VERSION ""

NS_ :

BS_:

BU_: DSAU vHS_M SHVU_RR DPSS AMP ICC RLPSM APSM RWPC RRHV RRPSM CGW_CCU APSS ATS RLHV FPM RDC PSM ASAU

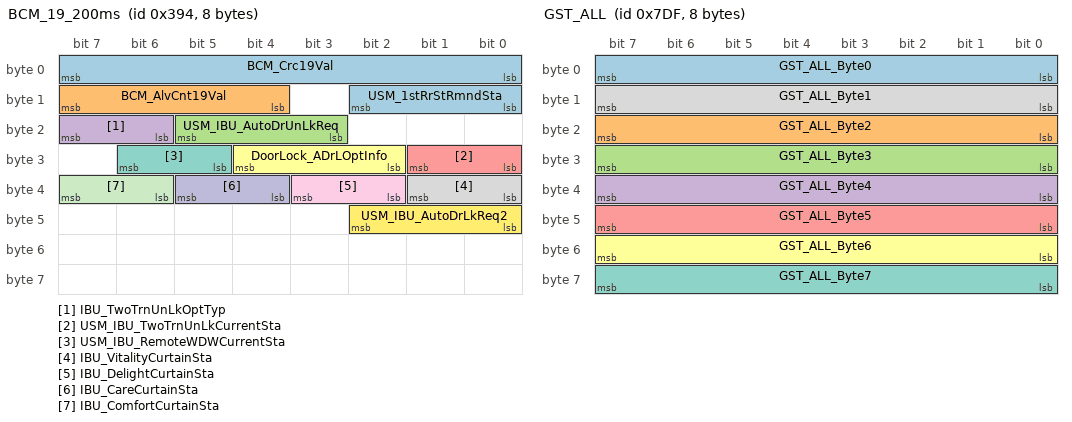
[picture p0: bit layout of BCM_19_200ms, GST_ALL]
BO_ 916 BCM_19_200ms: 8 CGW_CCU
 SG_ BCM_Crc19Val : 0|8@1+ (1,0) [0|0] ""  Vector__XXX
 SG_ BCM_AlvCnt19Val : 12|4@1+ (1,0) [0|0] ""  Vector__XXX
 SG_ USM_IBU_AutoDrUnLkReq : 19|3@1+ (1,0) [0|0] ""  Vector__XXX
 SG_ IBU_TwoTrnUnLkOptTyp : 22|2@1+ (1,0) [0|0] ""  Vector__XXX
 SG_ USM_IBU_TwoTrnUnLkCurrentSta : 24|2@1+ (1,0) [0|0] ""  Vector__XXX
 SG_ DoorLock_ADrLOptInfo : 26|3@1+ (1,0) [0|0] ""  Vector__XXX
 SG_ USM_IBU_RemoteWDWCurrentSta : 29|2@1+ (1,0) [0|0] ""  RDC
 SG_ IBU_VitalityCurtainSta : 32|2@1+ (1,0) [0|0] ""  RDC
 SG_ IBU_DelightCurtainSta : 34|2@1+ (1,0) [0|0] ""  RDC
 SG_ IBU_CareCurtainSta : 36|2@1+ (1,0) [0|0] ""  RDC
 SG_ IBU_ComfortCurtainSta : 38|2@1+ (1,0) [0|0] ""  RDC
 SG_ USM_IBU_AutoDrLkReq2 : 40|3@1+ (1,0) [0|0] ""  Vector__XXX
 SG_ USM_1stRrStRmndSta : 8|3@1+ (1,0) [0|0] ""  Vector__XXX

BO_ 2015 GST_ALL: 8 CGW_CCU
 SG_ GST_ALL_Byte0 : 0|8@1+ (1,0) [0|0] ""  RWPC,PSM,APSM,RLPSM,RRPSM,RLHV,RRHV,SHVU_RR,RDC,DPSS,AMP,vHS_M,APSS,FPM,ATS,DSAU,ASAU
 SG_ GST_ALL_Byte2 : 16|8@1+ (1,0) [0|0] ""  RWPC,PSM,APSM,RLPSM,RRPSM,RLHV,RRHV,SHVU_RR,RDC,DPSS,AMP,vHS_M,APSS,FPM,ATS,DSAU,ASAU
 SG_ GST_ALL_Byte3 : 24|8@1+ (1,0) [0|0] ""  RWPC,PSM,APSM,RLPSM,RRPSM,RLHV,RRHV,SHVU_RR,RDC,DPSS,AMP,vHS_M,APSS,FPM,ATS,DSAU,ASAU
 SG_ GST_ALL_Byte4 : 32|8@1+ (1,0) [0|0] ""  RWPC,PSM,APSM,RLPSM,RRPSM,RLHV,RRHV,SHVU_RR,RDC,DPSS,AMP,vHS_M,APSS,FPM,ATS,DSAU,ASAU
 SG_ GST_ALL_Byte5 : 40|8@1+ (1,0) [0|0] ""  RWPC,PSM,APSM,RLPSM,RRPSM,RLHV,RRHV,SHVU_RR,RDC,DPSS,AMP,vHS_M,APSS,FPM,ATS,DSAU,ASAU
 SG_ GST_ALL_Byte6 : 48|8@1+ (1,0) [0|0] ""  RWPC,PSM,APSM,RLPSM,RRPSM,RLHV,RRHV,SHVU_RR,RDC,DPSS,AMP,vHS_M,APSS,FPM,ATS,DSAU,ASAU
 SG_ GST_ALL_Byte7 : 56|8@1+ (1,0) [0|0] ""  RWPC,PSM,APSM,RLPSM,RRPSM,RLHV,RRHV,SHVU_RR,RDC,DPSS,AMP,vHS_M,APSS,FPM,ATS,DSAU,ASAU
 SG_ GST_ALL_Byte1 : 8|8@1+ (1,0) [0|0] ""  RWPC,PSM,APSM,RLPSM,RRPSM,RLHV,RRHV,SHVU_RR,RDC,DPSS,AMP,vHS_M,APSS,FPM,ATS,DSAU,ASAU

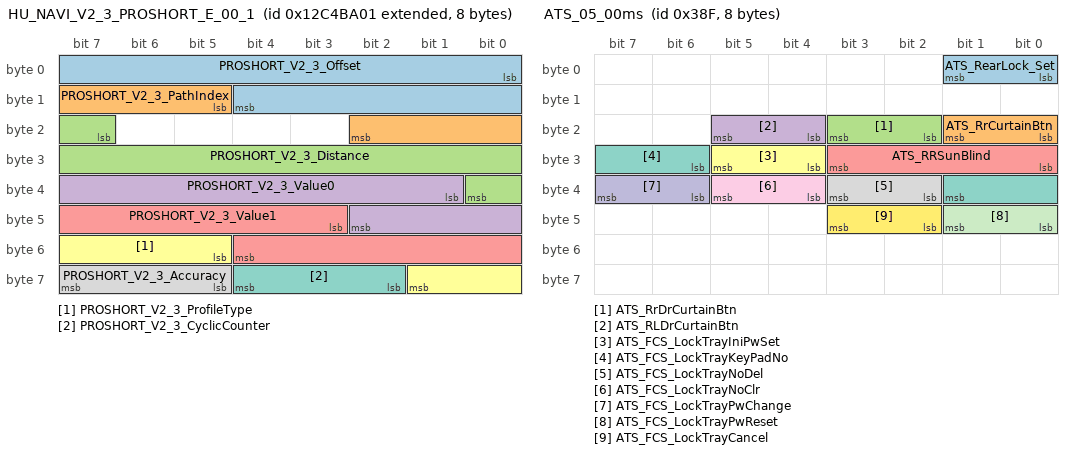
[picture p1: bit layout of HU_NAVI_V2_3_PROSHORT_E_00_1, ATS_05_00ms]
BO_ 2462366209 HU_NAVI_V2_3_PROSHORT_E_00_1: 8 CGW_CCU
 SG_ PROSHORT_V2_3_Offset : 0|13@1+ (1,0) [0|0] "m"  DSAU
 SG_ PROSHORT_V2_3_PathIndex : 13|6@1+ (1,0) [0|0] ""  Vector__XXX
 SG_ PROSHORT_V2_3_Distance : 23|10@1+ (1,0) [0|0] "m"  DSAU
 SG_ PROSHORT_V2_3_Value0 : 33|10@1+ (1,0) [0|0] ""  DSAU
 SG_ PROSHORT_V2_3_Value1 : 43|10@1+ (1,0) [0|0] ""  DSAU
 SG_ PROSHORT_V2_3_ProfileType : 53|5@1+ (1,0) [0|0] ""  DSAU
 SG_ PROSHORT_V2_3_CyclicCounter : 58|3@1+ (1,0) [0|0] ""  DSAU
 SG_ PROSHORT_V2_3_Accuracy : 61|3@1+ (1,0) [0|0] ""  Vector__XXX

BO_ 911 ATS_05_00ms: 8 ATS
 SG_ ATS_RearLock_Set : 0|2@1+ (1,0) [0|0] ""  CGW_CCU
 SG_ ATS_RrCurtainBtn : 16|2@1+ (1,0) [0|0] ""  CGW_CCU
 SG_ ATS_RrDrCurtainBtn : 18|2@1+ (1,0) [0|0] ""  RDC
 SG_ ATS_RLDrCurtainBtn : 20|2@1+ (1,0) [0|0] ""  RDC
 SG_ ATS_RRSunBlind : 24|4@1+ (1,0) [0|0] ""  CGW_CCU
 SG_ ATS_FCS_LockTrayIniPwSet : 28|2@1+ (1,0) [0|0] ""  Vector__XXX
 SG_ ATS_FCS_LockTrayKeyPadNo : 30|4@1+ (1,0) [0|0] ""  Vector__XXX
 SG_ ATS_FCS_LockTrayNoDel : 34|2@1+ (1,0) [0|0] ""  Vector__XXX
 SG_ ATS_FCS_LockTrayNoClr : 36|2@1+ (1,0) [0|0] ""  Vector__XXX
 SG_ ATS_FCS_LockTrayPwChange : 38|2@1+ (1,0) [0|0] ""  Vector__XXX
 SG_ ATS_FCS_LockTrayPwReset : 40|2@1+ (1,0) [0|0] ""  Vector__XXX
 SG_ ATS_FCS_LockTrayCancel : 42|2@1+ (1,0) [0|0] ""  Vector__XXX

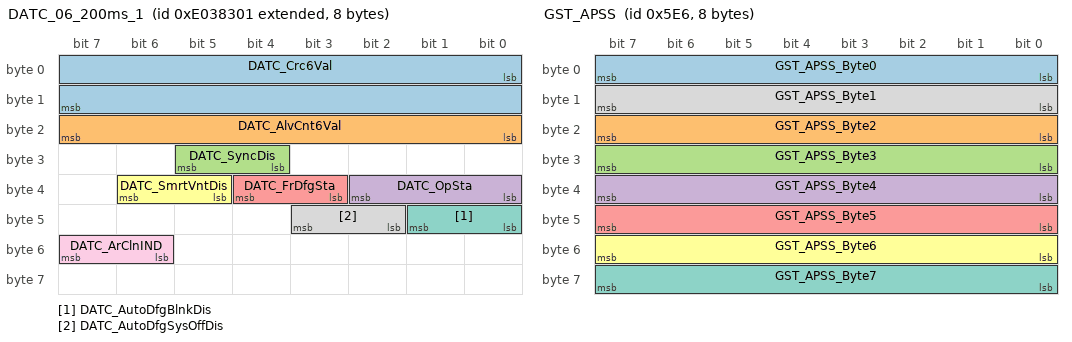
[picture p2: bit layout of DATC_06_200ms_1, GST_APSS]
BO_ 2382594817 DATC_06_200ms_1: 8 CGW_CCU
 SG_ DATC_Crc6Val : 0|16@1+ (1,0) [0|0] ""  Vector__XXX
 SG_ DATC_AlvCnt6Val : 16|8@1+ (1,0) [0|0] ""  Vector__XXX
 SG_ DATC_SyncDis : 28|2@1+ (1,0) [0|0] ""  ATS
 SG_ DATC_OpSta : 32|3@1+ (1,0) [0|0] ""  ATS
 SG_ DATC_FrDfgSta : 35|2@1+ (1,0) [0|0] ""  Vector__XXX
 SG_ DATC_SmrtVntDis : 37|2@1+ (1,0) [0|0] ""  Vector__XXX
 SG_ DATC_AutoDfgBlnkDis : 40|2@1+ (1,0) [0|0] ""  Vector__XXX
 SG_ DATC_AutoDfgSysOffDis : 42|2@1+ (1,0) [0|0] ""  Vector__XXX
 SG_ DATC_ArClnIND : 54|2@1+ (1,0) [0|0] ""  ATS

BO_ 1510 GST_APSS: 8 CGW_CCU
 SG_ GST_APSS_Byte0 : 0|8@1+ (1,0) [0|0] ""  vHS_M,APSS
 SG_ GST_APSS_Byte2 : 16|8@1+ (1,0) [0|0] ""  vHS_M,APSS
 SG_ GST_APSS_Byte3 : 24|8@1+ (1,0) [0|0] ""  vHS_M,APSS
 SG_ GST_APSS_Byte4 : 32|8@1+ (1,0) [0|0] ""  vHS_M,APSS
 SG_ GST_APSS_Byte5 : 40|8@1+ (1,0) [0|0] ""  vHS_M,APSS
 SG_ GST_APSS_Byte6 : 48|8@1+ (1,0) [0|0] ""  vHS_M,APSS
 SG_ GST_APSS_Byte7 : 56|8@1+ (1,0) [0|0] ""  vHS_M,APSS
 SG_ GST_APSS_Byte1 : 8|8@1+ (1,0) [0|0] ""  vHS_M,APSS

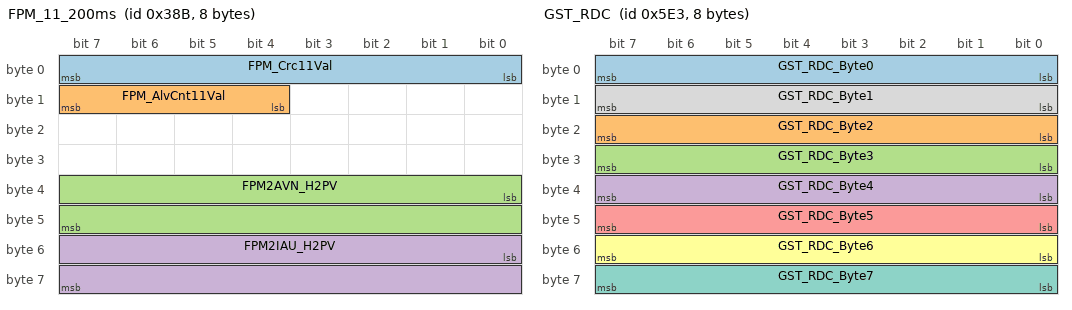
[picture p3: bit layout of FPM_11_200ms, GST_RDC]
BO_ 907 FPM_11_200ms: 8 FPM
 SG_ FPM_Crc11Val : 0|8@1+ (1,0) [0|0] ""  Vector__XXX
 SG_ FPM_AlvCnt11Val : 12|4@1+ (1,0) [0|0] ""  Vector__XXX
 SG_ FPM2AVN_H2PV : 32|16@1+ (1,0) [0|0] ""  CGW_CCU
 SG_ FPM2IAU_H2PV : 48|16@1+ (1,0) [0|0] ""  CGW_CCU

BO_ 905 SBCM_RR_01_200ms: 8 CGW_CCU
 SG_ SBCM_RR_Crc1Val : 0|8@1+ (1,0) [0|0] ""  Vector__XXX
 SG_ RR_CrashUnlockCmd : 10|1@1+ (1,0) [0|0] ""  Vector__XXX
 SG_ SBCM_RR_AlvCnt1Val : 12|4@1+ (1,0) [0|0] ""  Vector__XXX
 SG_ Warn_RrRtDrSwSta_SBCM : 16|2@1+ (1,0) [0|0] ""  RWPC,RLPSM,RRPSM,AMP,ATS
 SG_ DoorLock_RrRtDrUnLkSta_SBCM : 18|2@1+ (1,0) [0|0] ""  ATS
 SG_ RR_SEAActivated : 20|2@1+ (1,0) [0|0] ""  Vector__XXX
 SG_ RR_SEAWarn : 22|2@1+ (1,0) [0|0] ""  AMP
 SG_ RR_SEWWarn : 24|2@1+ (1,0) [0|0] ""  AMP
 SG_ RR_ReleaseWarn : 26|2@1+ (1,0) [0|0] ""  Vector__XXX
 SG_ RR_SWFailAlarm : 28|2@1+ (1,0) [0|0] ""  Vector__XXX
 SG_ RR_ChildLock_ActnFlSta : 30|2@1+ (1,0) [0|0] ""  Vector__XXX
 SG_ RR_MRActivationAlarm : 32|2@1+ (1,0) [0|0] ""  Vector__XXX
 SG_ RR_ChildLock_Status : 34|2@1+ (1,0) [0|0] ""  Vector__XXX
 SG_ USM_RRGhostDoorSta : 36|2@1+ (1,0) [0|0] ""  Vector__XXX
 SG_ DoorLock_PDSLkSwSta_RR : 40|2@1+ (1,0) [0|0] ""  AMP
 SG_ PDS_TypeOption_RR : 42|2@1+ (1,0) [0|0] ""  Vector__XXX
 SG_ SBCM_RrRrClsSwSta : 44|2@1+ (1,0) [0|0] ""  Vector__XXX
 SG_ RRDoorPushAlarm : 8|2@1+ (1,0) [0|0] ""  Vector__XXX

BO_ 1507 GST_RDC: 8 CGW_CCU
 SG_ GST_RDC_Byte0 : 0|8@1+ (1,0) [0|0] ""  RDC,vHS_M
 SG_ GST_RDC_Byte2 : 16|8@1+ (1,0) [0|0] ""  RDC,vHS_M
 SG_ GST_RDC_Byte3 : 24|8@1+ (1,0) [0|0] ""  RDC,vHS_M
 SG_ GST_RDC_Byte4 : 32|8@1+ (1,0) [0|0] ""  RDC,vHS_M
 SG_ GST_RDC_Byte5 : 40|8@1+ (1,0) [0|0] ""  RDC,vHS_M
 SG_ GST_RDC_Byte6 : 48|8@1+ (1,0) [0|0] ""  RDC,vHS_M
 SG_ GST_RDC_Byte7 : 56|8@1+ (1,0) [0|0] ""  RDC,vHS_M
 SG_ GST_RDC_Byte1 : 8|8@1+ (1,0) [0|0] ""  RDC,vHS_M

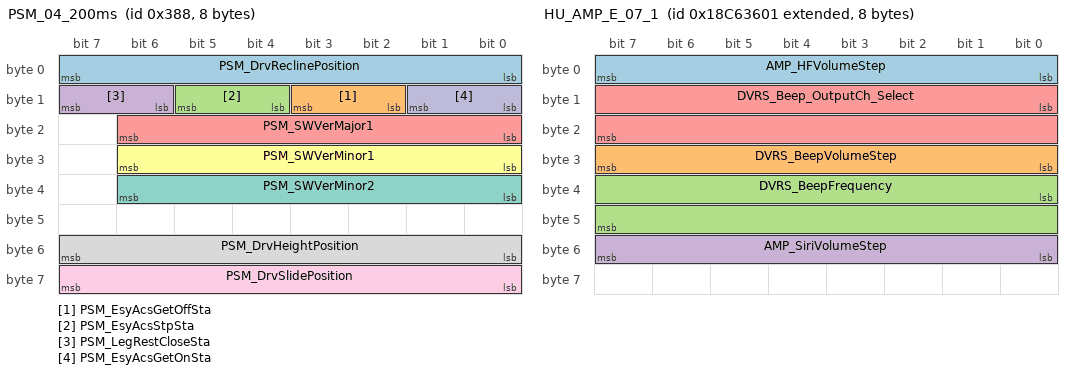
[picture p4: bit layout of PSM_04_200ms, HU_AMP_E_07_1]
BO_ 904 PSM_04_200ms: 8 PSM
 SG_ PSM_DrvReclinePosition : 0|8@1+ (1,0) [0|0] ""  RLPSM,CGW_CCU
 SG_ PSM_EsyAcsGetOffSta : 10|2@1+ (1,0) [0|0] ""  DSAU
 SG_ PSM_EsyAcsStpSta : 12|2@1+ (1,0) [0|0] ""  DSAU
 SG_ PSM_LegRestCloseSta : 14|2@1+ (1,0) [0|0] ""  RLPSM
 SG_ PSM_SWVerMajor1 : 16|7@1+ (1,0) [0|0] ""  CGW_CCU
 SG_ PSM_SWVerMinor1 : 24|7@1+ (1,0) [0|0] ""  CGW_CCU
 SG_ PSM_SWVerMinor2 : 32|7@1+ (1,0) [0|0] ""  CGW_CCU
 SG_ PSM_DrvHeightPosition : 48|8@1+ (1,0) [0|0] ""  CGW_CCU
 SG_ PSM_DrvSlidePosition : 56|8@1+ (1,0) [0|0] ""  RLPSM,CGW_CCU
 SG_ PSM_EsyAcsGetOnSta : 8|2@1+ (1,0) [0|0] ""  DSAU

BO_ 2563126785 HU_AMP_E_07_1: 8 CGW_CCU
 SG_ AMP_HFVolumeStep : 0|8@1+ (1,0) [0|0] ""  AMP
 SG_ DVRS_BeepVolumeStep : 24|8@1+ (1,0) [0|0] ""  AMP
 SG_ DVRS_BeepFrequency : 32|16@1+ (1,0) [0|0] "Hz"  AMP
 SG_ AMP_SiriVolumeStep : 48|8@1+ (1,0) [0|0] ""  AMP
 SG_ DVRS_Beep_OutputCh_Select : 8|16@1+ (1,0) [0|0] ""  AMP

BO_ 903 PSM_03_200ms: 8 PSM
 SG_ PSM_DrvStSldFwdDis : 0|2@1+ (1,0) [0|0] ""  DPSS,CGW_CCU
 SG_ PSM_DrvStTiltDnDis : 10|2@1+ (1,0) [0|0] ""  DPSS,CGW_CCU
 SG_ PSM_DrvStHghtUpDis : 12|2@1+ (1,0) [0|0] ""  DPSS,CGW_CCU
 SG_ PSM_DrvStHghtDnDis : 14|2@1+ (1,0) [0|0] ""  DPSS,CGW_CCU
 SG_ PSM_DrvStCushExtBckwdDis : 16|2@1+ (1,0) [0|0] ""  DPSS,CGW_CCU
 SG_ PSM_DrvStCushExtFwdDis : 18|2@1+ (1,0) [0|0] ""  DPSS,CGW_CCU
 SG_ PSM_DrvStSldBckwdDis : 2|2@1+ (1,0) [0|0] ""  DPSS,CGW_CCU
 SG_ PSM_DrvStHdRstUpDis : 20|2@1+ (1,0) [0|0] ""  CGW_CCU
 SG_ PSM_DrvStHdRstDnDis : 22|2@1+ (1,0) [0|0] ""  CGW_CCU
 SG_ PSM_DrvStHdRstFwdDis : 24|2@1+ (1,0) [0|0] ""  CGW_CCU
 SG_ PSM_DrvStHdRstBckwdDis : 26|2@1+ (1,0) [0|0] ""  CGW_CCU
 SG_ PSM_DrvStLmbrDefDis : 32|2@1+ (1,0) [0|0] ""  DPSS,CGW_CCU
 SG_ PSM_DrvStLmbrLoDis : 34|2@1+ (1,0) [0|0] ""  DPSS,CGW_CCU
 SG_ PSM_DrvStLmbrMdlDis : 36|2@1+ (1,0) [0|0] ""  DPSS,CGW_CCU
 SG_ PSM_DrvStLmbrUpDis : 38|2@1+ (1,0) [0|0] ""  DPSS,CGW_CCU
 SG_ PSM_DrvStReclneFwdDis : 4|2@1+ (1,0) [0|0] ""  DPSS,CGW_CCU
 SG_ PSM_LmbrSigSrcTyp : 44|2@1+ (1,0) [0|0] ""  CGW_CCU
 SG_ PSM_DrvStReclneBckwdDis : 6|2@1+ (1,0) [0|0] ""  DPSS,CGW_CCU
 SG_ PSM_DrvStTiltUpDis : 8|2@1+ (1,0) [0|0] ""  DPSS,CGW_CCU

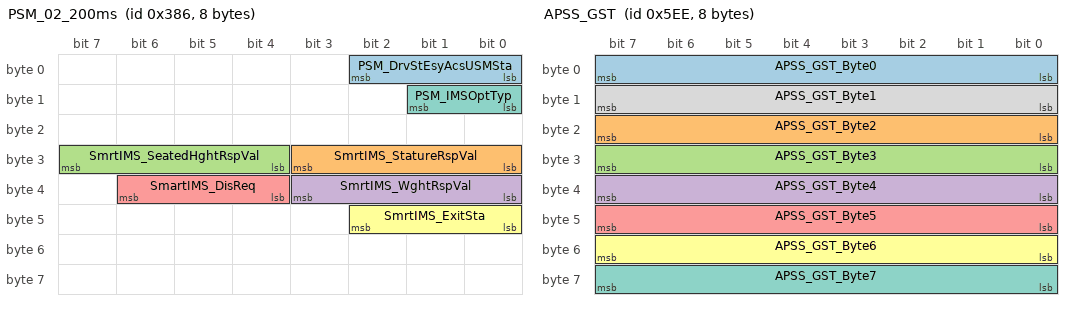
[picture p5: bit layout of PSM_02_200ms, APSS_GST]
BO_ 902 PSM_02_200ms: 8 PSM
 SG_ PSM_DrvStEsyAcsUSMSta : 0|3@1+ (1,0) [0|0] ""  DSAU,CGW_CCU
 SG_ SmrtIMS_StatureRspVal : 24|4@1+ (1,0) [0|0] ""  CGW_CCU
 SG_ SmrtIMS_SeatedHghtRspVal : 28|4@1+ (1,0) [0|0] ""  CGW_CCU
 SG_ SmrtIMS_WghtRspVal : 32|4@1+ (1,0) [0|0] ""  CGW_CCU
 SG_ SmartIMS_DisReq : 36|3@1+ (1,0) [0|0] ""  CGW_CCU
 SG_ SmrtIMS_ExitSta : 40|3@1+ (1,0) [0|0] ""  CGW_CCU
 SG_ PSM_IMSOptTyp : 8|2@1+ (1,0) [0|0] ""  CGW_CCU

BO_ 1518 APSS_GST: 8 vHS_M
 SG_ APSS_GST_Byte0 : 0|8@1+ (1,0) [0|0] ""  CGW_CCU
 SG_ APSS_GST_Byte2 : 16|8@1+ (1,0) [0|0] ""  CGW_CCU
 SG_ APSS_GST_Byte3 : 24|8@1+ (1,0) [0|0] ""  CGW_CCU
 SG_ APSS_GST_Byte4 : 32|8@1+ (1,0) [0|0] ""  CGW_CCU
 SG_ APSS_GST_Byte5 : 40|8@1+ (1,0) [0|0] ""  CGW_CCU
 SG_ APSS_GST_Byte6 : 48|8@1+ (1,0) [0|0] ""  CGW_CCU
 SG_ APSS_GST_Byte7 : 56|8@1+ (1,0) [0|0] ""  CGW_CCU
 SG_ APSS_GST_Byte1 : 8|8@1+ (1,0) [0|0] ""  CGW_CCU

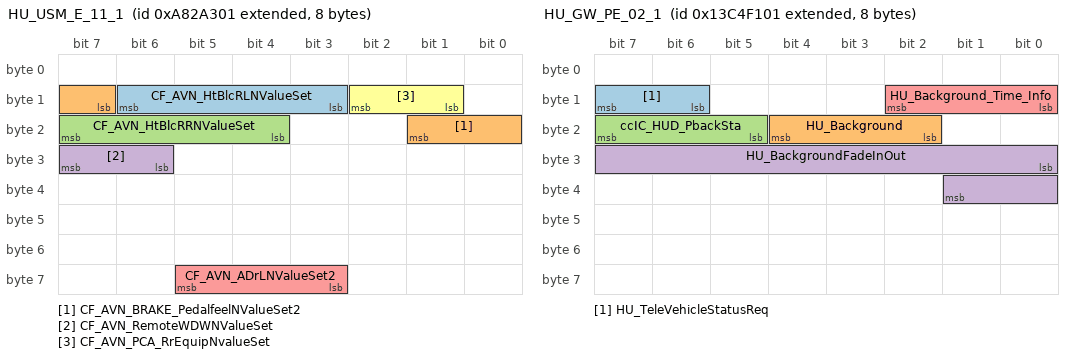
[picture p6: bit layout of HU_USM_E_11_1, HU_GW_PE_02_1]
BO_ 2323817217 HU_USM_E_11_1: 8 CGW_CCU
 SG_ CF_AVN_HtBlcRLNValueSet : 11|4@1+ (1,0) [0|0] ""  RLPSM,RRPSM,RLHV,SHVU_RR
 SG_ CF_AVN_BRAKE_PedalfeelNValueSet2 : 15|3@1+ (1,0) [0|0] ""  Vector__XXX
 SG_ CF_AVN_HtBlcRRNValueSet : 20|4@1+ (1,0) [0|0] ""  RLPSM,RRPSM,RRHV,SHVU_RR
 SG_ CF_AVN_RemoteWDWNValueSet : 30|2@1+ (1,0) [0|0] ""  Vector__XXX
 SG_ CF_AVN_ADrLNValueSet2 : 59|3@1+ (1,0) [0|0] ""  Vector__XXX
 SG_ CF_AVN_PCA_RrEquipNvalueSet : 9|2@1+ (1,0) [0|0] ""  Vector__XXX

BO_ 2479157505 HU_GW_PE_02_1: 8 CGW_CCU
 SG_ HU_TeleVehicleStatusReq : 14|2@1+ (1,0) [0|3] ""  Vector__XXX
 SG_ HU_Background : 18|3@1+ (1,0) [0|0] ""  ATS
 SG_ ccIC_HUD_PbackSta : 21|3@1+ (1,0) [0|0] ""  PSM
 SG_ HU_BackgroundFadeInOut : 24|10@1+ (0.1,0) [0|0] "%"  ATS
 SG_ HU_Background_Time_Info : 8|3@1+ (1,0) [0|0] ""  Vector__XXX

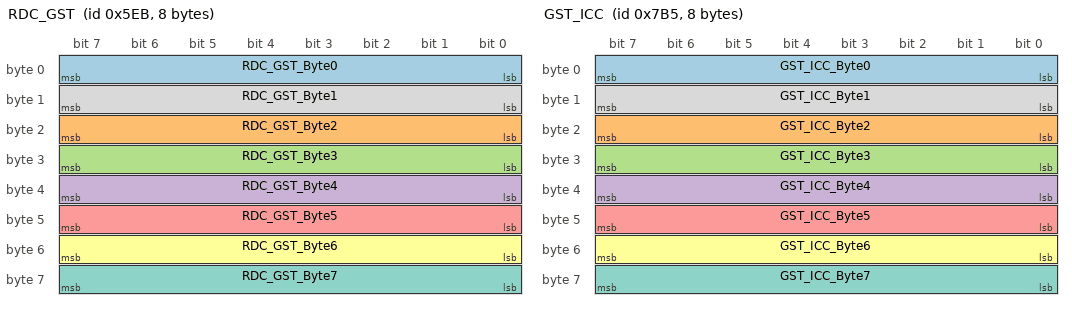
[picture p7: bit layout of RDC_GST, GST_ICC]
BO_ 1515 RDC_GST: 8 vHS_M
 SG_ RDC_GST_Byte0 : 0|8@1+ (1,0) [0|0] ""  CGW_CCU
 SG_ RDC_GST_Byte2 : 16|8@1+ (1,0) [0|0] ""  CGW_CCU
 SG_ RDC_GST_Byte3 : 24|8@1+ (1,0) [0|0] ""  CGW_CCU
 SG_ RDC_GST_Byte4 : 32|8@1+ (1,0) [0|0] ""  CGW_CCU
 SG_ RDC_GST_Byte5 : 40|8@1+ (1,0) [0|0] ""  CGW_CCU
 SG_ RDC_GST_Byte6 : 48|8@1+ (1,0) [0|0] ""  CGW_CCU
 SG_ RDC_GST_Byte7 : 56|8@1+ (1,0) [0|0] ""  CGW_CCU
 SG_ RDC_GST_Byte1 : 8|8@1+ (1,0) [0|0] ""  CGW_CCU

BO_ 1973 GST_ICC: 8 CGW_CCU
 SG_ GST_ICC_Byte0 : 0|8@1+ (1,0) [0|0] ""  vHS_M,ICC
 SG_ GST_ICC_Byte2 : 16|8@1+ (1,0) [0|0] ""  vHS_M,ICC
 SG_ GST_ICC_Byte3 : 24|8@1+ (1,0) [0|0] ""  vHS_M,ICC
 SG_ GST_ICC_Byte4 : 32|8@1+ (1,0) [0|0] ""  vHS_M,ICC
 SG_ GST_ICC_Byte5 : 40|8@1+ (1,0) [0|0] ""  vHS_M,ICC
 SG_ GST_ICC_Byte6 : 48|8@1+ (1,0) [0|0] ""  vHS_M,ICC
 SG_ GST_ICC_Byte7 : 56|8@1+ (1,0) [0|0] ""  vHS_M,ICC
 SG_ GST_ICC_Byte1 : 8|8@1+ (1,0) [0|0] ""  vHS_M,ICC

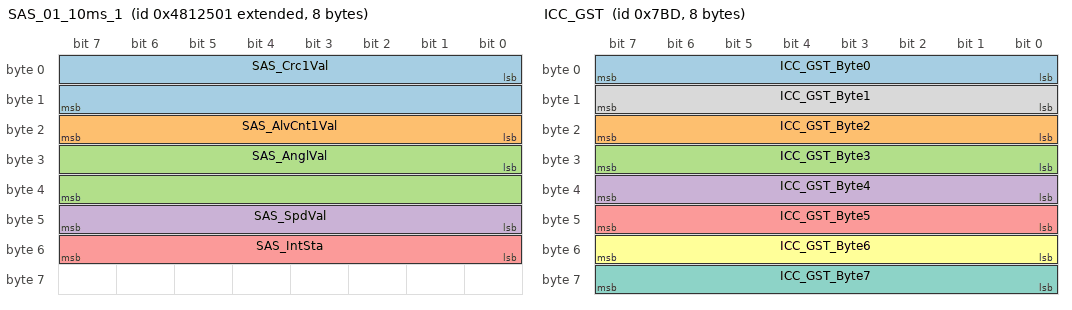
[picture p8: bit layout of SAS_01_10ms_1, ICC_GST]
BO_ 2223056129 SAS_01_10ms_1: 8 CGW_CCU
 SG_ SAS_Crc1Val : 0|16@1+ (1,0) [0|0] ""  Vector__XXX
 SG_ SAS_AlvCnt1Val : 16|8@1+ (1,0) [0|0] ""  Vector__XXX
 SG_ SAS_AnglVal : 24|16@1- (0.1,0) [0|0] "Deg"  ICC
 SG_ SAS_SpdVal : 40|8@1+ (4,0) [0|0] "Deg/s"  Vector__XXX
 SG_ SAS_IntSta : 48|8@1+ (1,0) [0|0] ""  Vector__XXX

BO_ 2223056130 SAS_01_10ms_2: 8 CGW_CCU

BO_ 1981 ICC_GST: 8 vHS_M
 SG_ ICC_GST_Byte0 : 0|8@1+ (1,0) [0|0] ""  CGW_CCU
 SG_ ICC_GST_Byte2 : 16|8@1+ (1,0) [0|0] ""  CGW_CCU
 SG_ ICC_GST_Byte3 : 24|8@1+ (1,0) [0|0] ""  CGW_CCU
 SG_ ICC_GST_Byte4 : 32|8@1+ (1,0) [0|0] ""  CGW_CCU
 SG_ ICC_GST_Byte5 : 40|8@1+ (1,0) [0|0] ""  CGW_CCU
 SG_ ICC_GST_Byte6 : 48|8@1+ (1,0) [0|0] ""  CGW_CCU
 SG_ ICC_GST_Byte7 : 56|8@1+ (1,0) [0|0] ""  CGW_CCU
 SG_ ICC_GST_Byte1 : 8|8@1+ (1,0) [0|0] ""  CGW_CCU

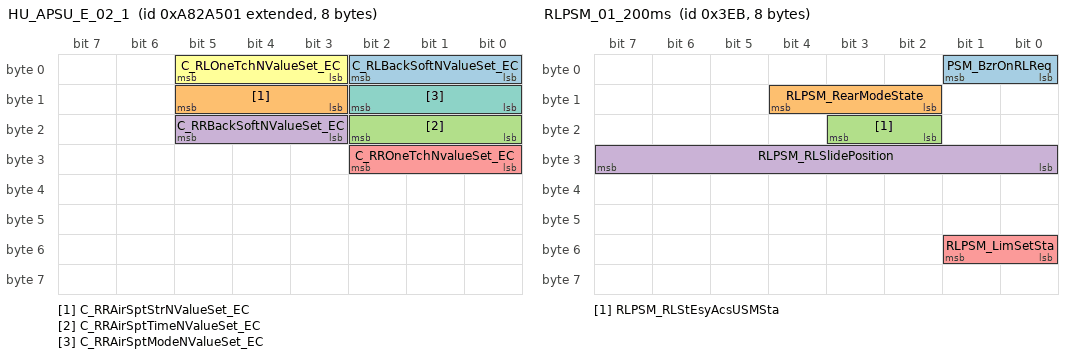
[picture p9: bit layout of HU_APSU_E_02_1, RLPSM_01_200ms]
BO_ 2323817729 HU_APSU_E_02_1: 8 CGW_CCU
 SG_ C_RLBackSoftNValueSet_EC : 0|3@1+ (1,0) [0|0] ""  RLPSM,ATS
 SG_ C_RRAirSptStrNValueSet_EC : 11|3@1+ (1,0) [0|0] ""  RLPSM,ATS
 SG_ C_RRAirSptTimeNValueSet_EC : 16|3@1+ (1,0) [0|0] ""  RLPSM,ATS
 SG_ C_RRBackSoftNValueSet_EC : 19|3@1+ (1,0) [0|0] ""  RLPSM,ATS
 SG_ C_RROneTchNvalueSet_EC : 24|3@1+ (1,0) [0|0] ""  RLPSM,RRPSM
 SG_ C_RLOneTchNValueSet_EC : 3|3@1+ (1,0) [0|0] ""  RLPSM,RRPSM
 SG_ C_RRAirSptModeNValueSet_EC : 8|3@1+ (1,0) [0|0] ""  RLPSM,ATS

BO_ 2458168065 HU_USM_E_04_1: 8 CGW_CCU
 SG_ CF_AVN_CluWelcomeSnd : 0|2@1+ (1,0) [0|0] ""  Vector__XXX
 SG_ CF_AVN_CluTransmissionDisp : 10|2@1+ (1,0) [0|0] ""  Vector__XXX
 SG_ CF_AVN_CluWiperLight : 12|2@1+ (1,0) [0|0] ""  Vector__XXX
 SG_ CF_AVN_CluRoadInfoGuide : 14|2@1+ (1,0) [0|0] ""  Vector__XXX
 SG_ CF_AVN_CluUserSettingPeriod : 17|7@1+ (1,0) [0|0] ""  Vector__XXX
 SG_ CF_AVN_CluAutoInitFuelEconomy : 2|3@1+ (1,0) [0|0] ""  Vector__XXX
 SG_ CF_AVN_CluSubspeedOdometerDisp : 25|2@1+ (1,0) [0|0] ""  Vector__XXX
 SG_ CF_AVN_CluFuelEconUnit_mi : 27|2@1+ (1,0) [0|0] ""  Vector__XXX
 SG_ CF_AVN_CluFuelEconUnit_km : 29|2@1+ (1,0) [0|0] ""  Vector__XXX
 SG_ CF_AVN_CluUserSettingDistance : 31|17@1+ (1,0) [0|0] ""  Vector__XXX
 SG_ CF_AVN_CluRheostatLvl : 49|5@1+ (1,0) [0|0] ""  Vector__XXX
 SG_ CF_AVN_CluVoiceVolume : 5|3@1+ (1,0) [0|0] ""  Vector__XXX
 SG_ CF_AVN_EVReset : 54|2@1+ (1,0) [0|0] ""  Vector__XXX
 SG_ CF_AVN_UnitReset : 56|2@1+ (1,0) [0|0] ""  Vector__XXX
 SG_ CF_AVN_IcyRoadWarn : 58|2@1+ (1,0) [0|0] ""  Vector__XXX
 SG_ CF_AVN_CluServiceReminderReset : 60|2@1+ (1,0) [0|0] ""  Vector__XXX
 SG_ CF_AVN_CluUSMReset : 62|2@1+ (1,0) [0|0] ""  RWPC,PSM,APSM,RLPSM,RRPSM,RLHV,RRHV,SHVU_RR,DPSS,APSS,ATS,DSAU,ASAU
 SG_ CF_AVN_CluServiceReminderSet : 8|2@1+ (1,0) [0|0] ""  Vector__XXX

BO_ 1003 RLPSM_01_200ms: 8 RLPSM
 SG_ PSM_BzrOnRLReq : 0|2@1+ (1,0) [0|0] ""  ATS,PSM
 SG_ RLPSM_RearModeState : 10|3@1+ (1,0) [0|0] ""  ATS,PSM,RDC,CGW_CCU
 SG_ RLPSM_RLStEsyAcsUSMSta : 18|2@1+ (1,0) [0|0] ""  ATS,CGW_CCU
 SG_ RLPSM_RLSlidePosition : 24|8@1+ (1,0) [0|0] ""  PSM
 SG_ RLPSM_LimSetSta : 48|2@1+ (1,0) [0|0] ""  ATS

BO_ 2449770241 HU_APSU_PE_01_1: 8 CGW_CCU
 SG_ C_AstRclBwdSw_HU : 0|2@1+ (1,0) [0|0] ""  APSM,RRPSM,APSS
 SG_ C_AstHeightUpSw_HU : 10|2@1+ (1,0) [0|0] ""  APSM,RRPSM,APSS
 SG_ C_AstTiltDnSw_HU : 12|2@1+ (1,0) [0|0] ""  APSM,APSS
 SG_ C_AstTiltUpSw_HU : 14|2@1+ (1,0) [0|0] ""  APSM,APSS
 SG_ C_AstLumbarDefSw_HU : 16|2@1+ (1,0) [0|0] ""  APSS,ASAU
 SG_ C_AstLumbarLowSw_HU : 18|2@1+ (1,0) [0|0] ""  APSS,ASAU
 SG_ C_AstRclFwdSw_HU : 2|2@1+ (1,0) [0|0] ""  APSM,RRPSM,APSS
 SG_ C_AstLumbarMidSw_HU : 20|2@1+ (1,0) [0|0] ""  APSS,ASAU
 SG_ C_AstLumbarUpSw_HU : 22|2@1+ (1,0) [0|0] ""  APSS,ASAU
 SG_ C_RRSlideFwdSw_HU : 24|2@1+ (1,0) [0|0] ""  RRPSM
 SG_ C_RRSlideBwdSw_HU : 26|2@1+ (1,0) [0|0] ""  RRPSM
 SG_ C_RLSlideFwdSw_HU : 28|2@1+ (1,0) [0|0] ""  RLPSM
 SG_ C_RLSlideBwdSw_HU : 30|2@1+ (1,0) [0|0] ""  RLPSM
 SG_ C_AstSlideBwdSw_HU : 4|2@1+ (1,0) [0|0] ""  APSM,RRPSM,APSS
 SG_ C_AstRlxNValueSet : 50|3@1+ (1,0) [0|0] ""  APSM,APSS
 SG_ C_AstSlideFwdSw_HU : 6|2@1+ (1,0) [0|0] ""  APSM,RRPSM,APSS
 SG_ C_AstHeightDnSw_HU : 8|2@1+ (1,0) [0|0] ""  APSM,RRPSM,APSS

BO_ 2470763265 CLU_10_00ms_1: 8 CGW_CCU
 SG_ USM_AdasDSWSetReq : 59|2@1+ (1,0) [0|0] ""  ICC

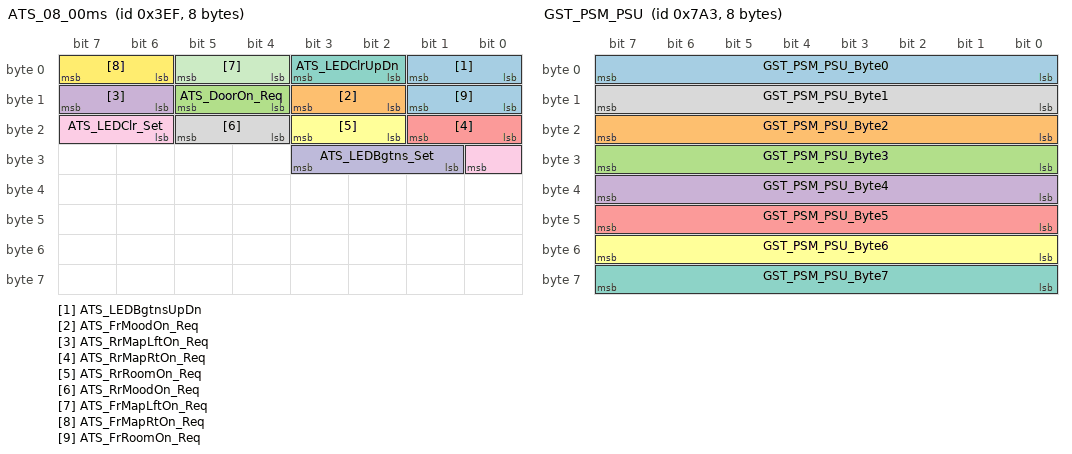
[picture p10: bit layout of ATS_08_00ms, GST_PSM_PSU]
BO_ 1007 ATS_08_00ms: 8 ATS
 SG_ ATS_LEDBgtnsUpDn : 0|2@1+ (1,0) [0|0] ""  CGW_CCU
 SG_ ATS_FrMoodOn_Req : 10|2@1+ (1,0) [0|0] ""  CGW_CCU
 SG_ ATS_DoorOn_Req : 12|2@1+ (1,0) [0|0] ""  CGW_CCU
 SG_ ATS_RrMapLftOn_Req : 14|2@1+ (1,0) [0|0] ""  CGW_CCU
 SG_ ATS_RrMapRtOn_Req : 16|2@1+ (1,0) [0|0] ""  CGW_CCU
 SG_ ATS_RrRoomOn_Req : 18|2@1+ (1,0) [0|0] ""  CGW_CCU
 SG_ ATS_LEDClrUpDn : 2|2@1+ (1,0) [0|0] ""  CGW_CCU
 SG_ ATS_RrMoodOn_Req : 20|2@1+ (1,0) [0|0] ""  CGW_CCU
 SG_ ATS_LEDClr_Set : 22|3@1+ (1,0) [0|0] ""  CGW_CCU
 SG_ ATS_LEDBgtns_Set : 25|3@1+ (1,0) [0|0] ""  CGW_CCU
 SG_ ATS_FrMapLftOn_Req : 4|2@1+ (1,0) [0|0] ""  CGW_CCU
 SG_ ATS_FrMapRtOn_Req : 6|2@1+ (1,0) [0|0] ""  CGW_CCU
 SG_ ATS_FrRoomOn_Req : 8|2@1+ (1,0) [0|0] ""  CGW_CCU

BO_ 1955 GST_PSM_PSU: 8 CGW_CCU
 SG_ GST_PSM_PSU_Byte0 : 0|8@1+ (1,0) [0|0] ""  PSM,vHS_M
 SG_ GST_PSM_PSU_Byte2 : 16|8@1+ (1,0) [0|0] ""  PSM,vHS_M
 SG_ GST_PSM_PSU_Byte3 : 24|8@1+ (1,0) [0|0] ""  PSM,vHS_M
 SG_ GST_PSM_PSU_Byte4 : 32|8@1+ (1,0) [0|0] ""  PSM,vHS_M
 SG_ GST_PSM_PSU_Byte5 : 40|8@1+ (1,0) [0|0] ""  PSM,vHS_M
 SG_ GST_PSM_PSU_Byte6 : 48|8@1+ (1,0) [0|0] ""  PSM,vHS_M
 SG_ GST_PSM_PSU_Byte7 : 56|8@1+ (1,0) [0|0] ""  PSM,vHS_M
 SG_ GST_PSM_PSU_Byte1 : 8|8@1+ (1,0) [0|0] ""  PSM,vHS_M

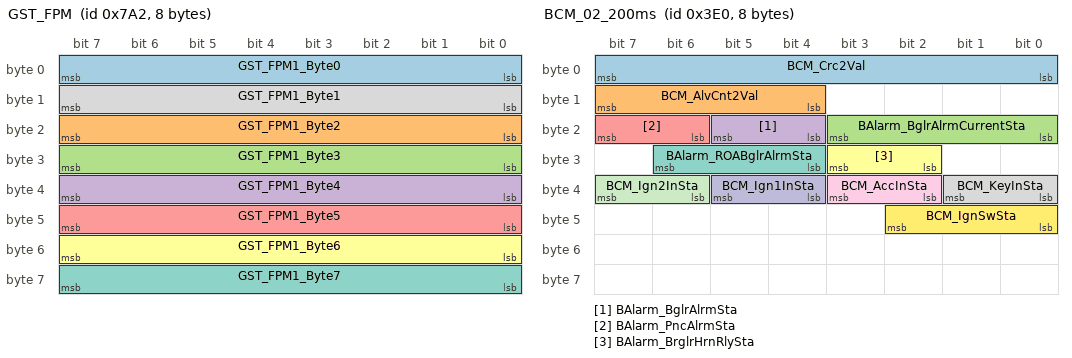
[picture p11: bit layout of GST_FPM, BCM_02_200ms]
BO_ 1954 GST_FPM: 8 CGW_CCU
 SG_ GST_FPM1_Byte0 : 0|8@1+ (1,0) [0|0] ""  vHS_M,FPM
 SG_ GST_FPM1_Byte2 : 16|8@1+ (1,0) [0|0] ""  vHS_M,FPM
 SG_ GST_FPM1_Byte3 : 24|8@1+ (1,0) [0|0] ""  vHS_M,FPM
 SG_ GST_FPM1_Byte4 : 32|8@1+ (1,0) [0|0] ""  vHS_M,FPM
 SG_ GST_FPM1_Byte5 : 40|8@1+ (1,0) [0|0] ""  vHS_M,FPM
 SG_ GST_FPM1_Byte6 : 48|8@1+ (1,0) [0|0] ""  vHS_M,FPM
 SG_ GST_FPM1_Byte7 : 56|8@1+ (1,0) [0|0] ""  vHS_M,FPM
 SG_ GST_FPM1_Byte1 : 8|8@1+ (1,0) [0|0] ""  vHS_M,FPM

BO_ 992 BCM_02_200ms: 8 CGW_CCU
 SG_ BCM_Crc2Val : 0|8@1+ (1,0) [0|0] ""  Vector__XXX
 SG_ BCM_AlvCnt2Val : 12|4@1+ (1,0) [0|0] ""  Vector__XXX
 SG_ BAlarm_BglrAlrmCurrentSta : 16|4@1+ (1,0) [0|0] ""  Vector__XXX
 SG_ BAlarm_BglrAlrmSta : 20|2@1+ (1,0) [0|0] ""  Vector__XXX
 SG_ BAlarm_PncAlrmSta : 22|2@1+ (1,0) [0|0] ""  Vector__XXX
 SG_ BAlarm_BrglrHrnRlySta : 26|2@1+ (1,0) [0|0] ""  Vector__XXX
 SG_ BAlarm_ROABglrAlrmSta : 28|3@1+ (1,0) [0|0] ""  Vector__XXX
 SG_ BCM_KeyInSta : 32|2@1+ (1,0) [0|0] ""  Vector__XXX
 SG_ BCM_AccInSta : 34|2@1+ (1,0) [0|0] ""  PSM,APSM,RLPSM,RRPSM,RDC,ATS,DSAU,ASAU
 SG_ BCM_Ign1InSta : 36|2@1+ (1,0) [0|0] ""  PSM,APSM,RLPSM,RRPSM,RDC,ATS,DSAU,ASAU
 SG_ BCM_Ign2InSta : 38|2@1+ (1,0) [0|0] ""  PSM,APSM,RLPSM,RRPSM,RLHV,RRHV,SHVU_RR,RDC,ATS,DSAU,ASAU
 SG_ BCM_IgnSwSta : 40|3@1+ (1,0) [0|0] ""  RWPC,PSM,APSM,RLPSM,RRPSM,SHVU_RR,RDC,DPSS,APSS,ATS,DSAU,ASAU

BO_TX_BU_ 1981 : vHS_M,ICC;
BO_TX_BU_ 1518 : vHS_M,APSS;
BO_TX_BU_ 1515 : vHS_M,RDC;
CM_ BO_ 1518 "[TP] Transport Protocol";
CM_ BO_ 911 "[EC] On Event and On Change";
CM_ SG_ 911 ATS_RearLock_Set "RRC and RSE Lock Touch Button";
CM_ SG_ 911 ATS_RrCurtainBtn "Rear Curtain Touch Button";
CM_ SG_ 911 ATS_RrDrCurtainBtn "Rear Door and Curtain Touch Button";
CM_ SG_ 911 ATS_RLDrCurtainBtn "Rear Door and Curtain Touch Button";
CM_ SG_ 911 ATS_RRSunBlind "SunBlind Touch Botton";
CM_ SG_ 911 ATS_FCS_LockTrayIniPwSet "Locking Tray 비밀번호 설정 진입 버튼";
CM_ SG_ 911 ATS_FCS_LockTrayKeyPadNo "Locking Tray 비밀번호 설정 key Pad 버튼";
CM_ SG_ 911 ATS_FCS_LockTrayNoDel "Locking Tray 비밀번호 설정 숫자 삭제 버튼";
CM_ SG_ 911 ATS_FCS_LockTrayNoClr "Locking Tray 비밀번호 설정 숫자 Clear 버튼";
CM_ SG_ 911 ATS_FCS_LockTrayPwChange "Locking Tray 비밀번호 변경 진입 버튼";
CM_ SG_ 911 ATS_FCS_LockTrayPwReset "Locking Tray 비밀번호 초기화 진입 버튼 (비밀번호 없는 상태로 원복)";
CM_ SG_ 911 ATS_FCS_LockTrayCancel "Locking Tray 비밀번호 입력 화면 Cancel 버튼";
CM_ BO_ 1007 "[EC] On Event and On Change";
CM_ SG_ 1007 ATS_LEDBgtnsUpDn "Interior Light Brightness Up/Down Request";
CM_ SG_ 1007 ATS_FrMoodOn_Req "Front mood lamp On/Off request";
CM_ SG_ 1007 ATS_DoorOn_Req "Front Door switch On/Off request";
CM_ SG_ 1007 ATS_RrMapLftOn_Req "Rear left map lamp On/Off request";
CM_ SG_ 1007 ATS_RrMapRtOn_Req "Rear right map lamp On/Off request";
CM_ SG_ 1007 ATS_RrRoomOn_Req "Rear room lamp On/Off request";
CM_ SG_ 1007 ATS_LEDClrUpDn "Interior Light Color Up/Down Request";
CM_ SG_ 1007 ATS_RrMoodOn_Req "Rear mood lamp On/Off request";
CM_ SG_ 1007 ATS_LEDClr_Set "Interior Lamp LED Color Request";
CM_ SG_ 1007 ATS_LEDBgtns_Set "Interior Lamp LED Brightness Request";
CM_ SG_ 1007 ATS_FrMapLftOn_Req "Front left map lamp On/Off request";
CM_ SG_ 1007 ATS_FrMapRtOn_Req "Front right map lamp On/Off request";
CM_ SG_ 1007 ATS_FrRoomOn_Req "Front room lamp On/Off request";
CM_ BO_ 992 "[PE] Periodic and On Event";
CM_ SG_ 992 BCM_Crc2Val "BCM_CyclicRedundancyCheck2Value";
CM_ SG_ 992 BCM_AlvCnt2Val "BCM_AliveCounter2Value";
CM_ SG_ 992 BAlarm_BglrAlrmCurrentSta "BAlarm_BuglarAlarmCurrentStatus ##2G##BCM - BCMmsg17 - C_BAlarmState";
CM_ SG_ 992 BAlarm_BglrAlrmSta "BAlarm_BuglarAlarmStatus ##2G##BCM - BCMmsg17 - C_BAState";
CM_ SG_ 992 BAlarm_PncAlrmSta "BAlarm_PanicAlarmStatus ##2G##BCM - BCMmsg17 - C_PanicState";
CM_ SG_ 992 BAlarm_BrglrHrnRlySta "BAlarm_BurglarHornRelayStatus ##2G##BCM - BCMmsg19 - C_BurglarHornRly";
CM_ SG_ 992 BAlarm_ROABglrAlrmSta "IBU→ ROA, EngineState Info Tx";
CM_ SG_ 992 BCM_KeyInSta "BCM_KeyInStatus ##2G##BCM - BCMmsg17 - C_KeyInSW";
CM_ SG_ 992 BCM_AccInSta "BCM_AccInputStatus ##2G##BCM - BCMmsg17 - C_Acc";
CM_ SG_ 992 BCM_Ign1InSta "BCM_Ignition1InputStatus ##2G##BCM - BCMmsg17 - C_Ign1";
CM_ SG_ 992 BCM_Ign2InSta "BCM_Ignition1InputStatus ##2G##BCM - BCMmsg17 - C_Ign2";
CM_ SG_ 992 BCM_IgnSwSta "BCM_IgnitionSwitchStatus ##2G##BCM - BCMmsg17 - C_IGNSw";
CM_ BO_ 916 "[PE] Periodic and On Event";
CM_ SG_ 916 BCM_Crc19Val "BCM_CyclicRedundancyCheck19Value";
CM_ SG_ 916 BCM_AlvCnt19Val "BCM_AliveCounter19Value";
CM_ SG_ 916 USM_IBU_AutoDrUnLkReq "USM_AutoDoorUnLockRequest ##2G## -  - CF_Gway_ADrURValue";
CM_ SG_ 916 IBU_TwoTrnUnLkOptTyp "USM_TwoTurnUnlockOptionType ##2G## -  - C_TTUnlockOption";
CM_ SG_ 916 USM_IBU_TwoTrnUnLkCurrentSta "USM_TwoTurnUnlockCurrentStatus ##2G## -  - CF_Gway_TTUnlockRValue";
CM_ SG_ 916 DoorLock_ADrLOptInfo "vehicle option information for auto door lock/unlock USM";
CM_ SG_ 916 USM_IBU_RemoteWDWCurrentSta "Remote Window IBU USM on/off function signal";
CM_ SG_ 916 USM_1stRrStRmndSta "Rear Occupant Alert IBU(1st Only) USM  On/Off Request signal";
CM_ BO_ 2470763265 "[EC] On Event and On Change";
CM_ SG_ 2470763265 USM_AdasDSWSetReq "USM_AdasDSWSetRequest";
CM_ BO_ 2382594817 "[PE] Periodic and On Event";
CM_ SG_ 2382594817 DATC_Crc6Val "DATC_CyclicRedundancyCheck6Value";
CM_ SG_ 2382594817 DATC_AlvCnt6Val "DATC_AliveCounter6Value";
CM_ SG_ 2382594817 DATC_SyncDis "DATC_SyncDisplay";
CM_ SG_ 2382594817 DATC_OpSta "DATC_OperationStatus";
CM_ SG_ 2382594817 DATC_FrDfgSta "DATC_FrontDefogStatus";
CM_ SG_ 2382594817 DATC_SmrtVntDis "DATC_SmartVentilationDisplay";
CM_ SG_ 2382594817 DATC_AutoDfgBlnkDis "DATC_AutoDefogBlinkDisplay";
CM_ SG_ 2382594817 DATC_AutoDfgSysOffDis "DATC_AutoDefogSystemOffDisplay";
CM_ SG_ 2382594817 DATC_ArClnIND "DATC_AirCleanIndicator";
CM_ BO_ 907 "[PE] Periodic and On Event";
CM_ SG_ 907 FPM_Crc11Val "FPM_CyclicRedundancyCheck11Value";
CM_ SG_ 907 FPM_AlvCnt11Val "FPM_AliveCounter11Value";
CM_ SG_ 907 FPM2AVN_H2PV "FPM2AVN_H2PV";
CM_ SG_ 907 FPM2IAU_H2PV "FPM2IAU_H2PV";
CM_ BO_ 2015 "[TP] Transport Protocol";
CM_ BO_ 1510 "[TP] Transport Protocol";
CM_ BO_ 1954 "[TP] Transport Protocol";
CM_ BO_ 1973 "[TP] Transport Protocol";
CM_ BO_ 1955 "[TP] Transport Protocol";
CM_ BO_ 1507 "[TP] Transport Protocol";
CM_ BO_ 2563126785 "[EC] On Event and On Change";
CM_ SG_ 2563126785 AMP_HFVolumeStep "Command for HF(Hands Free) Call Volume Setting
-range : 0 ~ max
-max : value of AMP_MaxHFVolumeState(0x084)
-This Signal's Feedback is AMP_HFVolumeState(0x084)@AMP";
CM_ SG_ 2563126785 AMP_SiriVolumeStep "Command for Siri Mode Volume Setting";
CM_ BO_ 2323817729 "[EC] On Event and On Change";
CM_ SG_ 2323817729 C_RLBackSoftNValueSet_EC "2nd Left Seat Back Softness";
CM_ SG_ 2323817729 C_RRAirSptStrNValueSet_EC "2nd Right side seat Smart Air Support Strength";
CM_ SG_ 2323817729 C_RRAirSptTimeNValueSet_EC "2nd Right side seat Smart Air Support Time";
CM_ SG_ 2323817729 C_RRBackSoftNValueSet_EC "2nd Right side seat Back Softness";
CM_ SG_ 2323817729 C_RROneTchNvalueSet_EC "2nd Right side seat One Touch Mode";
CM_ SG_ 2323817729 C_RLOneTchNValueSet_EC "2nd Left side seat One Touch Mode";
CM_ SG_ 2323817729 C_RRAirSptModeNValueSet_EC "2nd Right side seat Moving control : Smart Air Support Mode";
CM_ BO_ 2449770241 "[PE] Periodic and On Event";
CM_ SG_ 2449770241 C_AstRclBwdSw_HU "Assistant seat Moving control :Recline Backward";
CM_ SG_ 2449770241 C_AstHeightUpSw_HU "Assistant seat Moving control : Height Up";
CM_ SG_ 2449770241 C_AstTiltDnSw_HU "Assistant seat Moving control : Tilt Down";
CM_ SG_ 2449770241 C_AstTiltUpSw_HU "Assistant seat Moving Switch : Tilt Up";
CM_ SG_ 2449770241 C_AstLumbarDefSw_HU "Assistant seat moving switch: Deflate";
CM_ SG_ 2449770241 C_AstLumbarLowSw_HU "Assistant seat moving switch:Lumbar Low";
CM_ SG_ 2449770241 C_AstRclFwdSw_HU "Assistant seat Moving Switch : Recline Forward";
CM_ SG_ 2449770241 C_AstLumbarMidSw_HU "Assistant seat Moving control : Lumbar Mid";
CM_ SG_ 2449770241 C_AstLumbarUpSw_HU "Assistant seat Moving control : Lumbar Up";
CM_ SG_ 2449770241 C_RRSlideFwdSw_HU "2nd Right side seat Moving control :Power Slide Forward";
CM_ SG_ 2449770241 C_RRSlideBwdSw_HU "2nd Right side seat Moving control :Power Slide Backward";
CM_ SG_ 2449770241 C_RLSlideFwdSw_HU "2nd Left side seat Moving control :Power Slide Forward";
CM_ SG_ 2449770241 C_RLSlideBwdSw_HU "2nd Left side seat Moving control :Power Slide Backward";
CM_ SG_ 2449770241 C_AstSlideBwdSw_HU "Assistant seat moving switch : Slide Backward";
CM_ SG_ 2449770241 C_AstRlxNValueSet "Assistant seat Moving control : Relaxtion mode";
CM_ SG_ 2449770241 C_AstSlideFwdSw_HU "Assistant seat Moving switch : Slide Forward";
CM_ SG_ 2449770241 C_AstHeightDnSw_HU "Assistant seat Moving control : Height Down";
CM_ BO_ 2479157505 "[PE] Periodic and On Event";
CM_ SG_ 2479157505 HU_TeleVehicleStatusReq "Request vehicle status information.";
CM_ SG_ 2479157505 HU_Background "HU Backgound image info";
CM_ SG_ 2479157505 ccIC_HUD_PbackSta "Status signal for HUD interoperation with IMS";
CM_ SG_ 2479157505 HU_BackgroundFadeInOut "HU Background Fade in/out info - (HEX * Factor) %";
CM_ BO_ 2462366209 "[EC] On Event and On Change";
CM_ SG_ 2462366209 PROSHORT_V2_3_Offset "Information for Offset of position of the first profile spot from currnet position
-This Offset should be calculated using below Factors(according to Profile Type)
-Profile Type 1(Curvature): 1m
-Profile Type 4(Slope): 1m(PROSHORT_Accuracy=0x0), 3m(PROSHORT_Accuracy=0x2)
-Profile Type 16(Safety Driving Section): 1m(Section0,1,2,3,5)
-Refer to Specification(ES96523-31) for details";
CM_ SG_ 2462366209 PROSHORT_V2_3_PathIndex "Information for Index of the path where this profile is located";
CM_ SG_ 2462366209 PROSHORT_V2_3_Distance "Information for Distance from first profile spot to the second one
-This distance should be calculated using below Factors(according to Profile Type)
-Profile Type 1(Curvature): 2
-Profile Type 4(Slope): 2(PROSHORT_Accuracy=0x0), 20(PROSHORT_Accuracy=0x2)
-Profile Type 16(Safety Driving Section): 20(Section0,1), 2(Section2,3), 5(Section5)";
CM_ SG_ 2462366209 PROSHORT_V2_3_Value0 "Information for Profile Short value at Offset";
CM_ SG_ 2462366209 PROSHORT_V2_3_Value1 "Information for Profile Short value at Offset+Distance1";
CM_ SG_ 2462366209 PROSHORT_V2_3_ProfileType "Information for Profile Short Type: Slope(Linear) is used for Slope
-In case of Section Speed, transmitt Average Value of Speed Limit of Links in Section.
-Link without Speed Limit is excluded for Average Speed Calculation
-Unlimited Lane in Europe reflects 140kph for Average Speed Calculation";
CM_ SG_ 2462366209 PROSHORT_V2_3_CyclicCounter "Information for Cyclic counter of this message type and profile type: Reconstructor can use this value to detect missing messages.
-According to Profile Type, transmitt different Cyclic Counter Values
-In case of Slope, transmitt Cyclic Counter Values according to the Slope Transmitting Specification
 (Refer to 5.4 Slope Information Transmitting Scenario in Specification: It is about Information for Average Slope(Maximum 3) Transmitting by Event in forward unit distance(2km/20km) containing Current Location)
-In case of 'PROSHORT_CyclicCounter', transmitt particularly according to the 'PROSHORT_ProfileType'
 Ex) ProfileType(CyclicCounter): 0x1(0)  0x1(1)  0x10(0)  0x1(2)  0x10(1) ...";
CM_ SG_ 2462366209 PROSHORT_V2_3_Accuracy "Information for Accuracy of profile value is implementation specific.";
CM_ BO_ 2458168065 "[EC] On Event and On Change";
CM_ SG_ 2458168065 CF_AVN_CluWelcomeSnd "Request to set CLU welcome soun";
CM_ SG_ 2458168065 CF_AVN_CluTransmissionDisp "Request to set CLU transmission display";
CM_ SG_ 2458168065 CF_AVN_CluWiperLight "Request to set CLU wiper & light mode";
CM_ SG_ 2458168065 CF_AVN_CluRoadInfoGuide "Request to set CLU road info guidance";
CM_ SG_ 2458168065 CF_AVN_CluUserSettingPeriod "Request to set CLU sservice period set by user";
CM_ SG_ 2458168065 CF_AVN_CluAutoInitFuelEconomy "Request to set CLU auto initailizing fuel economy";
CM_ SG_ 2458168065 CF_AVN_CluSubspeedOdometerDisp "Request to set CLU Subscale Odometer";
CM_ SG_ 2458168065 CF_AVN_CluFuelEconUnit_mi "Cluster setting status for cluster Fuel Economy Unit (mile)";
CM_ SG_ 2458168065 CF_AVN_CluFuelEconUnit_km "Cluster setting status for cluster Fuel Economy unit (km)";
CM_ SG_ 2458168065 CF_AVN_CluUserSettingDistance "Request to set CLU service distance set by user";
CM_ SG_ 2458168065 CF_AVN_CluRheostatLvl "Request to set CLU rheostat level";
CM_ SG_ 2458168065 CF_AVN_CluVoiceVolume "Request to set CLU Volume level";
CM_ SG_ 2458168065 CF_AVN_EVReset "Request to reset EV Service (0x1 : EV USM Reset)";
CM_ SG_ 2458168065 CF_AVN_UnitReset "Request to reset Unit setting";
CM_ SG_ 2458168065 CF_AVN_IcyRoadWarn "Request to set CLU icy road warning";
CM_ SG_ 2458168065 CF_AVN_CluServiceReminderReset "Request to reset CLU service reminder";
CM_ SG_ 2458168065 CF_AVN_CluUSMReset "Request to reset all USM service";
CM_ SG_ 2458168065 CF_AVN_CluServiceReminderSet "Request to set CLU service notification";
CM_ BO_ 2323817217 "[EC] On Event and On Change";
CM_ SG_ 2323817217 CF_AVN_HtBlcRLNValueSet "Request for 2nd Left seat heater balance";
CM_ SG_ 2323817217 CF_AVN_HtBlcRRNValueSet "Request for 2nd Right seat heater balance";
CM_ SG_ 2323817217 CF_AVN_RemoteWDWNValueSet "Remote Window On/Off Set signal of USM for Fob Key";
CM_ SG_ 2323817217 CF_AVN_ADrLNValueSet2 "USM Request for Auto Door Lock";
CM_ SG_ 2323817217 CF_AVN_PCA_RrEquipNvalueSet "Headunit Setting signal for Rear Safety of USM";
CM_ BO_ 1981 "[TP] Transport Protocol";
CM_ BO_ 902 "[PE] Periodic and On Event";
CM_ SG_ 902 PSM_DrvStEsyAcsUSMSta "USM_MovingValue";
CM_ SG_ 902 SmrtIMS_StatureRspVal "HCIMS_HeightRsponseValue";
CM_ SG_ 902 SmrtIMS_SeatedHghtRspVal "HCIMS_SitHeightRsponseValue";
CM_ SG_ 902 SmrtIMS_WghtRspVal "HCIMS_WeightRsponseValue";
CM_ SG_ 902 SmartIMS_DisReq "PSM_MoveStatusDisplay";
CM_ SG_ 902 SmrtIMS_ExitSta "Smart IMS exit condition";
CM_ SG_ 902 PSM_IMSOptTyp "Option flag for IMS system";
CM_ BO_ 903 "[PE] Periodic and On Event";
CM_ SG_ 903 PSM_DrvStSldFwdDis "PSM_DriverSlideForwardDisplay";
CM_ SG_ 903 PSM_DrvStTiltDnDis "PSM_DriverTiltDownSwitchDisplay";
CM_ SG_ 903 PSM_DrvStHghtUpDis "PSM_DriverHeightUpSwitchDisplay";
CM_ SG_ 903 PSM_DrvStHghtDnDis "PSM_DriverHeightDownSwitchDisplay";
CM_ SG_ 903 PSM_DrvStCushExtBckwdDis "PSM_DriverCushionExtendedBackwardSwitchDisplay";
CM_ SG_ 903 PSM_DrvStCushExtFwdDis "PSM_DriverCushionExtendedForwardSwitchDisplay";
CM_ SG_ 903 PSM_DrvStSldBckwdDis "PSM_DriverSlideBackwardSwitchDisplay";
CM_ SG_ 903 PSM_DrvStHdRstUpDis "PSM_DriverHeadRestUpSwitchDisplay";
CM_ SG_ 903 PSM_DrvStHdRstDnDis "PSM_DriverHeadRestDownSwitchDisplay";
CM_ SG_ 903 PSM_DrvStHdRstFwdDis "PSM_DriverHeadRestForwardSwitchDisplay";
CM_ SG_ 903 PSM_DrvStHdRstBckwdDis "PSM_DriverHeadRestBackwardSwitchDisplay";
CM_ SG_ 903 PSM_DrvStLmbrDefDis "PSM_DriverLumbarDeFlateSwitchDisplay";
CM_ SG_ 903 PSM_DrvStLmbrLoDis "PSM_DriverLumbarLowSwitchDisplay";
CM_ SG_ 903 PSM_DrvStLmbrMdlDis "PSM_DriverLumbarMiddleSwitchDisplay";
CM_ SG_ 903 PSM_DrvStLmbrUpDis "PSM_DriverLumbarUpSwitchDisplay";
CM_ SG_ 903 PSM_DrvStReclneFwdDis "PSM_DriverSeatReclineForwardSwitchDisplay";
CM_ SG_ 903 PSM_LmbrSigSrcTyp "Lumbar Switch Signal Source(TX)";
CM_ SG_ 903 PSM_DrvStReclneBckwdDis "PSM_DriverSeatReclineBackwardSwitchDisplay";
CM_ SG_ 903 PSM_DrvStTiltUpDis "PSM_DriverTiltUpSwitchDisplay";
CM_ BO_ 904 "[PE] Periodic and On Event";
CM_ SG_ 904 PSM_EsyAcsGetOffSta "Easy Access Get Off Information";
CM_ SG_ 904 PSM_EsyAcsStpSta "Easy Access Stop Information";
CM_ SG_ 904 PSM_SWVerMajor1 "First Word(ASCII) in PSM S/W Ver";
CM_ SG_ 904 PSM_SWVerMinor1 "Second Word(ASCII) in PSM S/W Ver";
CM_ SG_ 904 PSM_SWVerMinor2 "Third Word(ASCII) in PSM S/W Ver";
CM_ SG_ 904 PSM_EsyAcsGetOnSta "Easy Access Get On Information";
CM_ BO_ 1515 "[TP] Transport Protocol";
CM_ BO_ 1003 "[PE] Periodic and On Event";
CM_ SG_ 1003 PSM_BzrOnRLReq "PSM_BuzzerOnRLRequest";
CM_ SG_ 1003 RLPSM_RLStEsyAcsUSMSta "RLPSM_USM_MovingValue";
CM_ SG_ 1003 RLPSM_LimSetSta "RLPSM limit setting state";
CM_ BO_ 2223056129 "[P] Periodic";
CM_ SG_ 2223056129 SAS_Crc1Val "SAS_CyclicRedundancyCheck1Value";
CM_ SG_ 2223056129 SAS_AlvCnt1Val "SAS_AliveCounter1Value";
CM_ SG_ 2223056129 SAS_AnglVal "SAS_AngleValue";
CM_ SG_ 2223056129 SAS_SpdVal "SAS_SpeedValue";
CM_ SG_ 2223056129 SAS_IntSta "SAS_InternalStatus";
CM_ BO_ 2223056130 "[P] Periodic";
CM_ BO_ 905 "[PE] Periodic and On Event";
CM_ SG_ 905 SBCM_RR_Crc1Val "SBCM_RR_CyclicRedundancyCheck1Value";
CM_ SG_ 905 RR_CrashUnlockCmd "Rear Right Crash Unlock Command";
CM_ SG_ 905 SBCM_RR_AlvCnt1Val "SBCM_RR_AliveCounter1Value";
CM_ SG_ 905 Warn_RrRtDrSwSta_SBCM "Warn_RearRightDoorSwitchStatus ##2G## -  - C_RRDrSw,CF_Gway_RRDrSw,Warn_RrRtDrSwSta";
CM_ SG_ 905 DoorLock_RrRtDrUnLkSta_SBCM "DoorLock_RearRightDoorUnLockStatus ##2G## -  - C_RRUnlockState,DoorLock_RrRtDrUnLkSta";
CM_ SG_ 905 RR_SEAActivated "Rear Right SEA Activated";
CM_ SG_ 905 RR_SEAWarn "Rear Righr SEA Warning";
BA_DEF_ BO_ "DiagState" ENUM "No","Yes" ;
BA_DEF_ BO_ "DiagResponse" ENUM "No","Yes" ;
BA_DEF_ BO_ "DiagRequest" ENUM "No","Yes" ;
BA_DEF_ BO_ "TpMessage" ENUM "No","Yes" ;
BA_DEF_ BO_ "UsrMsgIDSforwardDeviation" INT 0 100 ;
BA_DEF_ BO_ "UsrMsgIDSbackwardDeviation" INT 50 1000 ;
BA_DEF_ BO_ "GenMsgCycleTime" INT 0 2000 ;
BA_DEF_ BO_ "GenMsgStartDelayTime" INT 0 2000 ;
BA_DEF_ BO_ "GenMsgSendType" ENUM "Cyclic","NoMsgSendType" ;
BA_DEF_ BO_ "GenMsgCycleTimeFast" INT 0 500 ;
BA_DEF_ BO_ "GenMsgDelayTime" INT 0 20 ;
BA_DEF_ BO_ "GenMsgILSupport" ENUM "No","Yes" ;
BA_DEF_ BO_ "GenMsgNrOfRepetition" INT 0 3 ;
BA_DEF_ BO_ "NmMessage" ENUM "No","Yes" ;
BA_DEF_ BO_ "NWM-Botschaft" ENUM "No","Yes" ;
BA_DEF_ BO_ "TpTxIndex" INT 0 255 ;
BA_DEF_ BO_ "VFrameFormat" ENUM "StandardCAN","ExtendedCAN","reserved","reserved","reserved","reserved","reserved","reserved","reserved","reserved","reserved","reserved","reserved","reserved","StandardCAN_FD","ExtendedCAN_FD" ;
BA_DEF_ SG_ "UserSigValidity" ENUM "B+","ACC","IG","IG1","IG2","IG3","IG1 or IG2","IG1 or IG3","Undef" ;
BA_DEF_ SG_ "TimeoutValue" STRING ;
BA_DEF_ SG_ "UsrSigPurpose" ENUM "Undef","FN","DIAG","DIAG(Req)","DIAG(Res)","DIAG(Phy)","DEV","CCP(Req)","CCP(Res)","NM","TP" ;
BA_DEF_ SG_ "GenSigStartValue" INT 0 1215752192 ;
BA_DEF_ SG_ "NetworkRequest" ENUM "Yes","No" ;
BA_DEF_ SG_ "NetworkRequestHoldingTime" INT 0 65535 ;
BA_DEF_ SG_ "Description" STRING ;
BA_DEF_ SG_ "Version" STRING ;
BA_DEF_ SG_ "GenSigEnvVarType" ENUM "Int","Float","Undef" ;
BA_DEF_ SG_ "GenSigSendType" ENUM "Cyclic","OnWrite","OnWriteWithRepetition","OnChange","OnChangeWithRepetition","IfActive","IfActiveWithRepetition","NoSigSendType","OnChangeAndIfActive","OnChangeAndIfActiveWithRepetition" ;
BA_DEF_ SG_ "GwSigLatencyTime" INT 0 65536 ;
BA_DEF_ SG_ "GwSigMissingSourceType" ENUM "Undef","OldValue","DefaultValue","InitialValue" ;
BA_DEF_ SG_ "NWM-WakeupAllowed" ENUM "<n.a.>" ;
BA_DEF_ SG_ "RoutingFactor" INT 1 1215752192 ;
BA_DEF_REL_ BU_SG_REL_ "GenSigTimeoutTime" INT 0 7000 ;
BA_DEF_DEF_ "DiagState" "No" ;
BA_DEF_DEF_ "DiagResponse" "No" ;
BA_DEF_DEF_ "DiagRequest" "No" ;
BA_DEF_DEF_ "TpMessage" "No" ;
BA_DEF_DEF_ "UsrMsgIDSforwardDeviation" 10 ;
BA_DEF_DEF_ "UsrMsgIDSbackwardDeviation" 100 ;
BA_DEF_DEF_ "GenMsgCycleTime" 200 ;
BA_DEF_DEF_ "GenMsgStartDelayTime" 0 ;
BA_DEF_DEF_ "GenMsgSendType" "NoMsgSendType" ;
BA_DEF_DEF_ "GenMsgCycleTimeFast" 40 ;
BA_DEF_DEF_ "GenMsgDelayTime" 20 ;
BA_DEF_DEF_ "GenMsgILSupport" "Yes" ;
BA_DEF_DEF_ "GenMsgNrOfRepetition" 3 ;
BA_DEF_DEF_ "NmMessage" "No" ;
BA_DEF_DEF_ "NWM-Botschaft" "No" ;
BA_DEF_DEF_ "TpTxIndex" 0 ;
BA_DEF_DEF_ "VFrameFormat" "StandardCAN" ;
BA_DEF_DEF_ "UserSigValidity" "IG" ;
BA_DEF_DEF_ "TimeoutValue" "" ;
BA_DEF_DEF_ "UsrSigPurpose" "FN" ;
BA_DEF_DEF_ "GenSigStartValue" 0 ;
BA_DEF_DEF_ "NetworkRequest" "No" ;
BA_DEF_DEF_ "NetworkRequestHoldingTime" 0 ;
BA_DEF_DEF_ "Description" "" ;
BA_DEF_DEF_ "Version" "" ;
BA_DEF_DEF_ "GenSigEnvVarType" "Undef" ;
BA_DEF_DEF_ "GenSigSendType" "NoSigSendType" ;
BA_DEF_DEF_ "GwSigLatencyTime" 40 ;
BA_DEF_DEF_ "GwSigMissingSourceType" "Undef" ;
BA_DEF_DEF_ "NWM-WakeupAllowed" "<n.a.>" ;
BA_DEF_DEF_ "RoutingFactor" 1 ;
BA_DEF_DEF_REL_ "GenSigTimeoutTime" 500 ;
BA_ "GenMsgCycleTime" BO_ 1518 0;
BA_ "GenMsgCycleTimeFast" BO_ 1518 0;
BA_ "GenMsgNrOfRepetition" BO_ 1518 0;
BA_ "DiagResponse" BO_ 1518 1;
BA_ "GenMsgILSupport" BO_ 1518 0;
BA_ "TpMessage" BO_ 1518 1;
BA_ "TpTxIndex" BO_ 1518 108;
BA_ "Description" SG_ 1518 APSS_GST_Byte0 "TP Index : 108";
BA_ "UsrSigPurpose" SG_ 1518 APSS_GST_Byte0 4;
BA_ "UserSigValidity" SG_ 1518 APSS_GST_Byte0 0;
BA_REL_ "GenSigTimeoutTime" BU_SG_REL_ CGW_CCU SG_ 1518 APSS_GST_Byte0 0;
BA_ "NetworkRequest" SG_ 1518 APSS_GST_Byte0 0;
BA_ "NetworkRequestHoldingTime" SG_ 1518 APSS_GST_Byte0 5000;
BA_ "Version" SG_ 1518 APSS_GST_Byte0 "21.02.04";
BA_ "Description" SG_ 1518 APSS_GST_Byte2 "TP Index : 108";
BA_ "UsrSigPurpose" SG_ 1518 APSS_GST_Byte2 4;
BA_ "UserSigValidity" SG_ 1518 APSS_GST_Byte2 0;
BA_REL_ "GenSigTimeoutTime" BU_SG_REL_ CGW_CCU SG_ 1518 APSS_GST_Byte2 0;
BA_ "NetworkRequest" SG_ 1518 APSS_GST_Byte2 0;
BA_ "NetworkRequestHoldingTime" SG_ 1518 APSS_GST_Byte2 5000;
BA_ "Version" SG_ 1518 APSS_GST_Byte2 "21.02.04";
BA_ "Description" SG_ 1518 APSS_GST_Byte3 "TP Index : 108";
BA_ "UsrSigPurpose" SG_ 1518 APSS_GST_Byte3 4;
BA_ "UserSigValidity" SG_ 1518 APSS_GST_Byte3 0;
BA_REL_ "GenSigTimeoutTime" BU_SG_REL_ CGW_CCU SG_ 1518 APSS_GST_Byte3 0;
BA_ "NetworkRequest" SG_ 1518 APSS_GST_Byte3 0;
BA_ "NetworkRequestHoldingTime" SG_ 1518 APSS_GST_Byte3 5000;
BA_ "Version" SG_ 1518 APSS_GST_Byte3 "21.02.04";
BA_ "Description" SG_ 1518 APSS_GST_Byte4 "TP Index : 108";
BA_ "UsrSigPurpose" SG_ 1518 APSS_GST_Byte4 4;
BA_ "UserSigValidity" SG_ 1518 APSS_GST_Byte4 0;
BA_REL_ "GenSigTimeoutTime" BU_SG_REL_ CGW_CCU SG_ 1518 APSS_GST_Byte4 0;
BA_ "NetworkRequest" SG_ 1518 APSS_GST_Byte4 0;
BA_ "NetworkRequestHoldingTime" SG_ 1518 APSS_GST_Byte4 5000;
BA_ "Version" SG_ 1518 APSS_GST_Byte4 "21.02.04";
BA_ "Description" SG_ 1518 APSS_GST_Byte5 "TP Index : 108";
BA_ "UsrSigPurpose" SG_ 1518 APSS_GST_Byte5 4;
BA_ "UserSigValidity" SG_ 1518 APSS_GST_Byte5 0;
BA_REL_ "GenSigTimeoutTime" BU_SG_REL_ CGW_CCU SG_ 1518 APSS_GST_Byte5 0;
BA_ "NetworkRequest" SG_ 1518 APSS_GST_Byte5 0;
BA_ "NetworkRequestHoldingTime" SG_ 1518 APSS_GST_Byte5 5000;
BA_ "Version" SG_ 1518 APSS_GST_Byte5 "21.02.04";
BA_ "Description" SG_ 1518 APSS_GST_Byte6 "TP Index : 108";
BA_ "UsrSigPurpose" SG_ 1518 APSS_GST_Byte6 4;
BA_ "UserSigValidity" SG_ 1518 APSS_GST_Byte6 0;
BA_REL_ "GenSigTimeoutTime" BU_SG_REL_ CGW_CCU SG_ 1518 APSS_GST_Byte6 0;
BA_ "NetworkRequest" SG_ 1518 APSS_GST_Byte6 0;
BA_ "NetworkRequestHoldingTime" SG_ 1518 APSS_GST_Byte6 5000;
BA_ "Version" SG_ 1518 APSS_GST_Byte6 "21.02.04";
BA_ "Description" SG_ 1518 APSS_GST_Byte7 "TP Index : 108";
BA_ "UsrSigPurpose" SG_ 1518 APSS_GST_Byte7 4;
BA_ "UserSigValidity" SG_ 1518 APSS_GST_Byte7 0;
BA_REL_ "GenSigTimeoutTime" BU_SG_REL_ CGW_CCU SG_ 1518 APSS_GST_Byte7 0;
BA_ "NetworkRequest" SG_ 1518 APSS_GST_Byte7 0;
BA_ "NetworkRequestHoldingTime" SG_ 1518 APSS_GST_Byte7 5000;
BA_ "Version" SG_ 1518 APSS_GST_Byte7 "21.02.04";
BA_ "Description" SG_ 1518 APSS_GST_Byte1 "TP Index : 108";
BA_ "UsrSigPurpose" SG_ 1518 APSS_GST_Byte1 4;
BA_ "UserSigValidity" SG_ 1518 APSS_GST_Byte1 0;
BA_REL_ "GenSigTimeoutTime" BU_SG_REL_ CGW_CCU SG_ 1518 APSS_GST_Byte1 0;
BA_ "NetworkRequest" SG_ 1518 APSS_GST_Byte1 0;
BA_ "NetworkRequestHoldingTime" SG_ 1518 APSS_GST_Byte1 5000;
BA_ "Version" SG_ 1518 APSS_GST_Byte1 "21.02.04";
BA_ "GenMsgCycleTime" BO_ 911 0;
BA_ "Description" SG_ 911 ATS_RearLock_Set "RRC and RSE Lock Touch Button";
BA_ "GenSigSendType" SG_ 911 ATS_RearLock_Set 4;
BA_ "GenSigStartValue" SG_ 911 ATS_RearLock_Set 3;
BA_ "UserSigValidity" SG_ 911 ATS_RearLock_Set 3;
BA_REL_ "GenSigTimeoutTime" BU_SG_REL_ CGW_CCU SG_ 911 ATS_RearLock_Set 0;
BA_ "NetworkRequest" SG_ 911 ATS_RearLock_Set 0;
BA_ "NetworkRequestHoldingTime" SG_ 911 ATS_RearLock_Set 5000;
BA_ "Version" SG_ 911 ATS_RearLock_Set "20.07.08";
BA_ "Description" SG_ 911 ATS_RrCurtainBtn "Rear Curtain Touch Button";
BA_ "GenSigSendType" SG_ 911 ATS_RrCurtainBtn 4;
BA_ "UserSigValidity" SG_ 911 ATS_RrCurtainBtn 3;
BA_REL_ "GenSigTimeoutTime" BU_SG_REL_ CGW_CCU SG_ 911 ATS_RrCurtainBtn 0;
BA_ "NetworkRequest" SG_ 911 ATS_RrCurtainBtn 0;
BA_ "NetworkRequestHoldingTime" SG_ 911 ATS_RrCurtainBtn 5000;
BA_ "Version" SG_ 911 ATS_RrCurtainBtn "20.07.05";
BA_ "Description" SG_ 911 ATS_RrDrCurtainBtn "Rear Door and Curtain Touch Button";
BA_ "GenSigSendType" SG_ 911 ATS_RrDrCurtainBtn 4;
BA_ "UserSigValidity" SG_ 911 ATS_RrDrCurtainBtn 3;
BA_REL_ "GenSigTimeoutTime" BU_SG_REL_ RDC SG_ 911 ATS_RrDrCurtainBtn 0;
BA_ "NetworkRequest" SG_ 911 ATS_RrDrCurtainBtn 0;
BA_ "NetworkRequestHoldingTime" SG_ 911 ATS_RrDrCurtainBtn 5000;
BA_ "Version" SG_ 911 ATS_RrDrCurtainBtn "20.07.05";
BA_ "Description" SG_ 911 ATS_RLDrCurtainBtn "Rear Door and Curtain Touch Button";
BA_ "GenSigSendType" SG_ 911 ATS_RLDrCurtainBtn 4;
BA_ "UserSigValidity" SG_ 911 ATS_RLDrCurtainBtn 3;
BA_REL_ "GenSigTimeoutTime" BU_SG_REL_ RDC SG_ 911 ATS_RLDrCurtainBtn 0;
BA_ "NetworkRequest" SG_ 911 ATS_RLDrCurtainBtn 0;
BA_ "NetworkRequestHoldingTime" SG_ 911 ATS_RLDrCurtainBtn 5000;
BA_ "Version" SG_ 911 ATS_RLDrCurtainBtn "20.07.05";
BA_ "Description" SG_ 911 ATS_RRSunBlind "SunBlind Touch Botton";
BA_ "GenSigSendType" SG_ 911 ATS_RRSunBlind 4;
BA_ "UserSigValidity" SG_ 911 ATS_RRSunBlind 3;
BA_REL_ "GenSigTimeoutTime" BU_SG_REL_ CGW_CCU SG_ 911 ATS_RRSunBlind 0;
BA_ "NetworkRequest" SG_ 911 ATS_RRSunBlind 0;
BA_ "NetworkRequestHoldingTime" SG_ 911 ATS_RRSunBlind 5000;
BA_ "Version" SG_ 911 ATS_RRSunBlind "20.07.05";
BA_ "Description" SG_ 911 ATS_FCS_LockTrayIniPwSet "Locking Tray 비밀번호 설정 진입 버튼";
BA_ "GenSigSendType" SG_ 911 ATS_FCS_LockTrayIniPwSet 4;
BA_ "UserSigValidity" SG_ 911 ATS_FCS_LockTrayIniPwSet 3;
BA_ "NetworkRequest" SG_ 911 ATS_FCS_LockTrayIniPwSet 0;
BA_ "NetworkRequestHoldingTime" SG_ 911 ATS_FCS_LockTrayIniPwSet 5000;
BA_ "Version" SG_ 911 ATS_FCS_LockTrayIniPwSet "21.01.02";
BA_ "Description" SG_ 911 ATS_FCS_LockTrayKeyPadNo "Locking Tray 비밀번호 설정 key Pad 버튼";
BA_ "GenSigSendType" SG_ 911 ATS_FCS_LockTrayKeyPadNo 4;
BA_ "UserSigValidity" SG_ 911 ATS_FCS_LockTrayKeyPadNo 3;
BA_ "NetworkRequest" SG_ 911 ATS_FCS_LockTrayKeyPadNo 0;
BA_ "NetworkRequestHoldingTime" SG_ 911 ATS_FCS_LockTrayKeyPadNo 5000;
BA_ "Version" SG_ 911 ATS_FCS_LockTrayKeyPadNo "21.01.02";
BA_ "Description" SG_ 911 ATS_FCS_LockTrayNoDel "Locking Tray 비밀번호 설정 숫자 삭제 버튼";
BA_ "GenSigSendType" SG_ 911 ATS_FCS_LockTrayNoDel 4;
BA_ "UserSigValidity" SG_ 911 ATS_FCS_LockTrayNoDel 3;
BA_ "NetworkRequest" SG_ 911 ATS_FCS_LockTrayNoDel 0;
BA_ "NetworkRequestHoldingTime" SG_ 911 ATS_FCS_LockTrayNoDel 5000;
BA_ "Version" SG_ 911 ATS_FCS_LockTrayNoDel "21.01.02";
BA_ "Description" SG_ 911 ATS_FCS_LockTrayNoClr "Locking Tray 비밀번호 설정 숫자 Clear 버튼";
BA_ "GenSigSendType" SG_ 911 ATS_FCS_LockTrayNoClr 4;
BA_ "UserSigValidity" SG_ 911 ATS_FCS_LockTrayNoClr 3;
BA_ "NetworkRequest" SG_ 911 ATS_FCS_LockTrayNoClr 0;
BA_ "NetworkRequestHoldingTime" SG_ 911 ATS_FCS_LockTrayNoClr 5000;
BA_ "Version" SG_ 911 ATS_FCS_LockTrayNoClr "21.01.02";
BA_ "Description" SG_ 911 ATS_FCS_LockTrayPwChange "Locking Tray 비밀번호 변경 진입 버튼";
BA_ "GenSigSendType" SG_ 911 ATS_FCS_LockTrayPwChange 4;
BA_ "UserSigValidity" SG_ 911 ATS_FCS_LockTrayPwChange 3;
BA_ "NetworkRequest" SG_ 911 ATS_FCS_LockTrayPwChange 0;
BA_ "NetworkRequestHoldingTime" SG_ 911 ATS_FCS_LockTrayPwChange 5000;
BA_ "Version" SG_ 911 ATS_FCS_LockTrayPwChange "21.01.02";
BA_ "Description" SG_ 911 ATS_FCS_LockTrayPwReset "Locking Tray 비밀번호 초기화 진입 버튼 (비밀번호 없는 상태로 원복)";
BA_ "GenSigSendType" SG_ 911 ATS_FCS_LockTrayPwReset 4;
BA_ "UserSigValidity" SG_ 911 ATS_FCS_LockTrayPwReset 3;
BA_ "NetworkRequest" SG_ 911 ATS_FCS_LockTrayPwReset 0;
BA_ "NetworkRequestHoldingTime" SG_ 911 ATS_FCS_LockTrayPwReset 5000;
BA_ "Version" SG_ 911 ATS_FCS_LockTrayPwReset "21.01.02";
BA_ "Description" SG_ 911 ATS_FCS_LockTrayCancel "Locking Tray 비밀번호 입력 화면 Cancel 버튼";
BA_ "GenSigSendType" SG_ 911 ATS_FCS_LockTrayCancel 4;
BA_ "UserSigValidity" SG_ 911 ATS_FCS_LockTrayCancel 3;
BA_ "NetworkRequest" SG_ 911 ATS_FCS_LockTrayCancel 0;
BA_ "NetworkRequestHoldingTime" SG_ 911 ATS_FCS_LockTrayCancel 5000;
BA_ "Version" SG_ 911 ATS_FCS_LockTrayCancel "21.01.02";
BA_ "GenMsgCycleTime" BO_ 1007 0;
BA_ "Description" SG_ 1007 ATS_LEDBgtnsUpDn "This signal is  interior lamp brightness up/down control signal";
BA_ "GenSigSendType" SG_ 1007 ATS_LEDBgtnsUpDn 4;
BA_ "UserSigValidity" SG_ 1007 ATS_LEDBgtnsUpDn 3;
BA_REL_ "GenSigTimeoutTime" BU_SG_REL_ CGW_CCU SG_ 1007 ATS_LEDBgtnsUpDn 0;
BA_ "Version" SG_ 1007 ATS_LEDBgtnsUpDn "20.04.05";
BA_ "Description" SG_ 1007 ATS_FrMoodOn_Req "Front mood lamp On/Off request";
BA_ "GenSigSendType" SG_ 1007 ATS_FrMoodOn_Req 4;
BA_ "UserSigValidity" SG_ 1007 ATS_FrMoodOn_Req 3;
BA_REL_ "GenSigTimeoutTime" BU_SG_REL_ CGW_CCU SG_ 1007 ATS_FrMoodOn_Req 0;
BA_ "NetworkRequest" SG_ 1007 ATS_FrMoodOn_Req 0;
BA_ "NetworkRequestHoldingTime" SG_ 1007 ATS_FrMoodOn_Req 5000;
BA_ "Version" SG_ 1007 ATS_FrMoodOn_Req "20.06.09";
BA_ "Description" SG_ 1007 ATS_DoorOn_Req "Front Door switch On/Off request";
BA_ "GenSigSendType" SG_ 1007 ATS_DoorOn_Req 4;
BA_ "UserSigValidity" SG_ 1007 ATS_DoorOn_Req 3;
BA_REL_ "GenSigTimeoutTime" BU_SG_REL_ CGW_CCU SG_ 1007 ATS_DoorOn_Req 0;
BA_ "NetworkRequest" SG_ 1007 ATS_DoorOn_Req 0;
BA_ "NetworkRequestHoldingTime" SG_ 1007 ATS_DoorOn_Req 5000;
BA_ "Version" SG_ 1007 ATS_DoorOn_Req "20.06.09";
BA_ "Description" SG_ 1007 ATS_RrMapLftOn_Req "Rear left map lamp On/Off request";
BA_ "GenSigSendType" SG_ 1007 ATS_RrMapLftOn_Req 4;
BA_ "UserSigValidity" SG_ 1007 ATS_RrMapLftOn_Req 3;
BA_REL_ "GenSigTimeoutTime" BU_SG_REL_ CGW_CCU SG_ 1007 ATS_RrMapLftOn_Req 0;
BA_ "NetworkRequest" SG_ 1007 ATS_RrMapLftOn_Req 0;
BA_ "NetworkRequestHoldingTime" SG_ 1007 ATS_RrMapLftOn_Req 5000;
BA_ "Version" SG_ 1007 ATS_RrMapLftOn_Req "20.06.09";
BA_ "Description" SG_ 1007 ATS_RrMapRtOn_Req "Rear right map lamp On/Off request";
BA_ "GenSigSendType" SG_ 1007 ATS_RrMapRtOn_Req 4;
BA_ "UserSigValidity" SG_ 1007 ATS_RrMapRtOn_Req 3;
BA_REL_ "GenSigTimeoutTime" BU_SG_REL_ CGW_CCU SG_ 1007 ATS_RrMapRtOn_Req 0;
BA_ "NetworkRequest" SG_ 1007 ATS_RrMapRtOn_Req 0;
BA_ "NetworkRequestHoldingTime" SG_ 1007 ATS_RrMapRtOn_Req 5000;
BA_ "Version" SG_ 1007 ATS_RrMapRtOn_Req "20.06.09";
BA_ "Description" SG_ 1007 ATS_RrRoomOn_Req "Rear room lamp On/Off request";
BA_ "GenSigSendType" SG_ 1007 ATS_RrRoomOn_Req 4;
BA_ "UserSigValidity" SG_ 1007 ATS_RrRoomOn_Req 3;
BA_REL_ "GenSigTimeoutTime" BU_SG_REL_ CGW_CCU SG_ 1007 ATS_RrRoomOn_Req 0;
BA_ "NetworkRequest" SG_ 1007 ATS_RrRoomOn_Req 0;
BA_ "NetworkRequestHoldingTime" SG_ 1007 ATS_RrRoomOn_Req 5000;
BA_ "Version" SG_ 1007 ATS_RrRoomOn_Req "20.06.09";
BA_ "Description" SG_ 1007 ATS_LEDClrUpDn "This signal is  interior lamp color up/down control signal";
BA_ "GenSigSendType" SG_ 1007 ATS_LEDClrUpDn 4;
BA_ "UserSigValidity" SG_ 1007 ATS_LEDClrUpDn 3;
BA_REL_ "GenSigTimeoutTime" BU_SG_REL_ CGW_CCU SG_ 1007 ATS_LEDClrUpDn 0;
BA_ "Version" SG_ 1007 ATS_LEDClrUpDn "20.04.05";
BA_ "Description" SG_ 1007 ATS_RrMoodOn_Req "Rear mood lamp On/Off request";
BA_ "GenSigSendType" SG_ 1007 ATS_RrMoodOn_Req 4;
BA_ "UserSigValidity" SG_ 1007 ATS_RrMoodOn_Req 3;
BA_REL_ "GenSigTimeoutTime" BU_SG_REL_ CGW_CCU SG_ 1007 ATS_RrMoodOn_Req 0;
BA_ "NetworkRequest" SG_ 1007 ATS_RrMoodOn_Req 0;
BA_ "NetworkRequestHoldingTime" SG_ 1007 ATS_RrMoodOn_Req 5000;
BA_ "Version" SG_ 1007 ATS_RrMoodOn_Req "20.06.09";
BA_ "Description" SG_ 1007 ATS_LEDClr_Set "Interior Lamp LED Color Request";
BA_ "GenSigSendType" SG_ 1007 ATS_LEDClr_Set 4;
BA_ "UserSigValidity" SG_ 1007 ATS_LEDClr_Set 3;
BA_REL_ "GenSigTimeoutTime" BU_SG_REL_ CGW_CCU SG_ 1007 ATS_LEDClr_Set 0;
BA_ "NetworkRequest" SG_ 1007 ATS_LEDClr_Set 0;
BA_ "NetworkRequestHoldingTime" SG_ 1007 ATS_LEDClr_Set 5000;
BA_ "Version" SG_ 1007 ATS_LEDClr_Set "20.06.09";
BA_ "Description" SG_ 1007 ATS_LEDBgtns_Set "Interior Lamp LED Brightness Request";
BA_ "GenSigSendType" SG_ 1007 ATS_LEDBgtns_Set 4;
BA_ "UserSigValidity" SG_ 1007 ATS_LEDBgtns_Set 3;
BA_REL_ "GenSigTimeoutTime" BU_SG_REL_ CGW_CCU SG_ 1007 ATS_LEDBgtns_Set 0;
BA_ "NetworkRequest" SG_ 1007 ATS_LEDBgtns_Set 0;
BA_ "NetworkRequestHoldingTime" SG_ 1007 ATS_LEDBgtns_Set 5000;
BA_ "Version" SG_ 1007 ATS_LEDBgtns_Set "20.06.09";
BA_ "Description" SG_ 1007 ATS_FrMapLftOn_Req "Front left map lamp On/Off request";
BA_ "GenSigSendType" SG_ 1007 ATS_FrMapLftOn_Req 4;
BA_ "UserSigValidity" SG_ 1007 ATS_FrMapLftOn_Req 3;
BA_REL_ "GenSigTimeoutTime" BU_SG_REL_ CGW_CCU SG_ 1007 ATS_FrMapLftOn_Req 0;
BA_ "NetworkRequest" SG_ 1007 ATS_FrMapLftOn_Req 0;
BA_ "NetworkRequestHoldingTime" SG_ 1007 ATS_FrMapLftOn_Req 5000;
BA_ "Version" SG_ 1007 ATS_FrMapLftOn_Req "20.06.09";
BA_ "Description" SG_ 1007 ATS_FrMapRtOn_Req "Front right map lamp On/Off request";
BA_ "GenSigSendType" SG_ 1007 ATS_FrMapRtOn_Req 4;
BA_ "UserSigValidity" SG_ 1007 ATS_FrMapRtOn_Req 3;
BA_REL_ "GenSigTimeoutTime" BU_SG_REL_ CGW_CCU SG_ 1007 ATS_FrMapRtOn_Req 0;
BA_ "NetworkRequest" SG_ 1007 ATS_FrMapRtOn_Req 0;
BA_ "NetworkRequestHoldingTime" SG_ 1007 ATS_FrMapRtOn_Req 5000;
BA_ "Version" SG_ 1007 ATS_FrMapRtOn_Req "20.06.09";
BA_ "Description" SG_ 1007 ATS_FrRoomOn_Req "Front room lamp On/Off request";
BA_ "GenSigSendType" SG_ 1007 ATS_FrRoomOn_Req 4;
BA_ "UserSigValidity" SG_ 1007 ATS_FrRoomOn_Req 3;
BA_REL_ "GenSigTimeoutTime" BU_SG_REL_ CGW_CCU SG_ 1007 ATS_FrRoomOn_Req 0;
BA_ "NetworkRequest" SG_ 1007 ATS_FrRoomOn_Req 0;
BA_ "NetworkRequestHoldingTime" SG_ 1007 ATS_FrRoomOn_Req 5000;
BA_ "Version" SG_ 1007 ATS_FrRoomOn_Req "20.06.09";
BA_ "GenMsgSendType" BO_ 992 0;
BA_ "Description" SG_ 992 BCM_Crc2Val "The data area for CRC calculation is based on the data length (DLC) of the message DB.

The CRC shall be calculated over the entire data block (excluding the CRC bytes) including the user data, alive counter and Data ID 

 

- CRC Polynomial (0x1D) , Initial Value : 0x00, XOR value : 0xFF, Data ID Mode : Both, Data ID : Message ID + 0xF800 

- The initial value is for CRC calculation and the message should be sent with the calculated result value. 

The mathematical expression to 8 bit CRC polynomial is given here. G(x) = x8 + x4 + x3 + x2 + 1";
BA_ "GenSigSendType" SG_ 992 BCM_Crc2Val 4;
BA_ "GenSigStartValue" SG_ 992 BCM_Crc2Val 255;
BA_ "UserSigValidity" SG_ 992 BCM_Crc2Val 0;
BA_ "Version" SG_ 992 BCM_Crc2Val "18.11.08";
BA_ "Description" SG_ 992 BCM_AlvCnt2Val "For the first transmission request for a data element the counter shall be initialized with 0 and shall be incremented by 1

for every subsequent send request. When the counter reaches the maximum value(0xE), then it shall restart with 0 for the next send request";
BA_ "GenSigSendType" SG_ 992 BCM_AlvCnt2Val 4;
BA_ "UserSigValidity" SG_ 992 BCM_AlvCnt2Val 0;
BA_ "Version" SG_ 992 BCM_AlvCnt2Val "18.11.08";
BA_ "GenSigSendType" SG_ 992 BAlarm_BglrAlrmCurrentSta 4;
BA_ "UserSigValidity" SG_ 992 BAlarm_BglrAlrmCurrentSta 0;
BA_ "NetworkRequest" SG_ 992 BAlarm_BglrAlrmCurrentSta 0;
BA_ "NetworkRequestHoldingTime" SG_ 992 BAlarm_BglrAlrmCurrentSta 5000;
BA_ "Version" SG_ 992 BAlarm_BglrAlrmCurrentSta "17.12.00";
BA_ "GenSigSendType" SG_ 992 BAlarm_BglrAlrmSta 4;
BA_ "UserSigValidity" SG_ 992 BAlarm_BglrAlrmSta 0;
BA_ "NetworkRequest" SG_ 992 BAlarm_BglrAlrmSta 0;
BA_ "NetworkRequestHoldingTime" SG_ 992 BAlarm_BglrAlrmSta 5000;
BA_ "Version" SG_ 992 BAlarm_BglrAlrmSta "17.12.00";
BA_ "Description" SG_ 992 BAlarm_PncAlrmSta "-For TeleCranking Panic Function

-This signal send to IBOX";
BA_ "GenSigSendType" SG_ 992 BAlarm_PncAlrmSta 4;
BA_ "UserSigValidity" SG_ 992 BAlarm_PncAlrmSta 0;
BA_ "NetworkRequest" SG_ 992 BAlarm_PncAlrmSta 0;
BA_ "NetworkRequestHoldingTime" SG_ 992 BAlarm_PncAlrmSta 5000;
BA_ "Version" SG_ 992 BAlarm_PncAlrmSta "17.12.00";
BA_ "GenSigSendType" SG_ 992 BAlarm_BrglrHrnRlySta 4;
BA_ "UserSigValidity" SG_ 992 BAlarm_BrglrHrnRlySta 0;
BA_ "NetworkRequest" SG_ 992 BAlarm_BrglrHrnRlySta 0;
BA_ "NetworkRequestHoldingTime" SG_ 992 BAlarm_BrglrHrnRlySta 5000;
BA_ "Version" SG_ 992 BAlarm_BrglrHrnRlySta "17.12.00";
BA_ "Description" SG_ 992 BAlarm_ROABglrAlrmSta "IBU→ ROA, EngineState Info Tx";
BA_ "GenSigSendType" SG_ 992 BAlarm_ROABglrAlrmSta 4;
BA_ "UserSigValidity" SG_ 992 BAlarm_ROABglrAlrmSta 0;
BA_ "NetworkRequest" SG_ 992 BAlarm_ROABglrAlrmSta 0;
BA_ "NetworkRequestHoldingTime" SG_ 992 BAlarm_ROABglrAlrmSta 5000;
BA_ "Version" SG_ 992 BAlarm_ROABglrAlrmSta "19.12.08";
BA_ "Description" SG_ 992 BCM_KeyInSta "Mechanical Key In SW State (If SMK option is On, C_KeyInSw always have  Off

 value)";
BA_ "GenSigSendType" SG_ 992 BCM_KeyInSta 4;
BA_ "UserSigValidity" SG_ 992 BCM_KeyInSta 0;
BA_ "NetworkRequest" SG_ 992 BCM_KeyInSta 0;
BA_ "NetworkRequestHoldingTime" SG_ 992 BCM_KeyInSta 5000;
BA_ "Version" SG_ 992 BCM_KeyInSta "17.12.00";
BA_ "GenSigSendType" SG_ 992 BCM_AccInSta 4;
BA_ "UserSigValidity" SG_ 992 BCM_AccInSta 0;
BA_REL_ "GenSigTimeoutTime" BU_SG_REL_ PSM SG_ 992 BCM_AccInSta 1500;
BA_REL_ "GenSigTimeoutTime" BU_SG_REL_ APSM SG_ 992 BCM_AccInSta 1500;
BA_REL_ "GenSigTimeoutTime" BU_SG_REL_ RLPSM SG_ 992 BCM_AccInSta 1500;
BA_REL_ "GenSigTimeoutTime" BU_SG_REL_ RRPSM SG_ 992 BCM_AccInSta 1500;
BA_REL_ "GenSigTimeoutTime" BU_SG_REL_ RDC SG_ 992 BCM_AccInSta 1500;
BA_REL_ "GenSigTimeoutTime" BU_SG_REL_ ATS SG_ 992 BCM_AccInSta 1500;
BA_REL_ "GenSigTimeoutTime" BU_SG_REL_ DSAU SG_ 992 BCM_AccInSta 1500;
BA_REL_ "GenSigTimeoutTime" BU_SG_REL_ ASAU SG_ 992 BCM_AccInSta 1500;
BA_ "NetworkRequest" SG_ 992 BCM_AccInSta 0;
BA_ "NetworkRequestHoldingTime" SG_ 992 BCM_AccInSta 5000;
BA_ "Version" SG_ 992 BCM_AccInSta "17.12.00";
BA_ "GenSigSendType" SG_ 992 BCM_Ign1InSta 4;
BA_ "UserSigValidity" SG_ 992 BCM_Ign1InSta 0;
BA_REL_ "GenSigTimeoutTime" BU_SG_REL_ PSM SG_ 992 BCM_Ign1InSta 1500;
BA_REL_ "GenSigTimeoutTime" BU_SG_REL_ APSM SG_ 992 BCM_Ign1InSta 1500;
BA_REL_ "GenSigTimeoutTime" BU_SG_REL_ RLPSM SG_ 992 BCM_Ign1InSta 1500;
BA_REL_ "GenSigTimeoutTime" BU_SG_REL_ RRPSM SG_ 992 BCM_Ign1InSta 1500;
BA_REL_ "GenSigTimeoutTime" BU_SG_REL_ RDC SG_ 992 BCM_Ign1InSta 1500;
BA_REL_ "GenSigTimeoutTime" BU_SG_REL_ ATS SG_ 992 BCM_Ign1InSta 1500;
BA_REL_ "GenSigTimeoutTime" BU_SG_REL_ DSAU SG_ 992 BCM_Ign1InSta 1500;
BA_REL_ "GenSigTimeoutTime" BU_SG_REL_ ASAU SG_ 992 BCM_Ign1InSta 1500;
BA_ "NetworkRequest" SG_ 992 BCM_Ign1InSta 0;
BA_ "NetworkRequestHoldingTime" SG_ 992 BCM_Ign1InSta 5000;
BA_ "Version" SG_ 992 BCM_Ign1InSta "17.12.00";
BA_ "GenSigSendType" SG_ 992 BCM_Ign2InSta 4;
BA_ "UserSigValidity" SG_ 992 BCM_Ign2InSta 0;
BA_REL_ "GenSigTimeoutTime" BU_SG_REL_ PSM SG_ 992 BCM_Ign2InSta 1500;
BA_REL_ "GenSigTimeoutTime" BU_SG_REL_ APSM SG_ 992 BCM_Ign2InSta 1500;
BA_REL_ "GenSigTimeoutTime" BU_SG_REL_ RLPSM SG_ 992 BCM_Ign2InSta 1500;
BA_REL_ "GenSigTimeoutTime" BU_SG_REL_ RRPSM SG_ 992 BCM_Ign2InSta 1500;
BA_REL_ "GenSigTimeoutTime" BU_SG_REL_ RLHV SG_ 992 BCM_Ign2InSta 1500;
BA_REL_ "GenSigTimeoutTime" BU_SG_REL_ RRHV SG_ 992 BCM_Ign2InSta 1500;
BA_REL_ "GenSigTimeoutTime" BU_SG_REL_ SHVU_RR SG_ 992 BCM_Ign2InSta 1500;
BA_REL_ "GenSigTimeoutTime" BU_SG_REL_ RDC SG_ 992 BCM_Ign2InSta 1500;
BA_REL_ "GenSigTimeoutTime" BU_SG_REL_ ATS SG_ 992 BCM_Ign2InSta 1500;
BA_REL_ "GenSigTimeoutTime" BU_SG_REL_ DSAU SG_ 992 BCM_Ign2InSta 1500;
BA_REL_ "GenSigTimeoutTime" BU_SG_REL_ ASAU SG_ 992 BCM_Ign2InSta 1500;
BA_ "NetworkRequest" SG_ 992 BCM_Ign2InSta 0;
BA_ "NetworkRequestHoldingTime" SG_ 992 BCM_Ign2InSta 5000;
BA_ "Version" SG_ 992 BCM_Ign2InSta "17.12.00";
BA_ "GenSigSendType" SG_ 992 BCM_IgnSwSta 4;
BA_ "UserSigValidity" SG_ 992 BCM_IgnSwSta 0;
BA_REL_ "GenSigTimeoutTime" BU_SG_REL_ RWPC SG_ 992 BCM_IgnSwSta 1500;
BA_REL_ "GenSigTimeoutTime" BU_SG_REL_ PSM SG_ 992 BCM_IgnSwSta 1500;
BA_REL_ "GenSigTimeoutTime" BU_SG_REL_ APSM SG_ 992 BCM_IgnSwSta 1500;
BA_REL_ "GenSigTimeoutTime" BU_SG_REL_ RLPSM SG_ 992 BCM_IgnSwSta 1500;
BA_REL_ "GenSigTimeoutTime" BU_SG_REL_ RRPSM SG_ 992 BCM_IgnSwSta 1500;
BA_REL_ "GenSigTimeoutTime" BU_SG_REL_ SHVU_RR SG_ 992 BCM_IgnSwSta 1500;
BA_REL_ "GenSigTimeoutTime" BU_SG_REL_ RDC SG_ 992 BCM_IgnSwSta 1500;
BA_REL_ "GenSigTimeoutTime" BU_SG_REL_ DPSS SG_ 992 BCM_IgnSwSta 1500;
BA_REL_ "GenSigTimeoutTime" BU_SG_REL_ APSS SG_ 992 BCM_IgnSwSta 1500;
BA_REL_ "GenSigTimeoutTime" BU_SG_REL_ ATS SG_ 992 BCM_IgnSwSta 1500;
BA_REL_ "GenSigTimeoutTime" BU_SG_REL_ DSAU SG_ 992 BCM_IgnSwSta 1500;
BA_REL_ "GenSigTimeoutTime" BU_SG_REL_ ASAU SG_ 992 BCM_IgnSwSta 1500;
BA_ "NetworkRequest" SG_ 992 BCM_IgnSwSta 0;
BA_ "NetworkRequestHoldingTime" SG_ 992 BCM_IgnSwSta 5000;
BA_ "Version" SG_ 992 BCM_IgnSwSta "17.12.00";
BA_ "GenMsgSendType" BO_ 916 0;
BA_ "Description" SG_ 916 BCM_Crc19Val "The data area for CRC calculation is based on the data length (DLC) of the message DB.

The CRC shall be calculated over the entire data block (excluding the CRC bytes) including the user data, alive counter and Data ID 

 

- CRC Polynomial (0x1D) , Initial Value : 0x00, XOR value : 0xFF, Data ID Mode : Both, Data ID : Message ID + 0xF800 

- The initial value is for CRC calculation and the message should be sent with the calculated result value. 

The mathematical expression to 8 bit CRC polynomial is given here. G(x) = x8 + x4 + x3 + x2 + 1";
BA_ "GenSigSendType" SG_ 916 BCM_Crc19Val 4;
BA_ "GenSigStartValue" SG_ 916 BCM_Crc19Val 255;
BA_ "UserSigValidity" SG_ 916 BCM_Crc19Val 0;
BA_ "Version" SG_ 916 BCM_Crc19Val "19.07.02";
BA_ "Description" SG_ 916 BCM_AlvCnt19Val "For the first transmission request for a data element the counter shall be initialized with 0 and shall be incremented by 1

for every subsequent send request. When the counter reaches the maximum value(0xE), then it shall restart with 0 for the next send request";
BA_ "GenSigSendType" SG_ 916 BCM_AlvCnt19Val 4;
BA_ "UserSigValidity" SG_ 916 BCM_AlvCnt19Val 0;
BA_ "Version" SG_ 916 BCM_AlvCnt19Val "19.07.02";
BA_ "Description" SG_ 916 USM_IBU_AutoDrUnLkReq "USM_AutoDoorUnLockRequest ##2G## -  - CF_Gway_ADrURValue";
BA_ "GenSigSendType" SG_ 916 USM_IBU_AutoDrUnLkReq 4;
BA_ "UserSigValidity" SG_ 916 USM_IBU_AutoDrUnLkReq 0;
BA_ "NetworkRequest" SG_ 916 USM_IBU_AutoDrUnLkReq 0;
BA_ "NetworkRequestHoldingTime" SG_ 916 USM_IBU_AutoDrUnLkReq 5000;
BA_ "Version" SG_ 916 USM_IBU_AutoDrUnLkReq "19.07.02";
BA_ "Description" SG_ 916 IBU_TwoTrnUnLkOptTyp "-(Old)C_TTUnlockOpt";
BA_ "GenSigSendType" SG_ 916 IBU_TwoTrnUnLkOptTyp 4;
BA_ "UserSigValidity" SG_ 916 IBU_TwoTrnUnLkOptTyp 0;
BA_ "NetworkRequest" SG_ 916 IBU_TwoTrnUnLkOptTyp 0;
BA_ "NetworkRequestHoldingTime" SG_ 916 IBU_TwoTrnUnLkOptTyp 5000;
BA_ "Version" SG_ 916 IBU_TwoTrnUnLkOptTyp "19.07.02";
BA_ "Description" SG_ 916 USM_IBU_TwoTrnUnLkCurrentSta "USM_TwoTurnUnlockCurrentStatus ##2G## -  - CF_Gway_TTUnlockRValue";
BA_ "GenSigSendType" SG_ 916 USM_IBU_TwoTrnUnLkCurrentSta 4;
BA_ "UserSigValidity" SG_ 916 USM_IBU_TwoTrnUnLkCurrentSta 0;
BA_ "NetworkRequest" SG_ 916 USM_IBU_TwoTrnUnLkCurrentSta 0;
BA_ "NetworkRequestHoldingTime" SG_ 916 USM_IBU_TwoTrnUnLkCurrentSta 5000;
BA_ "Version" SG_ 916 USM_IBU_TwoTrnUnLkCurrentSta "19.07.02";
BA_ "Description" SG_ 916 DoorLock_ADrLOptInfo "Smart key and transmission option information for auto door lock/unlock USM";
BA_ "GenSigSendType" SG_ 916 DoorLock_ADrLOptInfo 4;
BA_ "UserSigValidity" SG_ 916 DoorLock_ADrLOptInfo 1;
BA_ "NetworkRequest" SG_ 916 DoorLock_ADrLOptInfo 0;
BA_ "NetworkRequestHoldingTime" SG_ 916 DoorLock_ADrLOptInfo 5000;
BA_ "Version" SG_ 916 DoorLock_ADrLOptInfo "19.07.02";
BA_ "Description" SG_ 916 USM_IBU_RemoteWDWCurrentSta "Remote Window IBU USM function signal";
BA_ "GenSigSendType" SG_ 916 USM_IBU_RemoteWDWCurrentSta 4;
BA_ "UserSigValidity" SG_ 916 USM_IBU_RemoteWDWCurrentSta 0;
BA_REL_ "GenSigTimeoutTime" BU_SG_REL_ RDC SG_ 916 USM_IBU_RemoteWDWCurrentSta 1500;
BA_ "NetworkRequest" SG_ 916 USM_IBU_RemoteWDWCurrentSta 0;
BA_ "NetworkRequestHoldingTime" SG_ 916 USM_IBU_RemoteWDWCurrentSta 5000;
BA_ "Version" SG_ 916 USM_IBU_RemoteWDWCurrentSta "20.08.02";
BA_ "Description" SG_ 916 IBU_VitalityCurtainSta "Current setting value for rear-curtain of mood-therapy.";
BA_ "GenSigSendType" SG_ 916 IBU_VitalityCurtainSta 4;
BA_ "UserSigValidity" SG_ 916 IBU_VitalityCurtainSta 0;
BA_REL_ "GenSigTimeoutTime" BU_SG_REL_ RDC SG_ 916 IBU_VitalityCurtainSta 1500;
BA_ "NetworkRequest" SG_ 916 IBU_VitalityCurtainSta 0;
BA_ "NetworkRequestHoldingTime" SG_ 916 IBU_VitalityCurtainSta 5000;
BA_ "Version" SG_ 916 IBU_VitalityCurtainSta "20.07.10";
BA_ "Description" SG_ 916 IBU_DelightCurtainSta "Current setting value for rear-curtain of mood-therapy.";
BA_ "GenSigSendType" SG_ 916 IBU_DelightCurtainSta 4;
BA_ "UserSigValidity" SG_ 916 IBU_DelightCurtainSta 0;
BA_REL_ "GenSigTimeoutTime" BU_SG_REL_ RDC SG_ 916 IBU_DelightCurtainSta 1500;
BA_ "NetworkRequest" SG_ 916 IBU_DelightCurtainSta 0;
BA_ "NetworkRequestHoldingTime" SG_ 916 IBU_DelightCurtainSta 5000;
BA_ "Version" SG_ 916 IBU_DelightCurtainSta "20.07.10";
BA_ "Description" SG_ 916 IBU_CareCurtainSta "Current setting value for rear curtain of mood-therapy.";
BA_ "GenSigSendType" SG_ 916 IBU_CareCurtainSta 4;
BA_ "UserSigValidity" SG_ 916 IBU_CareCurtainSta 0;
BA_REL_ "GenSigTimeoutTime" BU_SG_REL_ RDC SG_ 916 IBU_CareCurtainSta 1500;
BA_ "NetworkRequest" SG_ 916 IBU_CareCurtainSta 0;
BA_ "NetworkRequestHoldingTime" SG_ 916 IBU_CareCurtainSta 5000;
BA_ "Version" SG_ 916 IBU_CareCurtainSta "20.07.10";
BA_ "Description" SG_ 916 IBU_ComfortCurtainSta "Current setting value for rear curtain of mood-therapy.";
BA_ "GenSigSendType" SG_ 916 IBU_ComfortCurtainSta 4;
BA_ "UserSigValidity" SG_ 916 IBU_ComfortCurtainSta 0;
BA_REL_ "GenSigTimeoutTime" BU_SG_REL_ RDC SG_ 916 IBU_ComfortCurtainSta 1500;
BA_ "NetworkRequest" SG_ 916 IBU_ComfortCurtainSta 0;
BA_ "NetworkRequestHoldingTime" SG_ 916 IBU_ComfortCurtainSta 5000;
BA_ "Version" SG_ 916 IBU_ComfortCurtainSta "20.07.10";
BA_ "Description" SG_ 916 USM_IBU_AutoDrLkReq2 "USM_AutoDoorLockRequest";
BA_ "GenSigSendType" SG_ 916 USM_IBU_AutoDrLkReq2 4;
BA_ "UserSigValidity" SG_ 916 USM_IBU_AutoDrLkReq2 0;
BA_ "NetworkRequest" SG_ 916 USM_IBU_AutoDrLkReq2 0;
BA_ "NetworkRequestHoldingTime" SG_ 916 USM_IBU_AutoDrLkReq2 5000;
BA_ "Version" SG_ 916 USM_IBU_AutoDrLkReq2 "20.10.02";
BA_ "Description" SG_ 916 USM_1stRrStRmndSta "Rear Occupant Alert IBU(1st Only) USM function signal(RADAR Sensor unused)";
BA_ "GenSigSendType" SG_ 916 USM_1stRrStRmndSta 4;
BA_ "UserSigValidity" SG_ 916 USM_1stRrStRmndSta 0;
BA_ "NetworkRequest" SG_ 916 USM_1stRrStRmndSta 0;
BA_ "NetworkRequestHoldingTime" SG_ 916 USM_1stRrStRmndSta 5000;
BA_ "Version" SG_ 916 USM_1stRrStRmndSta "19.12.08";
BA_ "GenMsgCycleTime" BO_ 2470763265 0;
BA_ "VFrameFormat" BO_ 2470763265 1;
BA_ "Description" SG_ 2470763265 USM_AdasDSWSetReq "This signal is used for a request to set the value of USM Menus. This signal requests to change status of DSW.";
BA_ "GenSigSendType" SG_ 2470763265 USM_AdasDSWSetReq 4;
BA_ "UserSigValidity" SG_ 2470763265 USM_AdasDSWSetReq 3;
BA_REL_ "GenSigTimeoutTime" BU_SG_REL_ ICC SG_ 2470763265 USM_AdasDSWSetReq 0;
BA_ "Version" SG_ 2470763265 USM_AdasDSWSetReq "20.12.01";
BA_ "GenMsgSendType" BO_ 2382594817 0;
BA_ "VFrameFormat" BO_ 2382594817 1;
BA_ "Description" SG_ 2382594817 DATC_Crc6Val "The data area for CRC calculation is based on the data length (DLC) of the message DB.

The CRC shall be calculated over the entire data block (excluding the CRC bytes) including the user data, alive counter and Data ID

 

- CRC Polynomial (0x1021) , Initial Value : 0xFFFF, XOR value : 0x0000, Data ID : Message ID + 0xF800 

- The initial value is for CRC calculation and the message should be sent with the calculated result value. 

- The mathematical expression to 16 bit CRC polynomial is given here. G(x) = x16 + x12 + x5 + 1";
BA_ "GenSigSendType" SG_ 2382594817 DATC_Crc6Val 4;
BA_ "GenSigStartValue" SG_ 2382594817 DATC_Crc6Val 65535;
BA_ "UserSigValidity" SG_ 2382594817 DATC_Crc6Val 3;
BA_ "Version" SG_ 2382594817 DATC_Crc6Val "18.11.08";
BA_ "Description" SG_ 2382594817 DATC_AlvCnt6Val "For the first transmission request for a data element the counter shall be initialized with 0 and shall be incremented by 1 for every subsequent send request. 

When the counter reaches the maximum value(0xFF), then it shall restart with 0 for the next send request";
BA_ "GenSigSendType" SG_ 2382594817 DATC_AlvCnt6Val 4;
BA_ "UserSigValidity" SG_ 2382594817 DATC_AlvCnt6Val 3;
BA_ "Version" SG_ 2382594817 DATC_AlvCnt6Val "18.11.08";
BA_ "Description" SG_ 2382594817 DATC_SyncDis "This signal indicates DUAL Graphic On & Off.

This signal occurs when DUAL switch(button) is selected either manually or automatically.";
BA_ "GenSigSendType" SG_ 2382594817 DATC_SyncDis 4;
BA_ "UserSigValidity" SG_ 2382594817 DATC_SyncDis 6;
BA_REL_ "GenSigTimeoutTime" BU_SG_REL_ ATS SG_ 2382594817 DATC_SyncDis 1500;
BA_ "Version" SG_ 2382594817 DATC_SyncDis "17.11.00";
BA_ "Description" SG_ 2382594817 DATC_OpSta "This signal indicates Operating status of DATC.";
BA_ "GenSigSendType" SG_ 2382594817 DATC_OpSta 4;
BA_ "UserSigValidity" SG_ 2382594817 DATC_OpSta 6;
BA_REL_ "GenSigTimeoutTime" BU_SG_REL_ ATS SG_ 2382594817 DATC_OpSta 1500;
BA_ "Version" SG_ 2382594817 DATC_OpSta "17.11.00";
BA_ "Description" SG_ 2382594817 DATC_FrDfgSta "This signal indicates DEF LED On & Off.

This signal occurs when DEF switch(button) is selected manually.";
BA_ "GenSigSendType" SG_ 2382594817 DATC_FrDfgSta 4;
BA_ "UserSigValidity" SG_ 2382594817 DATC_FrDfgSta 6;
BA_ "Version" SG_ 2382594817 DATC_FrDfgSta "17.11.00";
BA_ "Description" SG_ 2382594817 DATC_SmrtVntDis "Display Smart  Ventilation / Smart CO2  Ventilation";
BA_ "GenSigSendType" SG_ 2382594817 DATC_SmrtVntDis 4;
BA_ "UserSigValidity" SG_ 2382594817 DATC_SmrtVntDis 3;
BA_ "Version" SG_ 2382594817 DATC_SmrtVntDis "17.11.00";
BA_ "Description" SG_ 2382594817 DATC_AutoDfgBlnkDis "This signal indicates that Auto Defog LED blinks On & Off.

This signal occurs when Auto Defog system operates automatically.";
BA_ "GenSigSendType" SG_ 2382594817 DATC_AutoDfgBlnkDis 4;
BA_ "UserSigValidity" SG_ 2382594817 DATC_AutoDfgBlnkDis 6;
BA_ "Version" SG_ 2382594817 DATC_AutoDfgBlnkDis "17.11.00";
BA_ "Description" SG_ 2382594817 DATC_AutoDfgSysOffDis "Display Auto Defog System Off (When the user does not  use Auto Defog System on purpose)";
BA_ "GenSigSendType" SG_ 2382594817 DATC_AutoDfgSysOffDis 4;
BA_ "GenSigStartValue" SG_ 2382594817 DATC_AutoDfgSysOffDis 2;
BA_ "UserSigValidity" SG_ 2382594817 DATC_AutoDfgSysOffDis 3;
BA_ "Version" SG_ 2382594817 DATC_AutoDfgSysOffDis "17.11.00";
BA_ "Description" SG_ 2382594817 DATC_ArClnIND "This signal indicates Status of AirClean Button Indicator for MultiKeyboard.";
BA_ "GenSigSendType" SG_ 2382594817 DATC_ArClnIND 4;
BA_ "UserSigValidity" SG_ 2382594817 DATC_ArClnIND 7;
BA_REL_ "GenSigTimeoutTime" BU_SG_REL_ ATS SG_ 2382594817 DATC_ArClnIND 1500;
BA_ "Version" SG_ 2382594817 DATC_ArClnIND "19.08.03";
BA_ "GenMsgSendType" BO_ 907 0;
BA_ "Description" SG_ 907 FPM_Crc11Val "The data area for CRC calculation is based on the data length (DLC) of the message DB.

The CRC shall be calculated over the entire data block (excluding the CRC bytes) including the user data, alive counter and Data ID 

 

- CRC Polynomial (0x1D) , Initial Value : 0x00, XOR value : 0xFF, Data ID Mode : Both, Data ID : Message ID + 0xF800 

- The initial value is for CRC calculation and the message should be sent with the calculated result value. 

The mathematical expression to 8 bit CRC polynomial is given here. G(x) = x8 + x4 + x3 + x2 + 1";
BA_ "GenSigSendType" SG_ 907 FPM_Crc11Val 4;
BA_ "GenSigStartValue" SG_ 907 FPM_Crc11Val 255;
BA_ "UserSigValidity" SG_ 907 FPM_Crc11Val 3;
BA_ "Version" SG_ 907 FPM_Crc11Val "21.03.01";
BA_ "Description" SG_ 907 FPM_AlvCnt11Val "For the first transmission request for a data element the counter shall be initialized with 0 and shall be incremented by 1

for every subsequent send request. When the counter reaches the maximum value(0xE), then it shall restart with 0 for the next send request";
BA_ "GenSigSendType" SG_ 907 FPM_AlvCnt11Val 4;
BA_ "UserSigValidity" SG_ 907 FPM_AlvCnt11Val 3;
BA_ "Version" SG_ 907 FPM_AlvCnt11Val "21.03.01";
BA_ "Description" SG_ 907 FPM2AVN_H2PV "This signal is for checking crypto communication between FPM and AVN. 

Refer to AVN-FPM Crypto Communication Specification for detailed specifications.";
BA_ "GenSigSendType" SG_ 907 FPM2AVN_H2PV 4;
BA_ "UserSigValidity" SG_ 907 FPM2AVN_H2PV 0;
BA_REL_ "GenSigTimeoutTime" BU_SG_REL_ CGW_CCU SG_ 907 FPM2AVN_H2PV 1500;
BA_ "Version" SG_ 907 FPM2AVN_H2PV "21.07.05";
BA_ "Description" SG_ 907 FPM2IAU_H2PV "This signal is for checking crypto communication between FPM and IAU. 

Refer to IAU-FPM Crypto Communication Specification for detailed specifications.";
BA_ "GenSigSendType" SG_ 907 FPM2IAU_H2PV 4;
BA_ "UserSigValidity" SG_ 907 FPM2IAU_H2PV 0;
BA_REL_ "GenSigTimeoutTime" BU_SG_REL_ CGW_CCU SG_ 907 FPM2IAU_H2PV 1500;
BA_ "Version" SG_ 907 FPM2IAU_H2PV "21.03.01";
BA_ "GenMsgCycleTime" BO_ 2015 0;
BA_ "GenMsgCycleTimeFast" BO_ 2015 0;
BA_ "GenMsgNrOfRepetition" BO_ 2015 0;
BA_ "DiagState" BO_ 2015 1;
BA_ "GenMsgILSupport" BO_ 2015 0;
BA_ "TpMessage" BO_ 2015 1;
BA_ "Description" SG_ 2015 GST_ALL_Byte0 "TP Index : 0";
BA_ "UsrSigPurpose" SG_ 2015 GST_ALL_Byte0 0;
BA_ "UserSigValidity" SG_ 2015 GST_ALL_Byte0 0;
BA_REL_ "GenSigTimeoutTime" BU_SG_REL_ RWPC SG_ 2015 GST_ALL_Byte0 0;
BA_REL_ "GenSigTimeoutTime" BU_SG_REL_ PSM SG_ 2015 GST_ALL_Byte0 0;
BA_REL_ "GenSigTimeoutTime" BU_SG_REL_ APSM SG_ 2015 GST_ALL_Byte0 0;
BA_REL_ "GenSigTimeoutTime" BU_SG_REL_ RLPSM SG_ 2015 GST_ALL_Byte0 0;
BA_REL_ "GenSigTimeoutTime" BU_SG_REL_ RRPSM SG_ 2015 GST_ALL_Byte0 0;
BA_REL_ "GenSigTimeoutTime" BU_SG_REL_ RLHV SG_ 2015 GST_ALL_Byte0 0;
BA_REL_ "GenSigTimeoutTime" BU_SG_REL_ RRHV SG_ 2015 GST_ALL_Byte0 0;
BA_REL_ "GenSigTimeoutTime" BU_SG_REL_ SHVU_RR SG_ 2015 GST_ALL_Byte0 0;
BA_REL_ "GenSigTimeoutTime" BU_SG_REL_ RDC SG_ 2015 GST_ALL_Byte0 0;
BA_REL_ "GenSigTimeoutTime" BU_SG_REL_ DPSS SG_ 2015 GST_ALL_Byte0 0;
BA_REL_ "GenSigTimeoutTime" BU_SG_REL_ AMP SG_ 2015 GST_ALL_Byte0 0;
BA_REL_ "GenSigTimeoutTime" BU_SG_REL_ vHS_M SG_ 2015 GST_ALL_Byte0 0;
BA_REL_ "GenSigTimeoutTime" BU_SG_REL_ APSS SG_ 2015 GST_ALL_Byte0 0;
BA_REL_ "GenSigTimeoutTime" BU_SG_REL_ FPM SG_ 2015 GST_ALL_Byte0 0;
BA_REL_ "GenSigTimeoutTime" BU_SG_REL_ ATS SG_ 2015 GST_ALL_Byte0 0;
BA_REL_ "GenSigTimeoutTime" BU_SG_REL_ DSAU SG_ 2015 GST_ALL_Byte0 0;
BA_REL_ "GenSigTimeoutTime" BU_SG_REL_ ASAU SG_ 2015 GST_ALL_Byte0 0;
BA_ "NetworkRequest" SG_ 2015 GST_ALL_Byte0 0;
BA_ "NetworkRequestHoldingTime" SG_ 2015 GST_ALL_Byte0 5000;
BA_ "Version" SG_ 2015 GST_ALL_Byte0 "21.02.04";
BA_ "Description" SG_ 2015 GST_ALL_Byte2 "TP Index : 0";
BA_ "UsrSigPurpose" SG_ 2015 GST_ALL_Byte2 0;
BA_ "UserSigValidity" SG_ 2015 GST_ALL_Byte2 0;
BA_REL_ "GenSigTimeoutTime" BU_SG_REL_ RWPC SG_ 2015 GST_ALL_Byte2 0;
BA_REL_ "GenSigTimeoutTime" BU_SG_REL_ PSM SG_ 2015 GST_ALL_Byte2 0;
BA_REL_ "GenSigTimeoutTime" BU_SG_REL_ APSM SG_ 2015 GST_ALL_Byte2 0;
BA_REL_ "GenSigTimeoutTime" BU_SG_REL_ RLPSM SG_ 2015 GST_ALL_Byte2 0;
BA_REL_ "GenSigTimeoutTime" BU_SG_REL_ RRPSM SG_ 2015 GST_ALL_Byte2 0;
BA_REL_ "GenSigTimeoutTime" BU_SG_REL_ RLHV SG_ 2015 GST_ALL_Byte2 0;
BA_REL_ "GenSigTimeoutTime" BU_SG_REL_ RRHV SG_ 2015 GST_ALL_Byte2 0;
BA_REL_ "GenSigTimeoutTime" BU_SG_REL_ SHVU_RR SG_ 2015 GST_ALL_Byte2 0;
BA_REL_ "GenSigTimeoutTime" BU_SG_REL_ RDC SG_ 2015 GST_ALL_Byte2 0;
BA_REL_ "GenSigTimeoutTime" BU_SG_REL_ DPSS SG_ 2015 GST_ALL_Byte2 0;
BA_REL_ "GenSigTimeoutTime" BU_SG_REL_ AMP SG_ 2015 GST_ALL_Byte2 0;
BA_REL_ "GenSigTimeoutTime" BU_SG_REL_ vHS_M SG_ 2015 GST_ALL_Byte2 0;
BA_REL_ "GenSigTimeoutTime" BU_SG_REL_ APSS SG_ 2015 GST_ALL_Byte2 0;
BA_REL_ "GenSigTimeoutTime" BU_SG_REL_ FPM SG_ 2015 GST_ALL_Byte2 0;
BA_REL_ "GenSigTimeoutTime" BU_SG_REL_ ATS SG_ 2015 GST_ALL_Byte2 0;
BA_REL_ "GenSigTimeoutTime" BU_SG_REL_ DSAU SG_ 2015 GST_ALL_Byte2 0;
BA_REL_ "GenSigTimeoutTime" BU_SG_REL_ ASAU SG_ 2015 GST_ALL_Byte2 0;
BA_ "NetworkRequest" SG_ 2015 GST_ALL_Byte2 0;
BA_ "NetworkRequestHoldingTime" SG_ 2015 GST_ALL_Byte2 5000;
BA_ "Version" SG_ 2015 GST_ALL_Byte2 "21.02.04";
BA_ "Description" SG_ 2015 GST_ALL_Byte3 "TP Index : 0";
BA_ "UsrSigPurpose" SG_ 2015 GST_ALL_Byte3 0;
BA_ "UserSigValidity" SG_ 2015 GST_ALL_Byte3 0;
BA_REL_ "GenSigTimeoutTime" BU_SG_REL_ RWPC SG_ 2015 GST_ALL_Byte3 0;
BA_REL_ "GenSigTimeoutTime" BU_SG_REL_ PSM SG_ 2015 GST_ALL_Byte3 0;
BA_REL_ "GenSigTimeoutTime" BU_SG_REL_ APSM SG_ 2015 GST_ALL_Byte3 0;
BA_REL_ "GenSigTimeoutTime" BU_SG_REL_ RLPSM SG_ 2015 GST_ALL_Byte3 0;
BA_REL_ "GenSigTimeoutTime" BU_SG_REL_ RRPSM SG_ 2015 GST_ALL_Byte3 0;
BA_REL_ "GenSigTimeoutTime" BU_SG_REL_ RLHV SG_ 2015 GST_ALL_Byte3 0;
BA_REL_ "GenSigTimeoutTime" BU_SG_REL_ RRHV SG_ 2015 GST_ALL_Byte3 0;
BA_REL_ "GenSigTimeoutTime" BU_SG_REL_ SHVU_RR SG_ 2015 GST_ALL_Byte3 0;
BA_REL_ "GenSigTimeoutTime" BU_SG_REL_ RDC SG_ 2015 GST_ALL_Byte3 0;
BA_REL_ "GenSigTimeoutTime" BU_SG_REL_ DPSS SG_ 2015 GST_ALL_Byte3 0;
BA_REL_ "GenSigTimeoutTime" BU_SG_REL_ AMP SG_ 2015 GST_ALL_Byte3 0;
BA_REL_ "GenSigTimeoutTime" BU_SG_REL_ vHS_M SG_ 2015 GST_ALL_Byte3 0;
BA_REL_ "GenSigTimeoutTime" BU_SG_REL_ APSS SG_ 2015 GST_ALL_Byte3 0;
BA_REL_ "GenSigTimeoutTime" BU_SG_REL_ FPM SG_ 2015 GST_ALL_Byte3 0;
BA_REL_ "GenSigTimeoutTime" BU_SG_REL_ ATS SG_ 2015 GST_ALL_Byte3 0;
BA_REL_ "GenSigTimeoutTime" BU_SG_REL_ DSAU SG_ 2015 GST_ALL_Byte3 0;
BA_REL_ "GenSigTimeoutTime" BU_SG_REL_ ASAU SG_ 2015 GST_ALL_Byte3 0;
BA_ "NetworkRequest" SG_ 2015 GST_ALL_Byte3 0;
BA_ "NetworkRequestHoldingTime" SG_ 2015 GST_ALL_Byte3 5000;
BA_ "Version" SG_ 2015 GST_ALL_Byte3 "21.02.04";
BA_ "Description" SG_ 2015 GST_ALL_Byte4 "TP Index : 0";
BA_ "UsrSigPurpose" SG_ 2015 GST_ALL_Byte4 0;
BA_ "UserSigValidity" SG_ 2015 GST_ALL_Byte4 0;
BA_REL_ "GenSigTimeoutTime" BU_SG_REL_ RWPC SG_ 2015 GST_ALL_Byte4 0;
BA_REL_ "GenSigTimeoutTime" BU_SG_REL_ PSM SG_ 2015 GST_ALL_Byte4 0;
BA_REL_ "GenSigTimeoutTime" BU_SG_REL_ APSM SG_ 2015 GST_ALL_Byte4 0;
BA_REL_ "GenSigTimeoutTime" BU_SG_REL_ RLPSM SG_ 2015 GST_ALL_Byte4 0;
BA_REL_ "GenSigTimeoutTime" BU_SG_REL_ RRPSM SG_ 2015 GST_ALL_Byte4 0;
BA_REL_ "GenSigTimeoutTime" BU_SG_REL_ RLHV SG_ 2015 GST_ALL_Byte4 0;
BA_REL_ "GenSigTimeoutTime" BU_SG_REL_ RRHV SG_ 2015 GST_ALL_Byte4 0;
BA_REL_ "GenSigTimeoutTime" BU_SG_REL_ SHVU_RR SG_ 2015 GST_ALL_Byte4 0;
BA_REL_ "GenSigTimeoutTime" BU_SG_REL_ RDC SG_ 2015 GST_ALL_Byte4 0;
BA_REL_ "GenSigTimeoutTime" BU_SG_REL_ DPSS SG_ 2015 GST_ALL_Byte4 0;
BA_REL_ "GenSigTimeoutTime" BU_SG_REL_ AMP SG_ 2015 GST_ALL_Byte4 0;
BA_REL_ "GenSigTimeoutTime" BU_SG_REL_ vHS_M SG_ 2015 GST_ALL_Byte4 0;
BA_REL_ "GenSigTimeoutTime" BU_SG_REL_ APSS SG_ 2015 GST_ALL_Byte4 0;
BA_REL_ "GenSigTimeoutTime" BU_SG_REL_ FPM SG_ 2015 GST_ALL_Byte4 0;
BA_REL_ "GenSigTimeoutTime" BU_SG_REL_ ATS SG_ 2015 GST_ALL_Byte4 0;
BA_REL_ "GenSigTimeoutTime" BU_SG_REL_ DSAU SG_ 2015 GST_ALL_Byte4 0;
BA_REL_ "GenSigTimeoutTime" BU_SG_REL_ ASAU SG_ 2015 GST_ALL_Byte4 0;
BA_ "NetworkRequest" SG_ 2015 GST_ALL_Byte4 0;
BA_ "NetworkRequestHoldingTime" SG_ 2015 GST_ALL_Byte4 5000;
BA_ "Version" SG_ 2015 GST_ALL_Byte4 "21.02.04";
BA_ "Description" SG_ 2015 GST_ALL_Byte5 "TP Index : 0";
BA_ "UsrSigPurpose" SG_ 2015 GST_ALL_Byte5 0;
BA_ "UserSigValidity" SG_ 2015 GST_ALL_Byte5 0;
BA_REL_ "GenSigTimeoutTime" BU_SG_REL_ RWPC SG_ 2015 GST_ALL_Byte5 0;
BA_REL_ "GenSigTimeoutTime" BU_SG_REL_ PSM SG_ 2015 GST_ALL_Byte5 0;
BA_REL_ "GenSigTimeoutTime" BU_SG_REL_ APSM SG_ 2015 GST_ALL_Byte5 0;
BA_REL_ "GenSigTimeoutTime" BU_SG_REL_ RLPSM SG_ 2015 GST_ALL_Byte5 0;
BA_REL_ "GenSigTimeoutTime" BU_SG_REL_ RRPSM SG_ 2015 GST_ALL_Byte5 0;
BA_REL_ "GenSigTimeoutTime" BU_SG_REL_ RLHV SG_ 2015 GST_ALL_Byte5 0;
BA_REL_ "GenSigTimeoutTime" BU_SG_REL_ RRHV SG_ 2015 GST_ALL_Byte5 0;
BA_REL_ "GenSigTimeoutTime" BU_SG_REL_ SHVU_RR SG_ 2015 GST_ALL_Byte5 0;
BA_REL_ "GenSigTimeoutTime" BU_SG_REL_ RDC SG_ 2015 GST_ALL_Byte5 0;
BA_REL_ "GenSigTimeoutTime" BU_SG_REL_ DPSS SG_ 2015 GST_ALL_Byte5 0;
BA_REL_ "GenSigTimeoutTime" BU_SG_REL_ AMP SG_ 2015 GST_ALL_Byte5 0;
BA_REL_ "GenSigTimeoutTime" BU_SG_REL_ vHS_M SG_ 2015 GST_ALL_Byte5 0;
BA_REL_ "GenSigTimeoutTime" BU_SG_REL_ APSS SG_ 2015 GST_ALL_Byte5 0;
BA_REL_ "GenSigTimeoutTime" BU_SG_REL_ FPM SG_ 2015 GST_ALL_Byte5 0;
BA_REL_ "GenSigTimeoutTime" BU_SG_REL_ ATS SG_ 2015 GST_ALL_Byte5 0;
BA_REL_ "GenSigTimeoutTime" BU_SG_REL_ DSAU SG_ 2015 GST_ALL_Byte5 0;
BA_REL_ "GenSigTimeoutTime" BU_SG_REL_ ASAU SG_ 2015 GST_ALL_Byte5 0;
BA_ "NetworkRequest" SG_ 2015 GST_ALL_Byte5 0;
BA_ "NetworkRequestHoldingTime" SG_ 2015 GST_ALL_Byte5 5000;
BA_ "Version" SG_ 2015 GST_ALL_Byte5 "21.02.04";
BA_ "Description" SG_ 2015 GST_ALL_Byte6 "TP Index : 0";
BA_ "UsrSigPurpose" SG_ 2015 GST_ALL_Byte6 0;
BA_ "UserSigValidity" SG_ 2015 GST_ALL_Byte6 0;
BA_REL_ "GenSigTimeoutTime" BU_SG_REL_ RWPC SG_ 2015 GST_ALL_Byte6 0;
BA_REL_ "GenSigTimeoutTime" BU_SG_REL_ PSM SG_ 2015 GST_ALL_Byte6 0;
BA_REL_ "GenSigTimeoutTime" BU_SG_REL_ APSM SG_ 2015 GST_ALL_Byte6 0;
BA_REL_ "GenSigTimeoutTime" BU_SG_REL_ RLPSM SG_ 2015 GST_ALL_Byte6 0;
BA_REL_ "GenSigTimeoutTime" BU_SG_REL_ RRPSM SG_ 2015 GST_ALL_Byte6 0;
BA_REL_ "GenSigTimeoutTime" BU_SG_REL_ RLHV SG_ 2015 GST_ALL_Byte6 0;
BA_REL_ "GenSigTimeoutTime" BU_SG_REL_ RRHV SG_ 2015 GST_ALL_Byte6 0;
BA_REL_ "GenSigTimeoutTime" BU_SG_REL_ SHVU_RR SG_ 2015 GST_ALL_Byte6 0;
BA_REL_ "GenSigTimeoutTime" BU_SG_REL_ RDC SG_ 2015 GST_ALL_Byte6 0;
BA_REL_ "GenSigTimeoutTime" BU_SG_REL_ DPSS SG_ 2015 GST_ALL_Byte6 0;
BA_REL_ "GenSigTimeoutTime" BU_SG_REL_ AMP SG_ 2015 GST_ALL_Byte6 0;
BA_REL_ "GenSigTimeoutTime" BU_SG_REL_ vHS_M SG_ 2015 GST_ALL_Byte6 0;
BA_REL_ "GenSigTimeoutTime" BU_SG_REL_ APSS SG_ 2015 GST_ALL_Byte6 0;
BA_REL_ "GenSigTimeoutTime" BU_SG_REL_ FPM SG_ 2015 GST_ALL_Byte6 0;
BA_REL_ "GenSigTimeoutTime" BU_SG_REL_ ATS SG_ 2015 GST_ALL_Byte6 0;
BA_REL_ "GenSigTimeoutTime" BU_SG_REL_ DSAU SG_ 2015 GST_ALL_Byte6 0;
BA_REL_ "GenSigTimeoutTime" BU_SG_REL_ ASAU SG_ 2015 GST_ALL_Byte6 0;
BA_ "NetworkRequest" SG_ 2015 GST_ALL_Byte6 0;
BA_ "NetworkRequestHoldingTime" SG_ 2015 GST_ALL_Byte6 5000;
BA_ "Version" SG_ 2015 GST_ALL_Byte6 "21.02.04";
BA_ "Description" SG_ 2015 GST_ALL_Byte7 "TP Index : 0";
BA_ "UsrSigPurpose" SG_ 2015 GST_ALL_Byte7 0;
BA_ "UserSigValidity" SG_ 2015 GST_ALL_Byte7 0;
BA_REL_ "GenSigTimeoutTime" BU_SG_REL_ RWPC SG_ 2015 GST_ALL_Byte7 0;
BA_REL_ "GenSigTimeoutTime" BU_SG_REL_ PSM SG_ 2015 GST_ALL_Byte7 0;
BA_REL_ "GenSigTimeoutTime" BU_SG_REL_ APSM SG_ 2015 GST_ALL_Byte7 0;
BA_REL_ "GenSigTimeoutTime" BU_SG_REL_ RLPSM SG_ 2015 GST_ALL_Byte7 0;
BA_REL_ "GenSigTimeoutTime" BU_SG_REL_ RRPSM SG_ 2015 GST_ALL_Byte7 0;
BA_REL_ "GenSigTimeoutTime" BU_SG_REL_ RLHV SG_ 2015 GST_ALL_Byte7 0;
BA_REL_ "GenSigTimeoutTime" BU_SG_REL_ RRHV SG_ 2015 GST_ALL_Byte7 0;
BA_REL_ "GenSigTimeoutTime" BU_SG_REL_ SHVU_RR SG_ 2015 GST_ALL_Byte7 0;
BA_REL_ "GenSigTimeoutTime" BU_SG_REL_ RDC SG_ 2015 GST_ALL_Byte7 0;
BA_REL_ "GenSigTimeoutTime" BU_SG_REL_ DPSS SG_ 2015 GST_ALL_Byte7 0;
BA_REL_ "GenSigTimeoutTime" BU_SG_REL_ AMP SG_ 2015 GST_ALL_Byte7 0;
BA_REL_ "GenSigTimeoutTime" BU_SG_REL_ vHS_M SG_ 2015 GST_ALL_Byte7 0;
BA_REL_ "GenSigTimeoutTime" BU_SG_REL_ APSS SG_ 2015 GST_ALL_Byte7 0;
BA_REL_ "GenSigTimeoutTime" BU_SG_REL_ FPM SG_ 2015 GST_ALL_Byte7 0;
BA_REL_ "GenSigTimeoutTime" BU_SG_REL_ ATS SG_ 2015 GST_ALL_Byte7 0;
BA_REL_ "GenSigTimeoutTime" BU_SG_REL_ DSAU SG_ 2015 GST_ALL_Byte7 0;
BA_REL_ "GenSigTimeoutTime" BU_SG_REL_ ASAU SG_ 2015 GST_ALL_Byte7 0;
BA_ "NetworkRequest" SG_ 2015 GST_ALL_Byte7 0;
BA_ "NetworkRequestHoldingTime" SG_ 2015 GST_ALL_Byte7 5000;
BA_ "Version" SG_ 2015 GST_ALL_Byte7 "21.02.04";
BA_ "Description" SG_ 2015 GST_ALL_Byte1 "TP Index : 0";
BA_ "UsrSigPurpose" SG_ 2015 GST_ALL_Byte1 0;
BA_ "UserSigValidity" SG_ 2015 GST_ALL_Byte1 0;
BA_REL_ "GenSigTimeoutTime" BU_SG_REL_ RWPC SG_ 2015 GST_ALL_Byte1 0;
BA_REL_ "GenSigTimeoutTime" BU_SG_REL_ PSM SG_ 2015 GST_ALL_Byte1 0;
BA_REL_ "GenSigTimeoutTime" BU_SG_REL_ APSM SG_ 2015 GST_ALL_Byte1 0;
BA_REL_ "GenSigTimeoutTime" BU_SG_REL_ RLPSM SG_ 2015 GST_ALL_Byte1 0;
BA_REL_ "GenSigTimeoutTime" BU_SG_REL_ RRPSM SG_ 2015 GST_ALL_Byte1 0;
BA_REL_ "GenSigTimeoutTime" BU_SG_REL_ RLHV SG_ 2015 GST_ALL_Byte1 0;
BA_REL_ "GenSigTimeoutTime" BU_SG_REL_ RRHV SG_ 2015 GST_ALL_Byte1 0;
BA_REL_ "GenSigTimeoutTime" BU_SG_REL_ SHVU_RR SG_ 2015 GST_ALL_Byte1 0;
BA_REL_ "GenSigTimeoutTime" BU_SG_REL_ RDC SG_ 2015 GST_ALL_Byte1 0;
BA_REL_ "GenSigTimeoutTime" BU_SG_REL_ DPSS SG_ 2015 GST_ALL_Byte1 0;
BA_REL_ "GenSigTimeoutTime" BU_SG_REL_ AMP SG_ 2015 GST_ALL_Byte1 0;
BA_REL_ "GenSigTimeoutTime" BU_SG_REL_ vHS_M SG_ 2015 GST_ALL_Byte1 0;
BA_REL_ "GenSigTimeoutTime" BU_SG_REL_ APSS SG_ 2015 GST_ALL_Byte1 0;
BA_REL_ "GenSigTimeoutTime" BU_SG_REL_ FPM SG_ 2015 GST_ALL_Byte1 0;
BA_REL_ "GenSigTimeoutTime" BU_SG_REL_ ATS SG_ 2015 GST_ALL_Byte1 0;
BA_REL_ "GenSigTimeoutTime" BU_SG_REL_ DSAU SG_ 2015 GST_ALL_Byte1 0;
BA_REL_ "GenSigTimeoutTime" BU_SG_REL_ ASAU SG_ 2015 GST_ALL_Byte1 0;
BA_ "NetworkRequest" SG_ 2015 GST_ALL_Byte1 0;
BA_ "NetworkRequestHoldingTime" SG_ 2015 GST_ALL_Byte1 5000;
BA_ "Version" SG_ 2015 GST_ALL_Byte1 "21.02.04";
BA_ "GenMsgCycleTime" BO_ 1510 0;
BA_ "GenMsgCycleTimeFast" BO_ 1510 0;
BA_ "GenMsgNrOfRepetition" BO_ 1510 0;
BA_ "DiagRequest" BO_ 1510 1;
BA_ "GenMsgILSupport" BO_ 1510 0;
BA_ "TpMessage" BO_ 1510 1;
BA_ "TpTxIndex" BO_ 1510 108;
BA_ "Description" SG_ 1510 GST_APSS_Byte0 "TP Index : 108";
BA_ "UsrSigPurpose" SG_ 1510 GST_APSS_Byte0 3;
BA_ "UserSigValidity" SG_ 1510 GST_APSS_Byte0 0;
BA_REL_ "GenSigTimeoutTime" BU_SG_REL_ vHS_M SG_ 1510 GST_APSS_Byte0 0;
BA_REL_ "GenSigTimeoutTime" BU_SG_REL_ APSS SG_ 1510 GST_APSS_Byte0 0;
BA_ "NetworkRequest" SG_ 1510 GST_APSS_Byte0 0;
BA_ "NetworkRequestHoldingTime" SG_ 1510 GST_APSS_Byte0 5000;
BA_ "Version" SG_ 1510 GST_APSS_Byte0 "21.02.04";
BA_ "Description" SG_ 1510 GST_APSS_Byte2 "TP Index : 108";
BA_ "UsrSigPurpose" SG_ 1510 GST_APSS_Byte2 3;
BA_ "UserSigValidity" SG_ 1510 GST_APSS_Byte2 0;
BA_REL_ "GenSigTimeoutTime" BU_SG_REL_ vHS_M SG_ 1510 GST_APSS_Byte2 0;
BA_REL_ "GenSigTimeoutTime" BU_SG_REL_ APSS SG_ 1510 GST_APSS_Byte2 0;
BA_ "NetworkRequest" SG_ 1510 GST_APSS_Byte2 0;
BA_ "NetworkRequestHoldingTime" SG_ 1510 GST_APSS_Byte2 5000;
BA_ "Version" SG_ 1510 GST_APSS_Byte2 "21.02.04";
BA_ "Description" SG_ 1510 GST_APSS_Byte3 "TP Index : 108";
BA_ "UsrSigPurpose" SG_ 1510 GST_APSS_Byte3 3;
BA_ "UserSigValidity" SG_ 1510 GST_APSS_Byte3 0;
BA_REL_ "GenSigTimeoutTime" BU_SG_REL_ vHS_M SG_ 1510 GST_APSS_Byte3 0;
BA_REL_ "GenSigTimeoutTime" BU_SG_REL_ APSS SG_ 1510 GST_APSS_Byte3 0;
BA_ "NetworkRequest" SG_ 1510 GST_APSS_Byte3 0;
BA_ "NetworkRequestHoldingTime" SG_ 1510 GST_APSS_Byte3 5000;
BA_ "Version" SG_ 1510 GST_APSS_Byte3 "21.02.04";
BA_ "Description" SG_ 1510 GST_APSS_Byte4 "TP Index : 108";
BA_ "UsrSigPurpose" SG_ 1510 GST_APSS_Byte4 3;
BA_ "UserSigValidity" SG_ 1510 GST_APSS_Byte4 0;
BA_REL_ "GenSigTimeoutTime" BU_SG_REL_ vHS_M SG_ 1510 GST_APSS_Byte4 0;
BA_REL_ "GenSigTimeoutTime" BU_SG_REL_ APSS SG_ 1510 GST_APSS_Byte4 0;
BA_ "NetworkRequest" SG_ 1510 GST_APSS_Byte4 0;
BA_ "NetworkRequestHoldingTime" SG_ 1510 GST_APSS_Byte4 5000;
BA_ "Version" SG_ 1510 GST_APSS_Byte4 "21.02.04";
BA_ "Description" SG_ 1510 GST_APSS_Byte5 "TP Index : 108";
BA_ "UsrSigPurpose" SG_ 1510 GST_APSS_Byte5 3;
BA_ "UserSigValidity" SG_ 1510 GST_APSS_Byte5 0;
BA_REL_ "GenSigTimeoutTime" BU_SG_REL_ vHS_M SG_ 1510 GST_APSS_Byte5 0;
BA_REL_ "GenSigTimeoutTime" BU_SG_REL_ APSS SG_ 1510 GST_APSS_Byte5 0;
BA_ "NetworkRequest" SG_ 1510 GST_APSS_Byte5 0;
BA_ "NetworkRequestHoldingTime" SG_ 1510 GST_APSS_Byte5 5000;
BA_ "Version" SG_ 1510 GST_APSS_Byte5 "21.02.04";
BA_ "Description" SG_ 1510 GST_APSS_Byte6 "TP Index : 108";
BA_ "UsrSigPurpose" SG_ 1510 GST_APSS_Byte6 3;
BA_ "UserSigValidity" SG_ 1510 GST_APSS_Byte6 0;
BA_REL_ "GenSigTimeoutTime" BU_SG_REL_ vHS_M SG_ 1510 GST_APSS_Byte6 0;
BA_REL_ "GenSigTimeoutTime" BU_SG_REL_ APSS SG_ 1510 GST_APSS_Byte6 0;
BA_ "NetworkRequest" SG_ 1510 GST_APSS_Byte6 0;
BA_ "NetworkRequestHoldingTime" SG_ 1510 GST_APSS_Byte6 5000;
BA_ "Version" SG_ 1510 GST_APSS_Byte6 "21.02.04";
BA_ "Description" SG_ 1510 GST_APSS_Byte7 "TP Index : 108";
BA_ "UsrSigPurpose" SG_ 1510 GST_APSS_Byte7 3;
BA_ "UserSigValidity" SG_ 1510 GST_APSS_Byte7 0;
BA_REL_ "GenSigTimeoutTime" BU_SG_REL_ vHS_M SG_ 1510 GST_APSS_Byte7 0;
BA_REL_ "GenSigTimeoutTime" BU_SG_REL_ APSS SG_ 1510 GST_APSS_Byte7 0;
BA_ "NetworkRequest" SG_ 1510 GST_APSS_Byte7 0;
BA_ "NetworkRequestHoldingTime" SG_ 1510 GST_APSS_Byte7 5000;
BA_ "Version" SG_ 1510 GST_APSS_Byte7 "21.02.04";
BA_ "Description" SG_ 1510 GST_APSS_Byte1 "TP Index : 108";
BA_ "UsrSigPurpose" SG_ 1510 GST_APSS_Byte1 3;
BA_ "UserSigValidity" SG_ 1510 GST_APSS_Byte1 0;
BA_REL_ "GenSigTimeoutTime" BU_SG_REL_ vHS_M SG_ 1510 GST_APSS_Byte1 0;
BA_REL_ "GenSigTimeoutTime" BU_SG_REL_ APSS SG_ 1510 GST_APSS_Byte1 0;
BA_ "NetworkRequest" SG_ 1510 GST_APSS_Byte1 0;
BA_ "NetworkRequestHoldingTime" SG_ 1510 GST_APSS_Byte1 5000;
BA_ "Version" SG_ 1510 GST_APSS_Byte1 "21.02.04";
BA_ "GenMsgCycleTime" BO_ 1954 0;
BA_ "GenMsgCycleTimeFast" BO_ 1954 0;
BA_ "GenMsgNrOfRepetition" BO_ 1954 0;
BA_ "DiagRequest" BO_ 1954 1;
BA_ "GenMsgILSupport" BO_ 1954 0;
BA_ "TpMessage" BO_ 1954 1;
BA_ "TpTxIndex" BO_ 1954 100;
BA_ "Description" SG_ 1954 GST_FPM1_Byte0 "TP Index : 100";
BA_ "UsrSigPurpose" SG_ 1954 GST_FPM1_Byte0 3;
BA_ "UserSigValidity" SG_ 1954 GST_FPM1_Byte0 0;
BA_REL_ "GenSigTimeoutTime" BU_SG_REL_ vHS_M SG_ 1954 GST_FPM1_Byte0 0;
BA_REL_ "GenSigTimeoutTime" BU_SG_REL_ FPM SG_ 1954 GST_FPM1_Byte0 0;
BA_ "NetworkRequest" SG_ 1954 GST_FPM1_Byte0 0;
BA_ "NetworkRequestHoldingTime" SG_ 1954 GST_FPM1_Byte0 5000;
BA_ "Version" SG_ 1954 GST_FPM1_Byte0 "21.02.04";
BA_ "Description" SG_ 1954 GST_FPM1_Byte2 "TP Index : 100";
BA_ "UsrSigPurpose" SG_ 1954 GST_FPM1_Byte2 3;
BA_ "UserSigValidity" SG_ 1954 GST_FPM1_Byte2 0;
BA_REL_ "GenSigTimeoutTime" BU_SG_REL_ vHS_M SG_ 1954 GST_FPM1_Byte2 0;
BA_REL_ "GenSigTimeoutTime" BU_SG_REL_ FPM SG_ 1954 GST_FPM1_Byte2 0;
BA_ "NetworkRequest" SG_ 1954 GST_FPM1_Byte2 0;
BA_ "NetworkRequestHoldingTime" SG_ 1954 GST_FPM1_Byte2 5000;
BA_ "Version" SG_ 1954 GST_FPM1_Byte2 "21.02.04";
BA_ "Description" SG_ 1954 GST_FPM1_Byte3 "TP Index : 100";
BA_ "UsrSigPurpose" SG_ 1954 GST_FPM1_Byte3 3;
BA_ "UserSigValidity" SG_ 1954 GST_FPM1_Byte3 0;
BA_REL_ "GenSigTimeoutTime" BU_SG_REL_ vHS_M SG_ 1954 GST_FPM1_Byte3 0;
BA_REL_ "GenSigTimeoutTime" BU_SG_REL_ FPM SG_ 1954 GST_FPM1_Byte3 0;
BA_ "NetworkRequest" SG_ 1954 GST_FPM1_Byte3 0;
BA_ "NetworkRequestHoldingTime" SG_ 1954 GST_FPM1_Byte3 5000;
BA_ "Version" SG_ 1954 GST_FPM1_Byte3 "21.02.04";
BA_ "Description" SG_ 1954 GST_FPM1_Byte4 "TP Index : 100";
BA_ "UsrSigPurpose" SG_ 1954 GST_FPM1_Byte4 3;
BA_ "UserSigValidity" SG_ 1954 GST_FPM1_Byte4 0;
BA_REL_ "GenSigTimeoutTime" BU_SG_REL_ vHS_M SG_ 1954 GST_FPM1_Byte4 0;
BA_REL_ "GenSigTimeoutTime" BU_SG_REL_ FPM SG_ 1954 GST_FPM1_Byte4 0;
BA_ "NetworkRequest" SG_ 1954 GST_FPM1_Byte4 0;
BA_ "NetworkRequestHoldingTime" SG_ 1954 GST_FPM1_Byte4 5000;
BA_ "Version" SG_ 1954 GST_FPM1_Byte4 "21.02.04";
BA_ "Description" SG_ 1954 GST_FPM1_Byte5 "TP Index : 100";
BA_ "UsrSigPurpose" SG_ 1954 GST_FPM1_Byte5 3;
BA_ "UserSigValidity" SG_ 1954 GST_FPM1_Byte5 0;
BA_REL_ "GenSigTimeoutTime" BU_SG_REL_ vHS_M SG_ 1954 GST_FPM1_Byte5 0;
BA_REL_ "GenSigTimeoutTime" BU_SG_REL_ FPM SG_ 1954 GST_FPM1_Byte5 0;
BA_ "NetworkRequest" SG_ 1954 GST_FPM1_Byte5 0;
BA_ "NetworkRequestHoldingTime" SG_ 1954 GST_FPM1_Byte5 5000;
BA_ "Version" SG_ 1954 GST_FPM1_Byte5 "21.02.04";
BA_ "Description" SG_ 1954 GST_FPM1_Byte6 "TP Index : 100";
BA_ "UsrSigPurpose" SG_ 1954 GST_FPM1_Byte6 3;
BA_ "UserSigValidity" SG_ 1954 GST_FPM1_Byte6 0;
BA_REL_ "GenSigTimeoutTime" BU_SG_REL_ vHS_M SG_ 1954 GST_FPM1_Byte6 0;
BA_REL_ "GenSigTimeoutTime" BU_SG_REL_ FPM SG_ 1954 GST_FPM1_Byte6 0;
BA_ "NetworkRequest" SG_ 1954 GST_FPM1_Byte6 0;
BA_ "NetworkRequestHoldingTime" SG_ 1954 GST_FPM1_Byte6 5000;
BA_ "Version" SG_ 1954 GST_FPM1_Byte6 "21.02.04";
BA_ "Description" SG_ 1954 GST_FPM1_Byte7 "TP Index : 100";
BA_ "UsrSigPurpose" SG_ 1954 GST_FPM1_Byte7 3;
BA_ "UserSigValidity" SG_ 1954 GST_FPM1_Byte7 0;
BA_REL_ "GenSigTimeoutTime" BU_SG_REL_ vHS_M SG_ 1954 GST_FPM1_Byte7 0;
BA_REL_ "GenSigTimeoutTime" BU_SG_REL_ FPM SG_ 1954 GST_FPM1_Byte7 0;
BA_ "NetworkRequest" SG_ 1954 GST_FPM1_Byte7 0;
BA_ "NetworkRequestHoldingTime" SG_ 1954 GST_FPM1_Byte7 5000;
BA_ "Version" SG_ 1954 GST_FPM1_Byte7 "21.02.04";
BA_ "Description" SG_ 1954 GST_FPM1_Byte1 "TP Index : 100";
BA_ "UsrSigPurpose" SG_ 1954 GST_FPM1_Byte1 3;
BA_ "UserSigValidity" SG_ 1954 GST_FPM1_Byte1 0;
BA_REL_ "GenSigTimeoutTime" BU_SG_REL_ vHS_M SG_ 1954 GST_FPM1_Byte1 0;
BA_REL_ "GenSigTimeoutTime" BU_SG_REL_ FPM SG_ 1954 GST_FPM1_Byte1 0;
BA_ "NetworkRequest" SG_ 1954 GST_FPM1_Byte1 0;
BA_ "NetworkRequestHoldingTime" SG_ 1954 GST_FPM1_Byte1 5000;
BA_ "Version" SG_ 1954 GST_FPM1_Byte1 "21.02.04";
BA_ "GenMsgCycleTime" BO_ 1973 0;
BA_ "GenMsgCycleTimeFast" BO_ 1973 0;
BA_ "GenMsgNrOfRepetition" BO_ 1973 0;
BA_ "DiagRequest" BO_ 1973 1;
BA_ "GenMsgILSupport" BO_ 1973 0;
BA_ "TpMessage" BO_ 1973 1;
BA_ "TpTxIndex" BO_ 1973 56;
BA_ "Description" SG_ 1973 GST_ICC_Byte0 "TP Index : 56";
BA_ "UsrSigPurpose" SG_ 1973 GST_ICC_Byte0 3;
BA_ "UserSigValidity" SG_ 1973 GST_ICC_Byte0 0;
BA_REL_ "GenSigTimeoutTime" BU_SG_REL_ vHS_M SG_ 1973 GST_ICC_Byte0 0;
BA_REL_ "GenSigTimeoutTime" BU_SG_REL_ ICC SG_ 1973 GST_ICC_Byte0 0;
BA_ "NetworkRequest" SG_ 1973 GST_ICC_Byte0 0;
BA_ "NetworkRequestHoldingTime" SG_ 1973 GST_ICC_Byte0 5000;
BA_ "Version" SG_ 1973 GST_ICC_Byte0 "21.03.02";
BA_ "Description" SG_ 1973 GST_ICC_Byte2 "TP Index : 56";
BA_ "UsrSigPurpose" SG_ 1973 GST_ICC_Byte2 3;
BA_ "UserSigValidity" SG_ 1973 GST_ICC_Byte2 0;
BA_REL_ "GenSigTimeoutTime" BU_SG_REL_ vHS_M SG_ 1973 GST_ICC_Byte2 0;
BA_REL_ "GenSigTimeoutTime" BU_SG_REL_ ICC SG_ 1973 GST_ICC_Byte2 0;
BA_ "NetworkRequest" SG_ 1973 GST_ICC_Byte2 0;
BA_ "NetworkRequestHoldingTime" SG_ 1973 GST_ICC_Byte2 5000;
BA_ "Version" SG_ 1973 GST_ICC_Byte2 "21.03.02";
BA_ "Description" SG_ 1973 GST_ICC_Byte3 "TP Index : 56";
BA_ "UsrSigPurpose" SG_ 1973 GST_ICC_Byte3 3;
BA_ "UserSigValidity" SG_ 1973 GST_ICC_Byte3 0;
BA_REL_ "GenSigTimeoutTime" BU_SG_REL_ vHS_M SG_ 1973 GST_ICC_Byte3 0;
BA_REL_ "GenSigTimeoutTime" BU_SG_REL_ ICC SG_ 1973 GST_ICC_Byte3 0;
BA_ "NetworkRequest" SG_ 1973 GST_ICC_Byte3 0;
BA_ "NetworkRequestHoldingTime" SG_ 1973 GST_ICC_Byte3 5000;
BA_ "Version" SG_ 1973 GST_ICC_Byte3 "21.03.02";
BA_ "Description" SG_ 1973 GST_ICC_Byte4 "TP Index : 56";
BA_ "UsrSigPurpose" SG_ 1973 GST_ICC_Byte4 3;
BA_ "UserSigValidity" SG_ 1973 GST_ICC_Byte4 0;
BA_REL_ "GenSigTimeoutTime" BU_SG_REL_ vHS_M SG_ 1973 GST_ICC_Byte4 0;
BA_REL_ "GenSigTimeoutTime" BU_SG_REL_ ICC SG_ 1973 GST_ICC_Byte4 0;
BA_ "NetworkRequest" SG_ 1973 GST_ICC_Byte4 0;
BA_ "NetworkRequestHoldingTime" SG_ 1973 GST_ICC_Byte4 5000;
BA_ "Version" SG_ 1973 GST_ICC_Byte4 "21.03.02";
BA_ "Description" SG_ 1973 GST_ICC_Byte5 "TP Index : 56";
BA_ "UsrSigPurpose" SG_ 1973 GST_ICC_Byte5 3;
BA_ "UserSigValidity" SG_ 1973 GST_ICC_Byte5 0;
BA_REL_ "GenSigTimeoutTime" BU_SG_REL_ vHS_M SG_ 1973 GST_ICC_Byte5 0;
BA_REL_ "GenSigTimeoutTime" BU_SG_REL_ ICC SG_ 1973 GST_ICC_Byte5 0;
BA_ "NetworkRequest" SG_ 1973 GST_ICC_Byte5 0;
BA_ "NetworkRequestHoldingTime" SG_ 1973 GST_ICC_Byte5 5000;
BA_ "Version" SG_ 1973 GST_ICC_Byte5 "21.03.02";
BA_ "Description" SG_ 1973 GST_ICC_Byte6 "TP Index : 56";
BA_ "UsrSigPurpose" SG_ 1973 GST_ICC_Byte6 3;
BA_ "UserSigValidity" SG_ 1973 GST_ICC_Byte6 0;
BA_REL_ "GenSigTimeoutTime" BU_SG_REL_ vHS_M SG_ 1973 GST_ICC_Byte6 0;
BA_REL_ "GenSigTimeoutTime" BU_SG_REL_ ICC SG_ 1973 GST_ICC_Byte6 0;
BA_ "NetworkRequest" SG_ 1973 GST_ICC_Byte6 0;
BA_ "NetworkRequestHoldingTime" SG_ 1973 GST_ICC_Byte6 5000;
BA_ "Version" SG_ 1973 GST_ICC_Byte6 "21.03.02";
BA_ "Description" SG_ 1973 GST_ICC_Byte7 "TP Index : 56";
BA_ "UsrSigPurpose" SG_ 1973 GST_ICC_Byte7 3;
BA_ "UserSigValidity" SG_ 1973 GST_ICC_Byte7 0;
BA_REL_ "GenSigTimeoutTime" BU_SG_REL_ vHS_M SG_ 1973 GST_ICC_Byte7 0;
BA_REL_ "GenSigTimeoutTime" BU_SG_REL_ ICC SG_ 1973 GST_ICC_Byte7 0;
BA_ "NetworkRequest" SG_ 1973 GST_ICC_Byte7 0;
BA_ "NetworkRequestHoldingTime" SG_ 1973 GST_ICC_Byte7 5000;
BA_ "Version" SG_ 1973 GST_ICC_Byte7 "21.03.02";
BA_ "Description" SG_ 1973 GST_ICC_Byte1 "TP Index : 56";
BA_ "UsrSigPurpose" SG_ 1973 GST_ICC_Byte1 3;
BA_ "UserSigValidity" SG_ 1973 GST_ICC_Byte1 0;
BA_REL_ "GenSigTimeoutTime" BU_SG_REL_ vHS_M SG_ 1973 GST_ICC_Byte1 0;
BA_REL_ "GenSigTimeoutTime" BU_SG_REL_ ICC SG_ 1973 GST_ICC_Byte1 0;
BA_ "NetworkRequest" SG_ 1973 GST_ICC_Byte1 0;
BA_ "NetworkRequestHoldingTime" SG_ 1973 GST_ICC_Byte1 5000;
BA_ "Version" SG_ 1973 GST_ICC_Byte1 "21.03.02";
BA_ "GenMsgCycleTime" BO_ 1955 0;
BA_ "GenMsgCycleTimeFast" BO_ 1955 0;
BA_ "GenMsgNrOfRepetition" BO_ 1955 0;
BA_ "DiagRequest" BO_ 1955 1;
BA_ "GenMsgILSupport" BO_ 1955 0;
BA_ "TpMessage" BO_ 1955 1;
BA_ "TpTxIndex" BO_ 1955 156;
BA_ "Description" SG_ 1955 GST_PSM_PSU_Byte0 "TP Index : 156";
BA_ "UsrSigPurpose" SG_ 1955 GST_PSM_PSU_Byte0 3;
BA_ "UserSigValidity" SG_ 1955 GST_PSM_PSU_Byte0 0;
BA_REL_ "GenSigTimeoutTime" BU_SG_REL_ PSM SG_ 1955 GST_PSM_PSU_Byte0 0;
BA_REL_ "GenSigTimeoutTime" BU_SG_REL_ vHS_M SG_ 1955 GST_PSM_PSU_Byte0 0;
BA_ "NetworkRequest" SG_ 1955 GST_PSM_PSU_Byte0 0;
BA_ "NetworkRequestHoldingTime" SG_ 1955 GST_PSM_PSU_Byte0 5000;
BA_ "Version" SG_ 1955 GST_PSM_PSU_Byte0 "21.02.04";
BA_ "Description" SG_ 1955 GST_PSM_PSU_Byte2 "TP Index : 156";
BA_ "UsrSigPurpose" SG_ 1955 GST_PSM_PSU_Byte2 3;
BA_ "UserSigValidity" SG_ 1955 GST_PSM_PSU_Byte2 0;
BA_REL_ "GenSigTimeoutTime" BU_SG_REL_ PSM SG_ 1955 GST_PSM_PSU_Byte2 0;
BA_REL_ "GenSigTimeoutTime" BU_SG_REL_ vHS_M SG_ 1955 GST_PSM_PSU_Byte2 0;
BA_ "NetworkRequest" SG_ 1955 GST_PSM_PSU_Byte2 0;
BA_ "NetworkRequestHoldingTime" SG_ 1955 GST_PSM_PSU_Byte2 5000;
BA_ "Version" SG_ 1955 GST_PSM_PSU_Byte2 "21.02.04";
BA_ "Description" SG_ 1955 GST_PSM_PSU_Byte3 "TP Index : 156";
BA_ "UsrSigPurpose" SG_ 1955 GST_PSM_PSU_Byte3 3;
BA_ "UserSigValidity" SG_ 1955 GST_PSM_PSU_Byte3 0;
BA_REL_ "GenSigTimeoutTime" BU_SG_REL_ PSM SG_ 1955 GST_PSM_PSU_Byte3 0;
BA_REL_ "GenSigTimeoutTime" BU_SG_REL_ vHS_M SG_ 1955 GST_PSM_PSU_Byte3 0;
BA_ "NetworkRequest" SG_ 1955 GST_PSM_PSU_Byte3 0;
BA_ "NetworkRequestHoldingTime" SG_ 1955 GST_PSM_PSU_Byte3 5000;
BA_ "Version" SG_ 1955 GST_PSM_PSU_Byte3 "21.02.04";
BA_ "Description" SG_ 1955 GST_PSM_PSU_Byte4 "TP Index : 156";
BA_ "UsrSigPurpose" SG_ 1955 GST_PSM_PSU_Byte4 3;
BA_ "UserSigValidity" SG_ 1955 GST_PSM_PSU_Byte4 0;
BA_REL_ "GenSigTimeoutTime" BU_SG_REL_ PSM SG_ 1955 GST_PSM_PSU_Byte4 0;
BA_REL_ "GenSigTimeoutTime" BU_SG_REL_ vHS_M SG_ 1955 GST_PSM_PSU_Byte4 0;
BA_ "NetworkRequest" SG_ 1955 GST_PSM_PSU_Byte4 0;
BA_ "NetworkRequestHoldingTime" SG_ 1955 GST_PSM_PSU_Byte4 5000;
BA_ "Version" SG_ 1955 GST_PSM_PSU_Byte4 "21.02.04";
BA_ "Description" SG_ 1955 GST_PSM_PSU_Byte5 "TP Index : 156";
BA_ "UsrSigPurpose" SG_ 1955 GST_PSM_PSU_Byte5 3;
BA_ "UserSigValidity" SG_ 1955 GST_PSM_PSU_Byte5 0;
BA_REL_ "GenSigTimeoutTime" BU_SG_REL_ PSM SG_ 1955 GST_PSM_PSU_Byte5 0;
BA_REL_ "GenSigTimeoutTime" BU_SG_REL_ vHS_M SG_ 1955 GST_PSM_PSU_Byte5 0;
BA_ "NetworkRequest" SG_ 1955 GST_PSM_PSU_Byte5 0;
BA_ "NetworkRequestHoldingTime" SG_ 1955 GST_PSM_PSU_Byte5 5000;
BA_ "Version" SG_ 1955 GST_PSM_PSU_Byte5 "21.02.04";
BA_ "Description" SG_ 1955 GST_PSM_PSU_Byte6 "TP Index : 156";
BA_ "UsrSigPurpose" SG_ 1955 GST_PSM_PSU_Byte6 3;
BA_ "UserSigValidity" SG_ 1955 GST_PSM_PSU_Byte6 0;
BA_REL_ "GenSigTimeoutTime" BU_SG_REL_ PSM SG_ 1955 GST_PSM_PSU_Byte6 0;
BA_REL_ "GenSigTimeoutTime" BU_SG_REL_ vHS_M SG_ 1955 GST_PSM_PSU_Byte6 0;
BA_ "NetworkRequest" SG_ 1955 GST_PSM_PSU_Byte6 0;
BA_ "NetworkRequestHoldingTime" SG_ 1955 GST_PSM_PSU_Byte6 5000;
BA_ "Version" SG_ 1955 GST_PSM_PSU_Byte6 "21.02.04";
BA_ "Description" SG_ 1955 GST_PSM_PSU_Byte7 "TP Index : 156";
BA_ "UsrSigPurpose" SG_ 1955 GST_PSM_PSU_Byte7 3;
BA_ "UserSigValidity" SG_ 1955 GST_PSM_PSU_Byte7 0;
BA_REL_ "GenSigTimeoutTime" BU_SG_REL_ PSM SG_ 1955 GST_PSM_PSU_Byte7 0;
BA_REL_ "GenSigTimeoutTime" BU_SG_REL_ vHS_M SG_ 1955 GST_PSM_PSU_Byte7 0;
BA_ "NetworkRequest" SG_ 1955 GST_PSM_PSU_Byte7 0;
BA_ "NetworkRequestHoldingTime" SG_ 1955 GST_PSM_PSU_Byte7 5000;
BA_ "Version" SG_ 1955 GST_PSM_PSU_Byte7 "21.02.04";
BA_ "Description" SG_ 1955 GST_PSM_PSU_Byte1 "TP Index : 156";
BA_ "UsrSigPurpose" SG_ 1955 GST_PSM_PSU_Byte1 3;
BA_ "UserSigValidity" SG_ 1955 GST_PSM_PSU_Byte1 0;
BA_REL_ "GenSigTimeoutTime" BU_SG_REL_ PSM SG_ 1955 GST_PSM_PSU_Byte1 0;
BA_REL_ "GenSigTimeoutTime" BU_SG_REL_ vHS_M SG_ 1955 GST_PSM_PSU_Byte1 0;
BA_ "NetworkRequest" SG_ 1955 GST_PSM_PSU_Byte1 0;
BA_ "NetworkRequestHoldingTime" SG_ 1955 GST_PSM_PSU_Byte1 5000;
BA_ "Version" SG_ 1955 GST_PSM_PSU_Byte1 "21.02.04";
BA_ "GenMsgCycleTime" BO_ 1507 0;
BA_ "GenMsgCycleTimeFast" BO_ 1507 0;
BA_ "GenMsgNrOfRepetition" BO_ 1507 0;
BA_ "DiagRequest" BO_ 1507 1;
BA_ "GenMsgILSupport" BO_ 1507 0;
BA_ "TpMessage" BO_ 1507 1;
BA_ "TpTxIndex" BO_ 1507 159;
BA_ "Description" SG_ 1507 GST_RDC_Byte0 "TP Index : 159";
BA_ "UsrSigPurpose" SG_ 1507 GST_RDC_Byte0 3;
BA_ "UserSigValidity" SG_ 1507 GST_RDC_Byte0 0;
BA_REL_ "GenSigTimeoutTime" BU_SG_REL_ RDC SG_ 1507 GST_RDC_Byte0 0;
BA_REL_ "GenSigTimeoutTime" BU_SG_REL_ vHS_M SG_ 1507 GST_RDC_Byte0 0;
BA_ "NetworkRequest" SG_ 1507 GST_RDC_Byte0 0;
BA_ "NetworkRequestHoldingTime" SG_ 1507 GST_RDC_Byte0 5000;
BA_ "Version" SG_ 1507 GST_RDC_Byte0 "21.02.04";
BA_ "Description" SG_ 1507 GST_RDC_Byte2 "TP Index : 159";
BA_ "UsrSigPurpose" SG_ 1507 GST_RDC_Byte2 3;
BA_ "UserSigValidity" SG_ 1507 GST_RDC_Byte2 0;
BA_REL_ "GenSigTimeoutTime" BU_SG_REL_ RDC SG_ 1507 GST_RDC_Byte2 0;
BA_REL_ "GenSigTimeoutTime" BU_SG_REL_ vHS_M SG_ 1507 GST_RDC_Byte2 0;
BA_ "NetworkRequest" SG_ 1507 GST_RDC_Byte2 0;
BA_ "NetworkRequestHoldingTime" SG_ 1507 GST_RDC_Byte2 5000;
BA_ "Version" SG_ 1507 GST_RDC_Byte2 "21.02.04";
BA_ "Description" SG_ 1507 GST_RDC_Byte3 "TP Index : 159";
BA_ "UsrSigPurpose" SG_ 1507 GST_RDC_Byte3 3;
BA_ "UserSigValidity" SG_ 1507 GST_RDC_Byte3 0;
BA_REL_ "GenSigTimeoutTime" BU_SG_REL_ RDC SG_ 1507 GST_RDC_Byte3 0;
BA_REL_ "GenSigTimeoutTime" BU_SG_REL_ vHS_M SG_ 1507 GST_RDC_Byte3 0;
BA_ "NetworkRequest" SG_ 1507 GST_RDC_Byte3 0;
BA_ "NetworkRequestHoldingTime" SG_ 1507 GST_RDC_Byte3 5000;
BA_ "Version" SG_ 1507 GST_RDC_Byte3 "21.02.04";
BA_ "Description" SG_ 1507 GST_RDC_Byte4 "TP Index : 159";
BA_ "UsrSigPurpose" SG_ 1507 GST_RDC_Byte4 3;
BA_ "UserSigValidity" SG_ 1507 GST_RDC_Byte4 0;
BA_REL_ "GenSigTimeoutTime" BU_SG_REL_ RDC SG_ 1507 GST_RDC_Byte4 0;
BA_REL_ "GenSigTimeoutTime" BU_SG_REL_ vHS_M SG_ 1507 GST_RDC_Byte4 0;
BA_ "NetworkRequest" SG_ 1507 GST_RDC_Byte4 0;
BA_ "NetworkRequestHoldingTime" SG_ 1507 GST_RDC_Byte4 5000;
BA_ "Version" SG_ 1507 GST_RDC_Byte4 "21.02.04";
BA_ "Description" SG_ 1507 GST_RDC_Byte5 "TP Index : 159";
BA_ "UsrSigPurpose" SG_ 1507 GST_RDC_Byte5 3;
BA_ "UserSigValidity" SG_ 1507 GST_RDC_Byte5 0;
BA_REL_ "GenSigTimeoutTime" BU_SG_REL_ RDC SG_ 1507 GST_RDC_Byte5 0;
BA_REL_ "GenSigTimeoutTime" BU_SG_REL_ vHS_M SG_ 1507 GST_RDC_Byte5 0;
BA_ "NetworkRequest" SG_ 1507 GST_RDC_Byte5 0;
BA_ "NetworkRequestHoldingTime" SG_ 1507 GST_RDC_Byte5 5000;
BA_ "Version" SG_ 1507 GST_RDC_Byte5 "21.02.04";
BA_ "Description" SG_ 1507 GST_RDC_Byte6 "TP Index : 159";
BA_ "UsrSigPurpose" SG_ 1507 GST_RDC_Byte6 3;
BA_ "UserSigValidity" SG_ 1507 GST_RDC_Byte6 0;
BA_REL_ "GenSigTimeoutTime" BU_SG_REL_ RDC SG_ 1507 GST_RDC_Byte6 0;
BA_REL_ "GenSigTimeoutTime" BU_SG_REL_ vHS_M SG_ 1507 GST_RDC_Byte6 0;
BA_ "NetworkRequest" SG_ 1507 GST_RDC_Byte6 0;
BA_ "NetworkRequestHoldingTime" SG_ 1507 GST_RDC_Byte6 5000;
BA_ "Version" SG_ 1507 GST_RDC_Byte6 "21.02.04";
BA_ "Description" SG_ 1507 GST_RDC_Byte7 "TP Index : 159";
BA_ "UsrSigPurpose" SG_ 1507 GST_RDC_Byte7 3;
BA_ "UserSigValidity" SG_ 1507 GST_RDC_Byte7 0;
BA_REL_ "GenSigTimeoutTime" BU_SG_REL_ RDC SG_ 1507 GST_RDC_Byte7 0;
BA_REL_ "GenSigTimeoutTime" BU_SG_REL_ vHS_M SG_ 1507 GST_RDC_Byte7 0;
BA_ "NetworkRequest" SG_ 1507 GST_RDC_Byte7 0;
BA_ "NetworkRequestHoldingTime" SG_ 1507 GST_RDC_Byte7 5000;
BA_ "Version" SG_ 1507 GST_RDC_Byte7 "21.02.04";
BA_ "Description" SG_ 1507 GST_RDC_Byte1 "TP Index : 159";
BA_ "UsrSigPurpose" SG_ 1507 GST_RDC_Byte1 3;
BA_ "UserSigValidity" SG_ 1507 GST_RDC_Byte1 0;
BA_REL_ "GenSigTimeoutTime" BU_SG_REL_ RDC SG_ 1507 GST_RDC_Byte1 0;
BA_REL_ "GenSigTimeoutTime" BU_SG_REL_ vHS_M SG_ 1507 GST_RDC_Byte1 0;
BA_ "NetworkRequest" SG_ 1507 GST_RDC_Byte1 0;
BA_ "NetworkRequestHoldingTime" SG_ 1507 GST_RDC_Byte1 5000;
BA_ "Version" SG_ 1507 GST_RDC_Byte1 "21.02.04";
BA_ "GenMsgCycleTime" BO_ 2563126785 0;
BA_ "VFrameFormat" BO_ 2563126785 1;
BA_ "GenSigSendType" SG_ 2563126785 AMP_HFVolumeStep 4;
BA_ "GenSigStartValue" SG_ 2563126785 AMP_HFVolumeStep 255;
BA_ "UserSigValidity" SG_ 2563126785 AMP_HFVolumeStep 1;
BA_REL_ "GenSigTimeoutTime" BU_SG_REL_ AMP SG_ 2563126785 AMP_HFVolumeStep 0;
BA_ "NetworkRequest" SG_ 2563126785 AMP_HFVolumeStep 0;
BA_ "Version" SG_ 2563126785 AMP_HFVolumeStep "18.12.06";
BA_ "Description" SG_ 2563126785 DVRS_BeepVolumeStep "Command for DVRS Touch Beep Sound Volume Setting 

-range : 0 ~ max

-max : value of AMP_MaxBeep1VolumeState

This Signal's Feedback is DVRS_BeepVolumeState@AMP";
BA_ "GenSigSendType" SG_ 2563126785 DVRS_BeepVolumeStep 4;
BA_ "GenSigStartValue" SG_ 2563126785 DVRS_BeepVolumeStep 255;
BA_ "UserSigValidity" SG_ 2563126785 DVRS_BeepVolumeStep 1;
BA_REL_ "GenSigTimeoutTime" BU_SG_REL_ AMP SG_ 2563126785 DVRS_BeepVolumeStep 0;
BA_ "Version" SG_ 2563126785 DVRS_BeepVolumeStep "20.03.03";
BA_ "Description" SG_ 2563126785 DVRS_BeepFrequency "Command for Touch Beep Sound Frequency Setting of DVRS

-range : 20Hz ~ 20000Hz";
BA_ "GenSigSendType" SG_ 2563126785 DVRS_BeepFrequency 4;
BA_ "GenSigStartValue" SG_ 2563126785 DVRS_BeepFrequency 65535;
BA_ "UserSigValidity" SG_ 2563126785 DVRS_BeepFrequency 1;
BA_REL_ "GenSigTimeoutTime" BU_SG_REL_ AMP SG_ 2563126785 DVRS_BeepFrequency 0;
BA_ "Version" SG_ 2563126785 DVRS_BeepFrequency "20.03.03";
BA_ "Description" SG_ 2563126785 AMP_SiriVolumeStep "Command for Siri Mode Volume Setting";
BA_ "GenSigSendType" SG_ 2563126785 AMP_SiriVolumeStep 4;
BA_ "GenSigStartValue" SG_ 2563126785 AMP_SiriVolumeStep 255;
BA_ "UserSigValidity" SG_ 2563126785 AMP_SiriVolumeStep 1;
BA_REL_ "GenSigTimeoutTime" BU_SG_REL_ AMP SG_ 2563126785 AMP_SiriVolumeStep 0;
BA_ "Version" SG_ 2563126785 AMP_SiriVolumeStep "20.04.02";
BA_ "Description" SG_ 2563126785 DVRS_Beep_OutputCh_Select "Command for Set DVRS Beep Output Channel to identify which Speakers will output Sound

- per bit, 0 means 'Not Output Channel' and 1 means 'Output Channel'

bit0 : FL / bit1 : FR / bit2 : RL / bit3 : RR / bit4 : CTR / bit5 : Surround L /

bit6 : Surround R / bit7 : SWF / bit8 : Headrest L / bit9 : Headrest R / bit10 : Loof L /

bit11 : Loof CTR / bit12 : Loof R / bit13~bit15 : Reserved

- This Signal's Feedback is DVRS_Beep_OutputCh_State@AMP";
BA_ "GenSigSendType" SG_ 2563126785 DVRS_Beep_OutputCh_Select 4;
BA_ "GenSigStartValue" SG_ 2563126785 DVRS_Beep_OutputCh_Select 65535;
BA_ "UserSigValidity" SG_ 2563126785 DVRS_Beep_OutputCh_Select 1;
BA_REL_ "GenSigTimeoutTime" BU_SG_REL_ AMP SG_ 2563126785 DVRS_Beep_OutputCh_Select 0;
BA_ "Version" SG_ 2563126785 DVRS_Beep_OutputCh_Select "20.03.03";
BA_ "GenMsgCycleTime" BO_ 2323817729 0;
BA_ "VFrameFormat" BO_ 2323817729 1;
BA_ "Description" SG_ 2323817729 C_RLBackSoftNValueSet_EC "2nd Left Seat Back Softness";
BA_ "GenSigSendType" SG_ 2323817729 C_RLBackSoftNValueSet_EC 4;
BA_ "UserSigValidity" SG_ 2323817729 C_RLBackSoftNValueSet_EC 0;
BA_REL_ "GenSigTimeoutTime" BU_SG_REL_ RLPSM SG_ 2323817729 C_RLBackSoftNValueSet_EC 0;
BA_REL_ "GenSigTimeoutTime" BU_SG_REL_ ATS SG_ 2323817729 C_RLBackSoftNValueSet_EC 0;
BA_ "Version" SG_ 2323817729 C_RLBackSoftNValueSet_EC "20.02.03";
BA_ "Description" SG_ 2323817729 C_RRAirSptStrNValueSet_EC "2nd Right side seat Smart Air Support Strength";
BA_ "GenSigSendType" SG_ 2323817729 C_RRAirSptStrNValueSet_EC 4;
BA_ "UserSigValidity" SG_ 2323817729 C_RRAirSptStrNValueSet_EC 0;
BA_REL_ "GenSigTimeoutTime" BU_SG_REL_ RLPSM SG_ 2323817729 C_RRAirSptStrNValueSet_EC 0;
BA_REL_ "GenSigTimeoutTime" BU_SG_REL_ ATS SG_ 2323817729 C_RRAirSptStrNValueSet_EC 0;
BA_ "Version" SG_ 2323817729 C_RRAirSptStrNValueSet_EC "20.02.03";
BA_ "Description" SG_ 2323817729 C_RRAirSptTimeNValueSet_EC "2nd Right side seat Smart Air Support Time";
BA_ "GenSigSendType" SG_ 2323817729 C_RRAirSptTimeNValueSet_EC 4;
BA_ "UserSigValidity" SG_ 2323817729 C_RRAirSptTimeNValueSet_EC 0;
BA_REL_ "GenSigTimeoutTime" BU_SG_REL_ RLPSM SG_ 2323817729 C_RRAirSptTimeNValueSet_EC 0;
BA_REL_ "GenSigTimeoutTime" BU_SG_REL_ ATS SG_ 2323817729 C_RRAirSptTimeNValueSet_EC 0;
BA_ "Version" SG_ 2323817729 C_RRAirSptTimeNValueSet_EC "20.02.03";
BA_ "Description" SG_ 2323817729 C_RRBackSoftNValueSet_EC "2nd Right side seat Back Softness";
BA_ "GenSigSendType" SG_ 2323817729 C_RRBackSoftNValueSet_EC 4;
BA_ "UserSigValidity" SG_ 2323817729 C_RRBackSoftNValueSet_EC 0;
BA_REL_ "GenSigTimeoutTime" BU_SG_REL_ RLPSM SG_ 2323817729 C_RRBackSoftNValueSet_EC 0;
BA_REL_ "GenSigTimeoutTime" BU_SG_REL_ ATS SG_ 2323817729 C_RRBackSoftNValueSet_EC 0;
BA_ "Version" SG_ 2323817729 C_RRBackSoftNValueSet_EC "20.02.03";
BA_ "Description" SG_ 2323817729 C_RROneTchNvalueSet_EC "2nd Right side seat One Touch Mode";
BA_ "GenSigSendType" SG_ 2323817729 C_RROneTchNvalueSet_EC 4;
BA_ "UserSigValidity" SG_ 2323817729 C_RROneTchNvalueSet_EC 0;
BA_REL_ "GenSigTimeoutTime" BU_SG_REL_ RLPSM SG_ 2323817729 C_RROneTchNvalueSet_EC 0;
BA_REL_ "GenSigTimeoutTime" BU_SG_REL_ RRPSM SG_ 2323817729 C_RROneTchNvalueSet_EC 0;
BA_ "Version" SG_ 2323817729 C_RROneTchNvalueSet_EC "20.02.03";
BA_ "Description" SG_ 2323817729 C_RLOneTchNValueSet_EC "2nd Left side seat One Touch Mode";
BA_ "GenSigSendType" SG_ 2323817729 C_RLOneTchNValueSet_EC 4;
BA_ "UserSigValidity" SG_ 2323817729 C_RLOneTchNValueSet_EC 0;
BA_REL_ "GenSigTimeoutTime" BU_SG_REL_ RLPSM SG_ 2323817729 C_RLOneTchNValueSet_EC 0;
BA_REL_ "GenSigTimeoutTime" BU_SG_REL_ RRPSM SG_ 2323817729 C_RLOneTchNValueSet_EC 0;
BA_ "Version" SG_ 2323817729 C_RLOneTchNValueSet_EC "20.02.03";
BA_ "Description" SG_ 2323817729 C_RRAirSptModeNValueSet_EC "2nd Right side seat Moving control : Smart Air Support Mode";
BA_ "GenSigSendType" SG_ 2323817729 C_RRAirSptModeNValueSet_EC 4;
BA_ "UserSigValidity" SG_ 2323817729 C_RRAirSptModeNValueSet_EC 0;
BA_REL_ "GenSigTimeoutTime" BU_SG_REL_ RLPSM SG_ 2323817729 C_RRAirSptModeNValueSet_EC 0;
BA_REL_ "GenSigTimeoutTime" BU_SG_REL_ ATS SG_ 2323817729 C_RRAirSptModeNValueSet_EC 0;
BA_ "Version" SG_ 2323817729 C_RRAirSptModeNValueSet_EC "20.02.03";
BA_ "GenMsgSendType" BO_ 2449770241 0;
BA_ "GenMsgStartDelayTime" BO_ 2449770241 90;
BA_ "VFrameFormat" BO_ 2449770241 1;
BA_ "GenSigSendType" SG_ 2449770241 C_AstRclBwdSw_HU 4;
BA_ "UserSigValidity" SG_ 2449770241 C_AstRclBwdSw_HU 0;
BA_REL_ "GenSigTimeoutTime" BU_SG_REL_ APSM SG_ 2449770241 C_AstRclBwdSw_HU 1500;
BA_REL_ "GenSigTimeoutTime" BU_SG_REL_ RRPSM SG_ 2449770241 C_AstRclBwdSw_HU 1500;
BA_REL_ "GenSigTimeoutTime" BU_SG_REL_ APSS SG_ 2449770241 C_AstRclBwdSw_HU 1500;
BA_ "Version" SG_ 2449770241 C_AstRclBwdSw_HU "19.11.05";
BA_ "GenSigSendType" SG_ 2449770241 C_AstHeightUpSw_HU 4;
BA_ "UserSigValidity" SG_ 2449770241 C_AstHeightUpSw_HU 0;
BA_REL_ "GenSigTimeoutTime" BU_SG_REL_ APSM SG_ 2449770241 C_AstHeightUpSw_HU 1500;
BA_REL_ "GenSigTimeoutTime" BU_SG_REL_ RRPSM SG_ 2449770241 C_AstHeightUpSw_HU 1500;
BA_REL_ "GenSigTimeoutTime" BU_SG_REL_ APSS SG_ 2449770241 C_AstHeightUpSw_HU 1500;
BA_ "Version" SG_ 2449770241 C_AstHeightUpSw_HU "19.11.05";
BA_ "GenSigSendType" SG_ 2449770241 C_AstTiltDnSw_HU 4;
BA_ "UserSigValidity" SG_ 2449770241 C_AstTiltDnSw_HU 0;
BA_REL_ "GenSigTimeoutTime" BU_SG_REL_ APSM SG_ 2449770241 C_AstTiltDnSw_HU 1500;
BA_REL_ "GenSigTimeoutTime" BU_SG_REL_ APSS SG_ 2449770241 C_AstTiltDnSw_HU 1500;
BA_ "Version" SG_ 2449770241 C_AstTiltDnSw_HU "19.11.05";
BA_ "GenSigSendType" SG_ 2449770241 C_AstTiltUpSw_HU 4;
BA_ "UserSigValidity" SG_ 2449770241 C_AstTiltUpSw_HU 0;
BA_REL_ "GenSigTimeoutTime" BU_SG_REL_ APSM SG_ 2449770241 C_AstTiltUpSw_HU 1500;
BA_REL_ "GenSigTimeoutTime" BU_SG_REL_ APSS SG_ 2449770241 C_AstTiltUpSw_HU 1500;
BA_ "Version" SG_ 2449770241 C_AstTiltUpSw_HU "19.11.05";
BA_ "GenSigSendType" SG_ 2449770241 C_AstLumbarDefSw_HU 4;
BA_ "UserSigValidity" SG_ 2449770241 C_AstLumbarDefSw_HU 0;
BA_REL_ "GenSigTimeoutTime" BU_SG_REL_ APSS SG_ 2449770241 C_AstLumbarDefSw_HU 1500;
BA_REL_ "GenSigTimeoutTime" BU_SG_REL_ ASAU SG_ 2449770241 C_AstLumbarDefSw_HU 1500;
BA_ "Version" SG_ 2449770241 C_AstLumbarDefSw_HU "19.11.05";
BA_ "GenSigSendType" SG_ 2449770241 C_AstLumbarLowSw_HU 4;
BA_ "UserSigValidity" SG_ 2449770241 C_AstLumbarLowSw_HU 0;
BA_REL_ "GenSigTimeoutTime" BU_SG_REL_ APSS SG_ 2449770241 C_AstLumbarLowSw_HU 1500;
BA_REL_ "GenSigTimeoutTime" BU_SG_REL_ ASAU SG_ 2449770241 C_AstLumbarLowSw_HU 1500;
BA_ "Version" SG_ 2449770241 C_AstLumbarLowSw_HU "19.11.05";
BA_ "GenSigSendType" SG_ 2449770241 C_AstRclFwdSw_HU 4;
BA_ "UserSigValidity" SG_ 2449770241 C_AstRclFwdSw_HU 0;
BA_REL_ "GenSigTimeoutTime" BU_SG_REL_ APSM SG_ 2449770241 C_AstRclFwdSw_HU 1500;
BA_REL_ "GenSigTimeoutTime" BU_SG_REL_ RRPSM SG_ 2449770241 C_AstRclFwdSw_HU 1500;
BA_REL_ "GenSigTimeoutTime" BU_SG_REL_ APSS SG_ 2449770241 C_AstRclFwdSw_HU 1500;
BA_ "Version" SG_ 2449770241 C_AstRclFwdSw_HU "19.11.05";
BA_ "GenSigSendType" SG_ 2449770241 C_AstLumbarMidSw_HU 4;
BA_ "UserSigValidity" SG_ 2449770241 C_AstLumbarMidSw_HU 0;
BA_REL_ "GenSigTimeoutTime" BU_SG_REL_ APSS SG_ 2449770241 C_AstLumbarMidSw_HU 1500;
BA_REL_ "GenSigTimeoutTime" BU_SG_REL_ ASAU SG_ 2449770241 C_AstLumbarMidSw_HU 1500;
BA_ "Version" SG_ 2449770241 C_AstLumbarMidSw_HU "19.11.05";
BA_ "GenSigSendType" SG_ 2449770241 C_AstLumbarUpSw_HU 4;
BA_ "UserSigValidity" SG_ 2449770241 C_AstLumbarUpSw_HU 0;
BA_REL_ "GenSigTimeoutTime" BU_SG_REL_ APSS SG_ 2449770241 C_AstLumbarUpSw_HU 1500;
BA_REL_ "GenSigTimeoutTime" BU_SG_REL_ ASAU SG_ 2449770241 C_AstLumbarUpSw_HU 1500;
BA_ "Version" SG_ 2449770241 C_AstLumbarUpSw_HU "19.11.05";
BA_ "GenSigSendType" SG_ 2449770241 C_RRSlideFwdSw_HU 4;
BA_ "UserSigValidity" SG_ 2449770241 C_RRSlideFwdSw_HU 0;
BA_REL_ "GenSigTimeoutTime" BU_SG_REL_ RRPSM SG_ 2449770241 C_RRSlideFwdSw_HU 1500;
BA_ "Version" SG_ 2449770241 C_RRSlideFwdSw_HU "19.11.05";
BA_ "GenSigSendType" SG_ 2449770241 C_RRSlideBwdSw_HU 4;
BA_ "UserSigValidity" SG_ 2449770241 C_RRSlideBwdSw_HU 0;
BA_REL_ "GenSigTimeoutTime" BU_SG_REL_ RRPSM SG_ 2449770241 C_RRSlideBwdSw_HU 1500;
BA_ "Version" SG_ 2449770241 C_RRSlideBwdSw_HU "19.11.05";
BA_ "GenSigSendType" SG_ 2449770241 C_RLSlideFwdSw_HU 4;
BA_ "UserSigValidity" SG_ 2449770241 C_RLSlideFwdSw_HU 0;
BA_REL_ "GenSigTimeoutTime" BU_SG_REL_ RLPSM SG_ 2449770241 C_RLSlideFwdSw_HU 1500;
BA_ "Version" SG_ 2449770241 C_RLSlideFwdSw_HU "19.11.05";
BA_ "GenSigSendType" SG_ 2449770241 C_RLSlideBwdSw_HU 4;
BA_ "UserSigValidity" SG_ 2449770241 C_RLSlideBwdSw_HU 0;
BA_REL_ "GenSigTimeoutTime" BU_SG_REL_ RLPSM SG_ 2449770241 C_RLSlideBwdSw_HU 1500;
BA_ "Version" SG_ 2449770241 C_RLSlideBwdSw_HU "19.11.05";
BA_ "GenSigSendType" SG_ 2449770241 C_AstSlideBwdSw_HU 4;
BA_ "UserSigValidity" SG_ 2449770241 C_AstSlideBwdSw_HU 0;
BA_REL_ "GenSigTimeoutTime" BU_SG_REL_ APSM SG_ 2449770241 C_AstSlideBwdSw_HU 1500;
BA_REL_ "GenSigTimeoutTime" BU_SG_REL_ RRPSM SG_ 2449770241 C_AstSlideBwdSw_HU 1500;
BA_REL_ "GenSigTimeoutTime" BU_SG_REL_ APSS SG_ 2449770241 C_AstSlideBwdSw_HU 1500;
BA_ "Version" SG_ 2449770241 C_AstSlideBwdSw_HU "19.11.05";
BA_ "Description" SG_ 2449770241 C_AstRlxNValueSet "Assistant seat Moving control : Relaxtion mode";
BA_ "GenSigSendType" SG_ 2449770241 C_AstRlxNValueSet 4;
BA_ "UserSigValidity" SG_ 2449770241 C_AstRlxNValueSet 0;
BA_REL_ "GenSigTimeoutTime" BU_SG_REL_ APSM SG_ 2449770241 C_AstRlxNValueSet 1500;
BA_REL_ "GenSigTimeoutTime" BU_SG_REL_ APSS SG_ 2449770241 C_AstRlxNValueSet 1500;
BA_ "Version" SG_ 2449770241 C_AstRlxNValueSet "19.11.05";
BA_ "GenSigSendType" SG_ 2449770241 C_AstSlideFwdSw_HU 4;
BA_ "UserSigValidity" SG_ 2449770241 C_AstSlideFwdSw_HU 0;
BA_REL_ "GenSigTimeoutTime" BU_SG_REL_ APSM SG_ 2449770241 C_AstSlideFwdSw_HU 1500;
BA_REL_ "GenSigTimeoutTime" BU_SG_REL_ RRPSM SG_ 2449770241 C_AstSlideFwdSw_HU 1500;
BA_REL_ "GenSigTimeoutTime" BU_SG_REL_ APSS SG_ 2449770241 C_AstSlideFwdSw_HU 1500;
BA_ "Version" SG_ 2449770241 C_AstSlideFwdSw_HU "19.11.05";
BA_ "GenSigSendType" SG_ 2449770241 C_AstHeightDnSw_HU 4;
BA_ "UserSigValidity" SG_ 2449770241 C_AstHeightDnSw_HU 0;
BA_REL_ "GenSigTimeoutTime" BU_SG_REL_ APSM SG_ 2449770241 C_AstHeightDnSw_HU 1500;
BA_REL_ "GenSigTimeoutTime" BU_SG_REL_ RRPSM SG_ 2449770241 C_AstHeightDnSw_HU 1500;
BA_REL_ "GenSigTimeoutTime" BU_SG_REL_ APSS SG_ 2449770241 C_AstHeightDnSw_HU 1500;
BA_ "Version" SG_ 2449770241 C_AstHeightDnSw_HU "19.11.05";
BA_ "GenMsgSendType" BO_ 2479157505 0;
BA_ "GenMsgCycleTime" BO_ 2479157505 1000;
BA_ "VFrameFormat" BO_ 2479157505 1;
BA_ "GenSigSendType" SG_ 2479157505 HU_TeleVehicleStatusReq 4;
BA_ "GenSigStartValue" SG_ 2479157505 HU_TeleVehicleStatusReq 3;
BA_ "UserSigValidity" SG_ 2479157505 HU_TeleVehicleStatusReq 0;
BA_ "Version" SG_ 2479157505 HU_TeleVehicleStatusReq "18.09.04";
BA_ "Description" SG_ 2479157505 HU_Background "HU Backgound image info";
BA_ "GenSigSendType" SG_ 2479157505 HU_Background 4;
BA_ "GenSigStartValue" SG_ 2479157505 HU_Background 7;
BA_ "UserSigValidity" SG_ 2479157505 HU_Background 1;
BA_REL_ "GenSigTimeoutTime" BU_SG_REL_ ATS SG_ 2479157505 HU_Background 5000;
BA_ "Version" SG_ 2479157505 HU_Background "21.01.06";
BA_ "Description" SG_ 2479157505 ccIC_HUD_PbackSta "Status signal for HUD interoperation with IMS

(The number of memory is expanded.)";
BA_ "GenSigSendType" SG_ 2479157505 ccIC_HUD_PbackSta 4;
BA_ "UserSigValidity" SG_ 2479157505 ccIC_HUD_PbackSta 3;
BA_REL_ "GenSigTimeoutTime" BU_SG_REL_ PSM SG_ 2479157505 ccIC_HUD_PbackSta 5000;
BA_ "Version" SG_ 2479157505 ccIC_HUD_PbackSta "19.12.00";
BA_ "Description" SG_ 2479157505 HU_BackgroundFadeInOut "HU Background Fade in/out info

(HEX * Factor) %";
BA_ "GenSigSendType" SG_ 2479157505 HU_BackgroundFadeInOut 4;
BA_ "GenSigStartValue" SG_ 2479157505 HU_BackgroundFadeInOut 1023;
BA_ "UserSigValidity" SG_ 2479157505 HU_BackgroundFadeInOut 1;
BA_REL_ "GenSigTimeoutTime" BU_SG_REL_ ATS SG_ 2479157505 HU_BackgroundFadeInOut 5000;
BA_ "Version" SG_ 2479157505 HU_BackgroundFadeInOut "21.01.06";
BA_ "Description" SG_ 2479157505 HU_Background_Time_Info "The signal indicates current HU background time information. (sunrise, sunset)";
BA_ "GenSigSendType" SG_ 2479157505 HU_Background_Time_Info 4;
BA_ "UserSigValidity" SG_ 2479157505 HU_Background_Time_Info 0;
BA_ "Version" SG_ 2479157505 HU_Background_Time_Info "21.01.01";
BA_ "GenMsgCycleTime" BO_ 2462366209 0;
BA_ "VFrameFormat" BO_ 2462366209 1;
BA_ "GenSigSendType" SG_ 2462366209 PROSHORT_V2_3_Offset 4;
BA_ "UserSigValidity" SG_ 2462366209 PROSHORT_V2_3_Offset 3;
BA_REL_ "GenSigTimeoutTime" BU_SG_REL_ DSAU SG_ 2462366209 PROSHORT_V2_3_Offset 0;
BA_ "Version" SG_ 2462366209 PROSHORT_V2_3_Offset "20.03.06";
BA_ "GenSigSendType" SG_ 2462366209 PROSHORT_V2_3_PathIndex 4;
BA_ "UserSigValidity" SG_ 2462366209 PROSHORT_V2_3_PathIndex 3;
BA_ "Version" SG_ 2462366209 PROSHORT_V2_3_PathIndex "20.03.06";
BA_ "GenSigSendType" SG_ 2462366209 PROSHORT_V2_3_Distance 4;
BA_ "UserSigValidity" SG_ 2462366209 PROSHORT_V2_3_Distance 3;
BA_REL_ "GenSigTimeoutTime" BU_SG_REL_ DSAU SG_ 2462366209 PROSHORT_V2_3_Distance 0;
BA_ "Version" SG_ 2462366209 PROSHORT_V2_3_Distance "20.03.06";
BA_ "GenSigSendType" SG_ 2462366209 PROSHORT_V2_3_Value0 4;
BA_ "UserSigValidity" SG_ 2462366209 PROSHORT_V2_3_Value0 3;
BA_REL_ "GenSigTimeoutTime" BU_SG_REL_ DSAU SG_ 2462366209 PROSHORT_V2_3_Value0 0;
BA_ "Version" SG_ 2462366209 PROSHORT_V2_3_Value0 "20.03.06";
BA_ "GenSigSendType" SG_ 2462366209 PROSHORT_V2_3_Value1 4;
BA_ "UserSigValidity" SG_ 2462366209 PROSHORT_V2_3_Value1 3;
BA_REL_ "GenSigTimeoutTime" BU_SG_REL_ DSAU SG_ 2462366209 PROSHORT_V2_3_Value1 0;
BA_ "Version" SG_ 2462366209 PROSHORT_V2_3_Value1 "20.03.06";
BA_ "GenSigSendType" SG_ 2462366209 PROSHORT_V2_3_ProfileType 4;
BA_ "UserSigValidity" SG_ 2462366209 PROSHORT_V2_3_ProfileType 3;
BA_REL_ "GenSigTimeoutTime" BU_SG_REL_ DSAU SG_ 2462366209 PROSHORT_V2_3_ProfileType 0;
BA_ "Version" SG_ 2462366209 PROSHORT_V2_3_ProfileType "20.03.06";
BA_ "GenSigSendType" SG_ 2462366209 PROSHORT_V2_3_CyclicCounter 4;
BA_ "UserSigValidity" SG_ 2462366209 PROSHORT_V2_3_CyclicCounter 3;
BA_REL_ "GenSigTimeoutTime" BU_SG_REL_ DSAU SG_ 2462366209 PROSHORT_V2_3_CyclicCounter 0;
BA_ "Version" SG_ 2462366209 PROSHORT_V2_3_CyclicCounter "20.03.06";
BA_ "GenSigSendType" SG_ 2462366209 PROSHORT_V2_3_Accuracy 4;
BA_ "GenSigStartValue" SG_ 2462366209 PROSHORT_V2_3_Accuracy 6;
BA_ "UserSigValidity" SG_ 2462366209 PROSHORT_V2_3_Accuracy 3;
BA_ "Version" SG_ 2462366209 PROSHORT_V2_3_Accuracy "20.03.06";
BA_ "GenMsgCycleTime" BO_ 2458168065 0;
BA_ "VFrameFormat" BO_ 2458168065 1;
BA_ "GenSigSendType" SG_ 2458168065 CF_AVN_CluWelcomeSnd 4;
BA_ "UserSigValidity" SG_ 2458168065 CF_AVN_CluWelcomeSnd 3;
BA_ "Version" SG_ 2458168065 CF_AVN_CluWelcomeSnd "18.04.02";
BA_ "GenSigSendType" SG_ 2458168065 CF_AVN_CluTransmissionDisp 4;
BA_ "UserSigValidity" SG_ 2458168065 CF_AVN_CluTransmissionDisp 3;
BA_ "Version" SG_ 2458168065 CF_AVN_CluTransmissionDisp "18.04.02";
BA_ "GenSigSendType" SG_ 2458168065 CF_AVN_CluWiperLight 4;
BA_ "UserSigValidity" SG_ 2458168065 CF_AVN_CluWiperLight 3;
BA_ "Version" SG_ 2458168065 CF_AVN_CluWiperLight "18.04.02";
BA_ "GenSigSendType" SG_ 2458168065 CF_AVN_CluRoadInfoGuide 4;
BA_ "UserSigValidity" SG_ 2458168065 CF_AVN_CluRoadInfoGuide 3;
BA_ "Version" SG_ 2458168065 CF_AVN_CluRoadInfoGuide "18.04.02";
BA_ "GenSigSendType" SG_ 2458168065 CF_AVN_CluUserSettingPeriod 4;
BA_ "GenSigStartValue" SG_ 2458168065 CF_AVN_CluUserSettingPeriod 127;
BA_ "UserSigValidity" SG_ 2458168065 CF_AVN_CluUserSettingPeriod 3;
BA_ "Version" SG_ 2458168065 CF_AVN_CluUserSettingPeriod "19.01.10";
BA_ "GenSigSendType" SG_ 2458168065 CF_AVN_CluAutoInitFuelEconomy 4;
BA_ "UserSigValidity" SG_ 2458168065 CF_AVN_CluAutoInitFuelEconomy 3;
BA_ "Version" SG_ 2458168065 CF_AVN_CluAutoInitFuelEconomy "18.04.02";
BA_ "GenSigSendType" SG_ 2458168065 CF_AVN_CluSubspeedOdometerDisp 4;
BA_ "UserSigValidity" SG_ 2458168065 CF_AVN_CluSubspeedOdometerDisp 3;
BA_ "Version" SG_ 2458168065 CF_AVN_CluSubspeedOdometerDisp "18.09.04";
BA_ "GenSigSendType" SG_ 2458168065 CF_AVN_CluFuelEconUnit_mi 4;
BA_ "UserSigValidity" SG_ 2458168065 CF_AVN_CluFuelEconUnit_mi 3;
BA_ "Version" SG_ 2458168065 CF_AVN_CluFuelEconUnit_mi "18.09.04";
BA_ "GenSigSendType" SG_ 2458168065 CF_AVN_CluFuelEconUnit_km 4;
BA_ "UserSigValidity" SG_ 2458168065 CF_AVN_CluFuelEconUnit_km 3;
BA_ "Version" SG_ 2458168065 CF_AVN_CluFuelEconUnit_km "18.09.04";
BA_ "GenSigSendType" SG_ 2458168065 CF_AVN_CluUserSettingDistance 4;
BA_ "GenSigStartValue" SG_ 2458168065 CF_AVN_CluUserSettingDistance 131071;
BA_ "UserSigValidity" SG_ 2458168065 CF_AVN_CluUserSettingDistance 3;
BA_ "Version" SG_ 2458168065 CF_AVN_CluUserSettingDistance "19.01.10";
BA_ "GenSigSendType" SG_ 2458168065 CF_AVN_CluRheostatLvl 4;
BA_ "GenSigStartValue" SG_ 2458168065 CF_AVN_CluRheostatLvl 31;
BA_ "UserSigValidity" SG_ 2458168065 CF_AVN_CluRheostatLvl 3;
BA_ "Version" SG_ 2458168065 CF_AVN_CluRheostatLvl "18.06.04";
BA_ "GenSigSendType" SG_ 2458168065 CF_AVN_CluVoiceVolume 4;
BA_ "UserSigValidity" SG_ 2458168065 CF_AVN_CluVoiceVolume 3;
BA_ "Version" SG_ 2458168065 CF_AVN_CluVoiceVolume "18.04.02";
BA_ "GenSigSendType" SG_ 2458168065 CF_AVN_EVReset 4;
BA_ "UserSigValidity" SG_ 2458168065 CF_AVN_EVReset 7;
BA_ "Version" SG_ 2458168065 CF_AVN_EVReset "18.09.04";
BA_ "GenSigSendType" SG_ 2458168065 CF_AVN_UnitReset 4;
BA_ "UserSigValidity" SG_ 2458168065 CF_AVN_UnitReset 3;
BA_ "Version" SG_ 2458168065 CF_AVN_UnitReset "18.09.04";
BA_ "GenSigSendType" SG_ 2458168065 CF_AVN_IcyRoadWarn 4;
BA_ "UserSigValidity" SG_ 2458168065 CF_AVN_IcyRoadWarn 3;
BA_ "Version" SG_ 2458168065 CF_AVN_IcyRoadWarn "18.04.02";
BA_ "GenSigSendType" SG_ 2458168065 CF_AVN_CluServiceReminderReset 4;
BA_ "UserSigValidity" SG_ 2458168065 CF_AVN_CluServiceReminderReset 3;
BA_ "Version" SG_ 2458168065 CF_AVN_CluServiceReminderReset "18.04.02";
BA_ "GenSigSendType" SG_ 2458168065 CF_AVN_CluUSMReset 4;
BA_ "UserSigValidity" SG_ 2458168065 CF_AVN_CluUSMReset 3;
BA_REL_ "GenSigTimeoutTime" BU_SG_REL_ RWPC SG_ 2458168065 CF_AVN_CluUSMReset 0;
BA_REL_ "GenSigTimeoutTime" BU_SG_REL_ PSM SG_ 2458168065 CF_AVN_CluUSMReset 0;
BA_REL_ "GenSigTimeoutTime" BU_SG_REL_ APSM SG_ 2458168065 CF_AVN_CluUSMReset 0;
BA_REL_ "GenSigTimeoutTime" BU_SG_REL_ RLPSM SG_ 2458168065 CF_AVN_CluUSMReset 0;
BA_REL_ "GenSigTimeoutTime" BU_SG_REL_ RRPSM SG_ 2458168065 CF_AVN_CluUSMReset 0;
BA_REL_ "GenSigTimeoutTime" BU_SG_REL_ RLHV SG_ 2458168065 CF_AVN_CluUSMReset 0;
BA_REL_ "GenSigTimeoutTime" BU_SG_REL_ RRHV SG_ 2458168065 CF_AVN_CluUSMReset 0;
BA_REL_ "GenSigTimeoutTime" BU_SG_REL_ SHVU_RR SG_ 2458168065 CF_AVN_CluUSMReset 0;
BA_REL_ "GenSigTimeoutTime" BU_SG_REL_ DPSS SG_ 2458168065 CF_AVN_CluUSMReset 0;
BA_REL_ "GenSigTimeoutTime" BU_SG_REL_ APSS SG_ 2458168065 CF_AVN_CluUSMReset 0;
BA_REL_ "GenSigTimeoutTime" BU_SG_REL_ ATS SG_ 2458168065 CF_AVN_CluUSMReset 0;
BA_REL_ "GenSigTimeoutTime" BU_SG_REL_ DSAU SG_ 2458168065 CF_AVN_CluUSMReset 0;
BA_REL_ "GenSigTimeoutTime" BU_SG_REL_ ASAU SG_ 2458168065 CF_AVN_CluUSMReset 0;
BA_ "Version" SG_ 2458168065 CF_AVN_CluUSMReset "21.01.08";
BA_ "GenSigSendType" SG_ 2458168065 CF_AVN_CluServiceReminderSet 4;
BA_ "UserSigValidity" SG_ 2458168065 CF_AVN_CluServiceReminderSet 3;
BA_ "Version" SG_ 2458168065 CF_AVN_CluServiceReminderSet "18.04.02";
BA_ "GenMsgCycleTime" BO_ 2323817217 0;
BA_ "VFrameFormat" BO_ 2323817217 1;
BA_ "GenSigSendType" SG_ 2323817217 CF_AVN_HtBlcRLNValueSet 4;
BA_ "UserSigValidity" SG_ 2323817217 CF_AVN_HtBlcRLNValueSet 3;
BA_REL_ "GenSigTimeoutTime" BU_SG_REL_ RLPSM SG_ 2323817217 CF_AVN_HtBlcRLNValueSet 0;
BA_REL_ "GenSigTimeoutTime" BU_SG_REL_ RRPSM SG_ 2323817217 CF_AVN_HtBlcRLNValueSet 0;
BA_REL_ "GenSigTimeoutTime" BU_SG_REL_ RLHV SG_ 2323817217 CF_AVN_HtBlcRLNValueSet 0;
BA_REL_ "GenSigTimeoutTime" BU_SG_REL_ SHVU_RR SG_ 2323817217 CF_AVN_HtBlcRLNValueSet 0;
BA_ "Version" SG_ 2323817217 CF_AVN_HtBlcRLNValueSet "20.06.03";
BA_ "Description" SG_ 2323817217 CF_AVN_BRAKE_PedalfeelNValueSet2 "USM request for Brake Mode (New spec)";
BA_ "GenSigSendType" SG_ 2323817217 CF_AVN_BRAKE_PedalfeelNValueSet2 4;
BA_ "UserSigValidity" SG_ 2323817217 CF_AVN_BRAKE_PedalfeelNValueSet2 3;
BA_ "Version" SG_ 2323817217 CF_AVN_BRAKE_PedalfeelNValueSet2 "20.04.06";
BA_ "GenSigSendType" SG_ 2323817217 CF_AVN_HtBlcRRNValueSet 4;
BA_ "UserSigValidity" SG_ 2323817217 CF_AVN_HtBlcRRNValueSet 3;
BA_REL_ "GenSigTimeoutTime" BU_SG_REL_ RLPSM SG_ 2323817217 CF_AVN_HtBlcRRNValueSet 0;
BA_REL_ "GenSigTimeoutTime" BU_SG_REL_ RRPSM SG_ 2323817217 CF_AVN_HtBlcRRNValueSet 0;
BA_REL_ "GenSigTimeoutTime" BU_SG_REL_ RRHV SG_ 2323817217 CF_AVN_HtBlcRRNValueSet 0;
BA_REL_ "GenSigTimeoutTime" BU_SG_REL_ SHVU_RR SG_ 2323817217 CF_AVN_HtBlcRRNValueSet 0;
BA_ "Version" SG_ 2323817217 CF_AVN_HtBlcRRNValueSet "20.06.03";
BA_ "Description" SG_ 2323817217 CF_AVN_RemoteWDWNValueSet "Remote Window On/Off Set signal of USM for Fob Key";
BA_ "GenSigSendType" SG_ 2323817217 CF_AVN_RemoteWDWNValueSet 4;
BA_ "UserSigValidity" SG_ 2323817217 CF_AVN_RemoteWDWNValueSet 3;
BA_ "Version" SG_ 2323817217 CF_AVN_RemoteWDWNValueSet "20.07.14";
BA_ "Description" SG_ 2323817217 CF_AVN_ADrLNValueSet2 "USM Request for Auto Door Lock";
BA_ "GenSigSendType" SG_ 2323817217 CF_AVN_ADrLNValueSet2 4;
BA_ "UserSigValidity" SG_ 2323817217 CF_AVN_ADrLNValueSet2 3;
BA_ "Version" SG_ 2323817217 CF_AVN_ADrLNValueSet2 "20.11.00";
BA_ "Description" SG_ 2323817217 CF_AVN_PCA_RrEquipNvalueSet "Headunit Setting signal for Rear Safety of USM";
BA_ "GenSigSendType" SG_ 2323817217 CF_AVN_PCA_RrEquipNvalueSet 4;
BA_ "UserSigValidity" SG_ 2323817217 CF_AVN_PCA_RrEquipNvalueSet 3;
BA_ "Version" SG_ 2323817217 CF_AVN_PCA_RrEquipNvalueSet "20.06.04";
BA_ "GenMsgCycleTime" BO_ 1981 0;
BA_ "GenMsgCycleTimeFast" BO_ 1981 0;
BA_ "GenMsgNrOfRepetition" BO_ 1981 0;
BA_ "DiagResponse" BO_ 1981 1;
BA_ "GenMsgILSupport" BO_ 1981 0;
BA_ "TpMessage" BO_ 1981 1;
BA_ "TpTxIndex" BO_ 1981 56;
BA_ "Description" SG_ 1981 ICC_GST_Byte0 "TP Index : 56";
BA_ "UsrSigPurpose" SG_ 1981 ICC_GST_Byte0 4;
BA_ "UserSigValidity" SG_ 1981 ICC_GST_Byte0 0;
BA_REL_ "GenSigTimeoutTime" BU_SG_REL_ CGW_CCU SG_ 1981 ICC_GST_Byte0 0;
BA_ "NetworkRequestHoldingTime" SG_ 1981 ICC_GST_Byte0 5000;
BA_ "Version" SG_ 1981 ICC_GST_Byte0 "21.03.02";
BA_ "Description" SG_ 1981 ICC_GST_Byte2 "TP Index : 56";
BA_ "UsrSigPurpose" SG_ 1981 ICC_GST_Byte2 4;
BA_ "UserSigValidity" SG_ 1981 ICC_GST_Byte2 0;
BA_REL_ "GenSigTimeoutTime" BU_SG_REL_ CGW_CCU SG_ 1981 ICC_GST_Byte2 0;
BA_ "NetworkRequestHoldingTime" SG_ 1981 ICC_GST_Byte2 5000;
BA_ "Version" SG_ 1981 ICC_GST_Byte2 "21.03.02";
BA_ "Description" SG_ 1981 ICC_GST_Byte3 "TP Index : 56";
BA_ "UsrSigPurpose" SG_ 1981 ICC_GST_Byte3 4;
BA_ "UserSigValidity" SG_ 1981 ICC_GST_Byte3 0;
BA_REL_ "GenSigTimeoutTime" BU_SG_REL_ CGW_CCU SG_ 1981 ICC_GST_Byte3 0;
BA_ "NetworkRequestHoldingTime" SG_ 1981 ICC_GST_Byte3 5000;
BA_ "Version" SG_ 1981 ICC_GST_Byte3 "21.03.02";
BA_ "Description" SG_ 1981 ICC_GST_Byte4 "TP Index : 56";
BA_ "UsrSigPurpose" SG_ 1981 ICC_GST_Byte4 4;
BA_ "UserSigValidity" SG_ 1981 ICC_GST_Byte4 0;
BA_REL_ "GenSigTimeoutTime" BU_SG_REL_ CGW_CCU SG_ 1981 ICC_GST_Byte4 0;
BA_ "NetworkRequestHoldingTime" SG_ 1981 ICC_GST_Byte4 5000;
BA_ "Version" SG_ 1981 ICC_GST_Byte4 "21.03.02";
BA_ "Description" SG_ 1981 ICC_GST_Byte5 "TP Index : 56";
BA_ "UsrSigPurpose" SG_ 1981 ICC_GST_Byte5 4;
BA_ "UserSigValidity" SG_ 1981 ICC_GST_Byte5 0;
BA_REL_ "GenSigTimeoutTime" BU_SG_REL_ CGW_CCU SG_ 1981 ICC_GST_Byte5 0;
BA_ "NetworkRequestHoldingTime" SG_ 1981 ICC_GST_Byte5 5000;
BA_ "Version" SG_ 1981 ICC_GST_Byte5 "21.03.02";
BA_ "Description" SG_ 1981 ICC_GST_Byte6 "TP Index : 56";
BA_ "UsrSigPurpose" SG_ 1981 ICC_GST_Byte6 4;
BA_ "UserSigValidity" SG_ 1981 ICC_GST_Byte6 0;
BA_REL_ "GenSigTimeoutTime" BU_SG_REL_ CGW_CCU SG_ 1981 ICC_GST_Byte6 0;
BA_ "NetworkRequestHoldingTime" SG_ 1981 ICC_GST_Byte6 5000;
BA_ "Version" SG_ 1981 ICC_GST_Byte6 "21.03.02";
BA_ "Description" SG_ 1981 ICC_GST_Byte7 "TP Index : 56";
BA_ "UsrSigPurpose" SG_ 1981 ICC_GST_Byte7 4;
BA_ "UserSigValidity" SG_ 1981 ICC_GST_Byte7 0;
BA_REL_ "GenSigTimeoutTime" BU_SG_REL_ CGW_CCU SG_ 1981 ICC_GST_Byte7 0;
BA_ "NetworkRequestHoldingTime" SG_ 1981 ICC_GST_Byte7 5000;
BA_ "Version" SG_ 1981 ICC_GST_Byte7 "21.03.02";
BA_ "Description" SG_ 1981 ICC_GST_Byte1 "TP Index : 56";
BA_ "UsrSigPurpose" SG_ 1981 ICC_GST_Byte1 4;
BA_ "UserSigValidity" SG_ 1981 ICC_GST_Byte1 0;
BA_REL_ "GenSigTimeoutTime" BU_SG_REL_ CGW_CCU SG_ 1981 ICC_GST_Byte1 0;
BA_ "NetworkRequestHoldingTime" SG_ 1981 ICC_GST_Byte1 5000;
BA_ "Version" SG_ 1981 ICC_GST_Byte1 "21.03.02";
BA_ "GenMsgSendType" BO_ 902 0;
BA_ "GenSigSendType" SG_ 902 PSM_DrvStEsyAcsUSMSta 4;
BA_ "UserSigValidity" SG_ 902 PSM_DrvStEsyAcsUSMSta 0;
BA_REL_ "GenSigTimeoutTime" BU_SG_REL_ DSAU SG_ 902 PSM_DrvStEsyAcsUSMSta 1500;
BA_REL_ "GenSigTimeoutTime" BU_SG_REL_ CGW_CCU SG_ 902 PSM_DrvStEsyAcsUSMSta 1500;
BA_ "NetworkRequest" SG_ 902 PSM_DrvStEsyAcsUSMSta 0;
BA_ "NetworkRequestHoldingTime" SG_ 902 PSM_DrvStEsyAcsUSMSta 5000;
BA_ "Version" SG_ 902 PSM_DrvStEsyAcsUSMSta "17.11.00";
BA_ "Description" SG_ 902 SmrtIMS_StatureRspVal "User height information response value for Health Care IMS";
BA_ "GenSigSendType" SG_ 902 SmrtIMS_StatureRspVal 4;
BA_ "UserSigValidity" SG_ 902 SmrtIMS_StatureRspVal 0;
BA_REL_ "GenSigTimeoutTime" BU_SG_REL_ CGW_CCU SG_ 902 SmrtIMS_StatureRspVal 1500;
BA_ "NetworkRequest" SG_ 902 SmrtIMS_StatureRspVal 0;
BA_ "NetworkRequestHoldingTime" SG_ 902 SmrtIMS_StatureRspVal 5000;
BA_ "Version" SG_ 902 SmrtIMS_StatureRspVal "17.11.00";
BA_ "Description" SG_ 902 SmrtIMS_SeatedHghtRspVal "User sit height information response value for Health Care IMS";
BA_ "GenSigSendType" SG_ 902 SmrtIMS_SeatedHghtRspVal 4;
BA_ "UserSigValidity" SG_ 902 SmrtIMS_SeatedHghtRspVal 0;
BA_REL_ "GenSigTimeoutTime" BU_SG_REL_ CGW_CCU SG_ 902 SmrtIMS_SeatedHghtRspVal 1500;
BA_ "NetworkRequest" SG_ 902 SmrtIMS_SeatedHghtRspVal 0;
BA_ "NetworkRequestHoldingTime" SG_ 902 SmrtIMS_SeatedHghtRspVal 5000;
BA_ "Version" SG_ 902 SmrtIMS_SeatedHghtRspVal "17.11.00";
BA_ "Description" SG_ 902 SmrtIMS_WghtRspVal "User weight information repsponse value for Health Care IMS";
BA_ "GenSigSendType" SG_ 902 SmrtIMS_WghtRspVal 4;
BA_ "UserSigValidity" SG_ 902 SmrtIMS_WghtRspVal 0;
BA_REL_ "GenSigTimeoutTime" BU_SG_REL_ CGW_CCU SG_ 902 SmrtIMS_WghtRspVal 1500;
BA_ "NetworkRequest" SG_ 902 SmrtIMS_WghtRspVal 0;
BA_ "NetworkRequestHoldingTime" SG_ 902 SmrtIMS_WghtRspVal 5000;
BA_ "Version" SG_ 902 SmrtIMS_WghtRspVal "17.11.00";
BA_ "Description" SG_ 902 SmartIMS_DisReq "For displaying the state of seat moving";
BA_ "GenSigSendType" SG_ 902 SmartIMS_DisReq 4;
BA_ "UserSigValidity" SG_ 902 SmartIMS_DisReq 0;
BA_REL_ "GenSigTimeoutTime" BU_SG_REL_ CGW_CCU SG_ 902 SmartIMS_DisReq 1500;
BA_ "NetworkRequest" SG_ 902 SmartIMS_DisReq 0;
BA_ "NetworkRequestHoldingTime" SG_ 902 SmartIMS_DisReq 5000;
BA_ "Version" SG_ 902 SmartIMS_DisReq "17.11.00";
BA_ "Description" SG_ 902 SmrtIMS_ExitSta "-(Old)C_SmartIMSExit";
BA_ "GenSigSendType" SG_ 902 SmrtIMS_ExitSta 4;
BA_ "UserSigValidity" SG_ 902 SmrtIMS_ExitSta 0;
BA_REL_ "GenSigTimeoutTime" BU_SG_REL_ CGW_CCU SG_ 902 SmrtIMS_ExitSta 1500;
BA_ "NetworkRequest" SG_ 902 SmrtIMS_ExitSta 0;
BA_ "NetworkRequestHoldingTime" SG_ 902 SmrtIMS_ExitSta 5000;
BA_ "Version" SG_ 902 SmrtIMS_ExitSta "17.11.00";
BA_ "Description" SG_ 902 PSM_IMSOptTyp "-(Old)C_IMSOption";
BA_ "GenSigSendType" SG_ 902 PSM_IMSOptTyp 4;
BA_ "UserSigValidity" SG_ 902 PSM_IMSOptTyp 0;
BA_REL_ "GenSigTimeoutTime" BU_SG_REL_ CGW_CCU SG_ 902 PSM_IMSOptTyp 1500;
BA_ "NetworkRequest" SG_ 902 PSM_IMSOptTyp 0;
BA_ "NetworkRequestHoldingTime" SG_ 902 PSM_IMSOptTyp 5000;
BA_ "Version" SG_ 902 PSM_IMSOptTyp "17.11.00";
BA_ "GenMsgSendType" BO_ 903 0;
BA_ "Description" SG_ 903 PSM_DrvStSldFwdDis "This signal is used to display the seat movement to AVN";
BA_ "GenSigSendType" SG_ 903 PSM_DrvStSldFwdDis 4;
BA_ "UserSigValidity" SG_ 903 PSM_DrvStSldFwdDis 1;
BA_REL_ "GenSigTimeoutTime" BU_SG_REL_ DPSS SG_ 903 PSM_DrvStSldFwdDis 1500;
BA_REL_ "GenSigTimeoutTime" BU_SG_REL_ CGW_CCU SG_ 903 PSM_DrvStSldFwdDis 1500;
BA_ "NetworkRequest" SG_ 903 PSM_DrvStSldFwdDis 0;
BA_ "NetworkRequestHoldingTime" SG_ 903 PSM_DrvStSldFwdDis 5000;
BA_ "Version" SG_ 903 PSM_DrvStSldFwdDis "17.11.00";
BA_ "Description" SG_ 903 PSM_DrvStTiltDnDis "This signal is used to display the seat movement to AVN";
BA_ "GenSigSendType" SG_ 903 PSM_DrvStTiltDnDis 4;
BA_ "UserSigValidity" SG_ 903 PSM_DrvStTiltDnDis 1;
BA_REL_ "GenSigTimeoutTime" BU_SG_REL_ DPSS SG_ 903 PSM_DrvStTiltDnDis 1500;
BA_REL_ "GenSigTimeoutTime" BU_SG_REL_ CGW_CCU SG_ 903 PSM_DrvStTiltDnDis 1500;
BA_ "NetworkRequest" SG_ 903 PSM_DrvStTiltDnDis 0;
BA_ "NetworkRequestHoldingTime" SG_ 903 PSM_DrvStTiltDnDis 5000;
BA_ "Version" SG_ 903 PSM_DrvStTiltDnDis "17.11.00";
BA_ "Description" SG_ 903 PSM_DrvStHghtUpDis "This signal is used to display the seat movement to AVN";
BA_ "GenSigSendType" SG_ 903 PSM_DrvStHghtUpDis 4;
BA_ "UserSigValidity" SG_ 903 PSM_DrvStHghtUpDis 1;
BA_REL_ "GenSigTimeoutTime" BU_SG_REL_ DPSS SG_ 903 PSM_DrvStHghtUpDis 1500;
BA_REL_ "GenSigTimeoutTime" BU_SG_REL_ CGW_CCU SG_ 903 PSM_DrvStHghtUpDis 1500;
BA_ "NetworkRequest" SG_ 903 PSM_DrvStHghtUpDis 0;
BA_ "NetworkRequestHoldingTime" SG_ 903 PSM_DrvStHghtUpDis 5000;
BA_ "Version" SG_ 903 PSM_DrvStHghtUpDis "17.11.00";
BA_ "Description" SG_ 903 PSM_DrvStHghtDnDis "This signal is used to display the seat movement to AVN";
BA_ "GenSigSendType" SG_ 903 PSM_DrvStHghtDnDis 4;
BA_ "UserSigValidity" SG_ 903 PSM_DrvStHghtDnDis 1;
BA_REL_ "GenSigTimeoutTime" BU_SG_REL_ DPSS SG_ 903 PSM_DrvStHghtDnDis 1500;
BA_REL_ "GenSigTimeoutTime" BU_SG_REL_ CGW_CCU SG_ 903 PSM_DrvStHghtDnDis 1500;
BA_ "NetworkRequest" SG_ 903 PSM_DrvStHghtDnDis 0;
BA_ "NetworkRequestHoldingTime" SG_ 903 PSM_DrvStHghtDnDis 5000;
BA_ "Version" SG_ 903 PSM_DrvStHghtDnDis "17.11.00";
BA_ "Description" SG_ 903 PSM_DrvStCushExtBckwdDis "This signal is used to display the seat movement to AVN";
BA_ "GenSigSendType" SG_ 903 PSM_DrvStCushExtBckwdDis 4;
BA_ "UserSigValidity" SG_ 903 PSM_DrvStCushExtBckwdDis 1;
BA_REL_ "GenSigTimeoutTime" BU_SG_REL_ DPSS SG_ 903 PSM_DrvStCushExtBckwdDis 1500;
BA_REL_ "GenSigTimeoutTime" BU_SG_REL_ CGW_CCU SG_ 903 PSM_DrvStCushExtBckwdDis 1500;
BA_ "NetworkRequest" SG_ 903 PSM_DrvStCushExtBckwdDis 0;
BA_ "NetworkRequestHoldingTime" SG_ 903 PSM_DrvStCushExtBckwdDis 5000;
BA_ "Version" SG_ 903 PSM_DrvStCushExtBckwdDis "17.11.00";
BA_ "Description" SG_ 903 PSM_DrvStCushExtFwdDis "This signal is used to display the seat movement to AVN";
BA_ "GenSigSendType" SG_ 903 PSM_DrvStCushExtFwdDis 4;
BA_ "UserSigValidity" SG_ 903 PSM_DrvStCushExtFwdDis 1;
BA_REL_ "GenSigTimeoutTime" BU_SG_REL_ DPSS SG_ 903 PSM_DrvStCushExtFwdDis 1500;
BA_REL_ "GenSigTimeoutTime" BU_SG_REL_ CGW_CCU SG_ 903 PSM_DrvStCushExtFwdDis 1500;
BA_ "NetworkRequest" SG_ 903 PSM_DrvStCushExtFwdDis 0;
BA_ "NetworkRequestHoldingTime" SG_ 903 PSM_DrvStCushExtFwdDis 5000;
BA_ "Version" SG_ 903 PSM_DrvStCushExtFwdDis "17.11.00";
BA_ "Description" SG_ 903 PSM_DrvStSldBckwdDis "This signal is used to display the seat movement to AVN";
BA_ "GenSigSendType" SG_ 903 PSM_DrvStSldBckwdDis 4;
BA_ "UserSigValidity" SG_ 903 PSM_DrvStSldBckwdDis 1;
BA_REL_ "GenSigTimeoutTime" BU_SG_REL_ DPSS SG_ 903 PSM_DrvStSldBckwdDis 1500;
BA_REL_ "GenSigTimeoutTime" BU_SG_REL_ CGW_CCU SG_ 903 PSM_DrvStSldBckwdDis 1500;
BA_ "NetworkRequest" SG_ 903 PSM_DrvStSldBckwdDis 0;
BA_ "NetworkRequestHoldingTime" SG_ 903 PSM_DrvStSldBckwdDis 5000;
BA_ "Version" SG_ 903 PSM_DrvStSldBckwdDis "17.11.00";
BA_ "Description" SG_ 903 PSM_DrvStHdRstUpDis "This signal is used to display the seat movement to AVN";
BA_ "GenSigSendType" SG_ 903 PSM_DrvStHdRstUpDis 4;
BA_ "UserSigValidity" SG_ 903 PSM_DrvStHdRstUpDis 1;
BA_REL_ "GenSigTimeoutTime" BU_SG_REL_ CGW_CCU SG_ 903 PSM_DrvStHdRstUpDis 1500;
BA_ "NetworkRequest" SG_ 903 PSM_DrvStHdRstUpDis 0;
BA_ "NetworkRequestHoldingTime" SG_ 903 PSM_DrvStHdRstUpDis 5000;
BA_ "Version" SG_ 903 PSM_DrvStHdRstUpDis "20.07.05";
BA_ "Description" SG_ 903 PSM_DrvStHdRstDnDis "This signal is used to display the seat movement to AVN";
BA_ "GenSigSendType" SG_ 903 PSM_DrvStHdRstDnDis 4;
BA_ "UserSigValidity" SG_ 903 PSM_DrvStHdRstDnDis 1;
BA_REL_ "GenSigTimeoutTime" BU_SG_REL_ CGW_CCU SG_ 903 PSM_DrvStHdRstDnDis 1500;
BA_ "NetworkRequest" SG_ 903 PSM_DrvStHdRstDnDis 0;
BA_ "NetworkRequestHoldingTime" SG_ 903 PSM_DrvStHdRstDnDis 5000;
BA_ "Version" SG_ 903 PSM_DrvStHdRstDnDis "17.11.00";
BA_ "Description" SG_ 903 PSM_DrvStHdRstFwdDis "This signal is used to display the seat movement to AVN";
BA_ "GenSigSendType" SG_ 903 PSM_DrvStHdRstFwdDis 4;
BA_ "UserSigValidity" SG_ 903 PSM_DrvStHdRstFwdDis 1;
BA_REL_ "GenSigTimeoutTime" BU_SG_REL_ CGW_CCU SG_ 903 PSM_DrvStHdRstFwdDis 1500;
BA_ "NetworkRequest" SG_ 903 PSM_DrvStHdRstFwdDis 0;
BA_ "NetworkRequestHoldingTime" SG_ 903 PSM_DrvStHdRstFwdDis 5000;
BA_ "Version" SG_ 903 PSM_DrvStHdRstFwdDis "17.11.00";
BA_ "Description" SG_ 903 PSM_DrvStHdRstBckwdDis "This signal is used to display the seat movement to AVN";
BA_ "GenSigSendType" SG_ 903 PSM_DrvStHdRstBckwdDis 4;
BA_ "UserSigValidity" SG_ 903 PSM_DrvStHdRstBckwdDis 1;
BA_REL_ "GenSigTimeoutTime" BU_SG_REL_ CGW_CCU SG_ 903 PSM_DrvStHdRstBckwdDis 1500;
BA_ "NetworkRequest" SG_ 903 PSM_DrvStHdRstBckwdDis 0;
BA_ "NetworkRequestHoldingTime" SG_ 903 PSM_DrvStHdRstBckwdDis 5000;
BA_ "Version" SG_ 903 PSM_DrvStHdRstBckwdDis "17.11.00";
BA_ "Description" SG_ 903 PSM_DrvStLmbrDefDis "This signal is used to display the seat movement to AVN";
BA_ "GenSigSendType" SG_ 903 PSM_DrvStLmbrDefDis 4;
BA_ "UserSigValidity" SG_ 903 PSM_DrvStLmbrDefDis 1;
BA_REL_ "GenSigTimeoutTime" BU_SG_REL_ DPSS SG_ 903 PSM_DrvStLmbrDefDis 1500;
BA_REL_ "GenSigTimeoutTime" BU_SG_REL_ CGW_CCU SG_ 903 PSM_DrvStLmbrDefDis 1500;
BA_ "NetworkRequest" SG_ 903 PSM_DrvStLmbrDefDis 0;
BA_ "NetworkRequestHoldingTime" SG_ 903 PSM_DrvStLmbrDefDis 5000;
BA_ "Version" SG_ 903 PSM_DrvStLmbrDefDis "17.11.00";
BA_ "Description" SG_ 903 PSM_DrvStLmbrLoDis "This signal is used to display the seat movement to AVN";
BA_ "GenSigSendType" SG_ 903 PSM_DrvStLmbrLoDis 4;
BA_ "UserSigValidity" SG_ 903 PSM_DrvStLmbrLoDis 1;
BA_REL_ "GenSigTimeoutTime" BU_SG_REL_ DPSS SG_ 903 PSM_DrvStLmbrLoDis 1500;
BA_REL_ "GenSigTimeoutTime" BU_SG_REL_ CGW_CCU SG_ 903 PSM_DrvStLmbrLoDis 1500;
BA_ "NetworkRequest" SG_ 903 PSM_DrvStLmbrLoDis 0;
BA_ "NetworkRequestHoldingTime" SG_ 903 PSM_DrvStLmbrLoDis 5000;
BA_ "Version" SG_ 903 PSM_DrvStLmbrLoDis "17.11.00";
BA_ "Description" SG_ 903 PSM_DrvStLmbrMdlDis "This signal is used to display the seat movement to AVN";
BA_ "GenSigSendType" SG_ 903 PSM_DrvStLmbrMdlDis 4;
BA_ "UserSigValidity" SG_ 903 PSM_DrvStLmbrMdlDis 1;
BA_REL_ "GenSigTimeoutTime" BU_SG_REL_ DPSS SG_ 903 PSM_DrvStLmbrMdlDis 1500;
BA_REL_ "GenSigTimeoutTime" BU_SG_REL_ CGW_CCU SG_ 903 PSM_DrvStLmbrMdlDis 1500;
BA_ "NetworkRequest" SG_ 903 PSM_DrvStLmbrMdlDis 0;
BA_ "NetworkRequestHoldingTime" SG_ 903 PSM_DrvStLmbrMdlDis 5000;
BA_ "Version" SG_ 903 PSM_DrvStLmbrMdlDis "17.11.00";
BA_ "Description" SG_ 903 PSM_DrvStLmbrUpDis "This signal is used to display the seat movement to AVN";
BA_ "GenSigSendType" SG_ 903 PSM_DrvStLmbrUpDis 4;
BA_ "UserSigValidity" SG_ 903 PSM_DrvStLmbrUpDis 1;
BA_REL_ "GenSigTimeoutTime" BU_SG_REL_ DPSS SG_ 903 PSM_DrvStLmbrUpDis 1500;
BA_REL_ "GenSigTimeoutTime" BU_SG_REL_ CGW_CCU SG_ 903 PSM_DrvStLmbrUpDis 1500;
BA_ "NetworkRequest" SG_ 903 PSM_DrvStLmbrUpDis 0;
BA_ "NetworkRequestHoldingTime" SG_ 903 PSM_DrvStLmbrUpDis 5000;
BA_ "Version" SG_ 903 PSM_DrvStLmbrUpDis "17.11.00";
BA_ "Description" SG_ 903 PSM_DrvStReclneFwdDis "This signal is used to display the seat movement to AVN";
BA_ "GenSigSendType" SG_ 903 PSM_DrvStReclneFwdDis 4;
BA_ "UserSigValidity" SG_ 903 PSM_DrvStReclneFwdDis 1;
BA_REL_ "GenSigTimeoutTime" BU_SG_REL_ DPSS SG_ 903 PSM_DrvStReclneFwdDis 1500;
BA_REL_ "GenSigTimeoutTime" BU_SG_REL_ CGW_CCU SG_ 903 PSM_DrvStReclneFwdDis 1500;
BA_ "NetworkRequest" SG_ 903 PSM_DrvStReclneFwdDis 0;
BA_ "NetworkRequestHoldingTime" SG_ 903 PSM_DrvStReclneFwdDis 5000;
BA_ "Version" SG_ 903 PSM_DrvStReclneFwdDis "17.11.00";
BA_ "Description" SG_ 903 PSM_LmbrSigSrcTyp "-(Old)C_PSMLumbarOpt";
BA_ "GenSigSendType" SG_ 903 PSM_LmbrSigSrcTyp 4;
BA_ "UserSigValidity" SG_ 903 PSM_LmbrSigSrcTyp 0;
BA_REL_ "GenSigTimeoutTime" BU_SG_REL_ CGW_CCU SG_ 903 PSM_LmbrSigSrcTyp 1500;
BA_ "NetworkRequest" SG_ 903 PSM_LmbrSigSrcTyp 0;
BA_ "NetworkRequestHoldingTime" SG_ 903 PSM_LmbrSigSrcTyp 5000;
BA_ "Version" SG_ 903 PSM_LmbrSigSrcTyp "17.11.00";
BA_ "Description" SG_ 903 PSM_DrvStReclneBckwdDis "This signal is used to display the seat movement to AVN";
BA_ "GenSigSendType" SG_ 903 PSM_DrvStReclneBckwdDis 4;
BA_ "UserSigValidity" SG_ 903 PSM_DrvStReclneBckwdDis 1;
BA_REL_ "GenSigTimeoutTime" BU_SG_REL_ DPSS SG_ 903 PSM_DrvStReclneBckwdDis 1500;
BA_REL_ "GenSigTimeoutTime" BU_SG_REL_ CGW_CCU SG_ 903 PSM_DrvStReclneBckwdDis 1500;
BA_ "NetworkRequest" SG_ 903 PSM_DrvStReclneBckwdDis 0;
BA_ "NetworkRequestHoldingTime" SG_ 903 PSM_DrvStReclneBckwdDis 5000;
BA_ "Version" SG_ 903 PSM_DrvStReclneBckwdDis "17.11.00";
BA_ "Description" SG_ 903 PSM_DrvStTiltUpDis "This signal is used to display the seat movement to AVN";
BA_ "GenSigSendType" SG_ 903 PSM_DrvStTiltUpDis 4;
BA_ "UserSigValidity" SG_ 903 PSM_DrvStTiltUpDis 1;
BA_REL_ "GenSigTimeoutTime" BU_SG_REL_ DPSS SG_ 903 PSM_DrvStTiltUpDis 1500;
BA_REL_ "GenSigTimeoutTime" BU_SG_REL_ CGW_CCU SG_ 903 PSM_DrvStTiltUpDis 1500;
BA_ "NetworkRequest" SG_ 903 PSM_DrvStTiltUpDis 0;
BA_ "NetworkRequestHoldingTime" SG_ 903 PSM_DrvStTiltUpDis 5000;
BA_ "Version" SG_ 903 PSM_DrvStTiltUpDis "17.11.00";
BA_ "GenMsgSendType" BO_ 904 0;
BA_ "Description" SG_ 904 PSM_DrvReclinePosition "DRIVER SEAT RECLINE POSITION (UNIT: ˚)";
BA_ "GenSigSendType" SG_ 904 PSM_DrvReclinePosition 4;
BA_ "UserSigValidity" SG_ 904 PSM_DrvReclinePosition 0;
BA_REL_ "GenSigTimeoutTime" BU_SG_REL_ RLPSM SG_ 904 PSM_DrvReclinePosition 1500;
BA_REL_ "GenSigTimeoutTime" BU_SG_REL_ CGW_CCU SG_ 904 PSM_DrvReclinePosition 1500;
BA_ "NetworkRequest" SG_ 904 PSM_DrvReclinePosition 0;
BA_ "NetworkRequestHoldingTime" SG_ 904 PSM_DrvReclinePosition 5000;
BA_ "Version" SG_ 904 PSM_DrvReclinePosition "19.08.06";
BA_ "Description" SG_ 904 PSM_EsyAcsGetOffSta "-(Old)C_EasyAccessGetOff";
BA_ "GenSigSendType" SG_ 904 PSM_EsyAcsGetOffSta 4;
BA_ "UserSigValidity" SG_ 904 PSM_EsyAcsGetOffSta 0;
BA_REL_ "GenSigTimeoutTime" BU_SG_REL_ DSAU SG_ 904 PSM_EsyAcsGetOffSta 1500;
BA_ "NetworkRequest" SG_ 904 PSM_EsyAcsGetOffSta 0;
BA_ "NetworkRequestHoldingTime" SG_ 904 PSM_EsyAcsGetOffSta 5000;
BA_ "Version" SG_ 904 PSM_EsyAcsGetOffSta "17.11.00";
BA_ "Description" SG_ 904 PSM_EsyAcsStpSta "-(Old)C_EasyAccessStop";
BA_ "GenSigSendType" SG_ 904 PSM_EsyAcsStpSta 4;
BA_ "UserSigValidity" SG_ 904 PSM_EsyAcsStpSta 0;
BA_REL_ "GenSigTimeoutTime" BU_SG_REL_ DSAU SG_ 904 PSM_EsyAcsStpSta 1500;
BA_ "NetworkRequest" SG_ 904 PSM_EsyAcsStpSta 0;
BA_ "NetworkRequestHoldingTime" SG_ 904 PSM_EsyAcsStpSta 5000;
BA_ "Version" SG_ 904 PSM_EsyAcsStpSta "17.11.00";
BA_ "Description" SG_ 904 PSM_LegRestCloseSta "Rear Leg Rest Close State";
BA_ "GenSigSendType" SG_ 904 PSM_LegRestCloseSta 4;
BA_ "TimeoutValue" SG_ 904 PSM_LegRestCloseSta "0x0";
BA_ "UserSigValidity" SG_ 904 PSM_LegRestCloseSta 0;
BA_REL_ "GenSigTimeoutTime" BU_SG_REL_ RLPSM SG_ 904 PSM_LegRestCloseSta 1500;
BA_ "NetworkRequest" SG_ 904 PSM_LegRestCloseSta 0;
BA_ "NetworkRequestHoldingTime" SG_ 904 PSM_LegRestCloseSta 5000;
BA_ "Version" SG_ 904 PSM_LegRestCloseSta "21.07.05";
BA_ "Description" SG_ 904 PSM_SWVerMajor1 "Indicate the PSM software version as follows:

- The software version is displayed in three digits.

- The Major and Minor digits are separated by '.'

- Signal values are transmitted to ASCII codes.



※ Example

PSM_SWVerMajor1 : 0x41 (HEX) -> ASCII CODE : 'A' 

PSM_SWVerMinor1 : 0x30 (HEX) -> ASCII CODE : '0'

PSM_SWVerMinor2 : 0x33 (HEX) -> ASCII CODE : '3'

=> PSM S/W Ver is displayed 'A.03'";
BA_ "GenSigSendType" SG_ 904 PSM_SWVerMajor1 4;
BA_ "UserSigValidity" SG_ 904 PSM_SWVerMajor1 0;
BA_REL_ "GenSigTimeoutTime" BU_SG_REL_ CGW_CCU SG_ 904 PSM_SWVerMajor1 1500;
BA_ "Version" SG_ 904 PSM_SWVerMajor1 "20.12.04";
BA_ "Description" SG_ 904 PSM_SWVerMinor1 "Indicate the PSM software version as follows:

- The software version is displayed in three digits.

- The Major and Minor digits are separated by '.'

- Signal values are transmitted to ASCII codes.



※ Example

PSM_SWVerMajor1 : 0x41 (HEX) -> ASCII CODE : 'A' 

PSM_SWVerMinor1 : 0x30 (HEX) -> ASCII CODE : '0'

PSM_SWVerMinor2 : 0x33 (HEX) -> ASCII CODE : '3'

=> PSM S/W Ver is displayed 'A.03'";
BA_ "GenSigSendType" SG_ 904 PSM_SWVerMinor1 4;
BA_ "UserSigValidity" SG_ 904 PSM_SWVerMinor1 0;
BA_REL_ "GenSigTimeoutTime" BU_SG_REL_ CGW_CCU SG_ 904 PSM_SWVerMinor1 1500;
BA_ "Version" SG_ 904 PSM_SWVerMinor1 "18.10.06";
BA_ "Description" SG_ 904 PSM_SWVerMinor2 "Indicate the PSM software version as follows:

- The software version is displayed in three digits.

- The Major and Minor digits are separated by '.'

- Signal values are transmitted to ASCII codes.



※ Example

PSM_SWVerMajor1 : 0x41 (HEX) -> ASCII CODE : 'A' 

PSM_SWVerMinor1 : 0x30 (HEX) -> ASCII CODE : '0'

PSM_SWVerMinor2 : 0x33 (HEX) -> ASCII CODE : '3'

=> PSM S/W Ver is displayed 'A.03'";
BA_ "GenSigSendType" SG_ 904 PSM_SWVerMinor2 4;
BA_ "UserSigValidity" SG_ 904 PSM_SWVerMinor2 0;
BA_REL_ "GenSigTimeoutTime" BU_SG_REL_ CGW_CCU SG_ 904 PSM_SWVerMinor2 1500;
BA_ "Version" SG_ 904 PSM_SWVerMinor2 "18.10.06";
BA_ "Description" SG_ 904 PSM_DrvHeightPosition "DRIVER SEAT HEIGHT POSITION (UNIT: mm)";
BA_ "GenSigSendType" SG_ 904 PSM_DrvHeightPosition 4;
BA_ "UserSigValidity" SG_ 904 PSM_DrvHeightPosition 0;
BA_REL_ "GenSigTimeoutTime" BU_SG_REL_ CGW_CCU SG_ 904 PSM_DrvHeightPosition 1500;
BA_ "NetworkRequest" SG_ 904 PSM_DrvHeightPosition 0;
BA_ "NetworkRequestHoldingTime" SG_ 904 PSM_DrvHeightPosition 5000;
BA_ "Version" SG_ 904 PSM_DrvHeightPosition "20.03.03";
BA_ "Description" SG_ 904 PSM_DrvSlidePosition "DRIVER SEAT SLIDE POSITION (UNIT: mm)";
BA_ "GenSigSendType" SG_ 904 PSM_DrvSlidePosition 4;
BA_ "UserSigValidity" SG_ 904 PSM_DrvSlidePosition 0;
BA_REL_ "GenSigTimeoutTime" BU_SG_REL_ RLPSM SG_ 904 PSM_DrvSlidePosition 1500;
BA_REL_ "GenSigTimeoutTime" BU_SG_REL_ CGW_CCU SG_ 904 PSM_DrvSlidePosition 1500;
BA_ "NetworkRequest" SG_ 904 PSM_DrvSlidePosition 0;
BA_ "NetworkRequestHoldingTime" SG_ 904 PSM_DrvSlidePosition 5000;
BA_ "Version" SG_ 904 PSM_DrvSlidePosition "19.08.06";
BA_ "Description" SG_ 904 PSM_EsyAcsGetOnSta "-(Old)C_EasyAccessGetOn";
BA_ "GenSigSendType" SG_ 904 PSM_EsyAcsGetOnSta 4;
BA_ "UserSigValidity" SG_ 904 PSM_EsyAcsGetOnSta 0;
BA_REL_ "GenSigTimeoutTime" BU_SG_REL_ DSAU SG_ 904 PSM_EsyAcsGetOnSta 1500;
BA_ "NetworkRequest" SG_ 904 PSM_EsyAcsGetOnSta 0;
BA_ "NetworkRequestHoldingTime" SG_ 904 PSM_EsyAcsGetOnSta 5000;
BA_ "Version" SG_ 904 PSM_EsyAcsGetOnSta "17.11.00";
BA_ "GenMsgCycleTime" BO_ 1515 0;
BA_ "GenMsgCycleTimeFast" BO_ 1515 0;
BA_ "GenMsgNrOfRepetition" BO_ 1515 0;
BA_ "DiagResponse" BO_ 1515 1;
BA_ "GenMsgILSupport" BO_ 1515 0;
BA_ "TpMessage" BO_ 1515 1;
BA_ "TpTxIndex" BO_ 1515 159;
BA_ "Description" SG_ 1515 RDC_GST_Byte0 "TP Index : 159";
BA_ "UsrSigPurpose" SG_ 1515 RDC_GST_Byte0 4;
BA_ "UserSigValidity" SG_ 1515 RDC_GST_Byte0 0;
BA_REL_ "GenSigTimeoutTime" BU_SG_REL_ CGW_CCU SG_ 1515 RDC_GST_Byte0 0;
BA_ "NetworkRequest" SG_ 1515 RDC_GST_Byte0 0;
BA_ "NetworkRequestHoldingTime" SG_ 1515 RDC_GST_Byte0 5000;
BA_ "Version" SG_ 1515 RDC_GST_Byte0 "21.02.04";
BA_ "Description" SG_ 1515 RDC_GST_Byte2 "TP Index : 159";
BA_ "UsrSigPurpose" SG_ 1515 RDC_GST_Byte2 4;
BA_ "UserSigValidity" SG_ 1515 RDC_GST_Byte2 0;
BA_REL_ "GenSigTimeoutTime" BU_SG_REL_ CGW_CCU SG_ 1515 RDC_GST_Byte2 0;
BA_ "NetworkRequest" SG_ 1515 RDC_GST_Byte2 0;
BA_ "NetworkRequestHoldingTime" SG_ 1515 RDC_GST_Byte2 5000;
BA_ "Version" SG_ 1515 RDC_GST_Byte2 "21.02.04";
BA_ "Description" SG_ 1515 RDC_GST_Byte3 "TP Index : 159";
BA_ "UsrSigPurpose" SG_ 1515 RDC_GST_Byte3 4;
BA_ "UserSigValidity" SG_ 1515 RDC_GST_Byte3 0;
BA_REL_ "GenSigTimeoutTime" BU_SG_REL_ CGW_CCU SG_ 1515 RDC_GST_Byte3 0;
BA_ "NetworkRequest" SG_ 1515 RDC_GST_Byte3 0;
BA_ "NetworkRequestHoldingTime" SG_ 1515 RDC_GST_Byte3 5000;
BA_ "Version" SG_ 1515 RDC_GST_Byte3 "21.02.04";
BA_ "Description" SG_ 1515 RDC_GST_Byte4 "TP Index : 159";
BA_ "UsrSigPurpose" SG_ 1515 RDC_GST_Byte4 4;
BA_ "UserSigValidity" SG_ 1515 RDC_GST_Byte4 0;
BA_REL_ "GenSigTimeoutTime" BU_SG_REL_ CGW_CCU SG_ 1515 RDC_GST_Byte4 0;
BA_ "NetworkRequest" SG_ 1515 RDC_GST_Byte4 0;
BA_ "NetworkRequestHoldingTime" SG_ 1515 RDC_GST_Byte4 5000;
BA_ "Version" SG_ 1515 RDC_GST_Byte4 "21.02.04";
BA_ "Description" SG_ 1515 RDC_GST_Byte5 "TP Index : 159";
BA_ "UsrSigPurpose" SG_ 1515 RDC_GST_Byte5 4;
BA_ "UserSigValidity" SG_ 1515 RDC_GST_Byte5 0;
BA_REL_ "GenSigTimeoutTime" BU_SG_REL_ CGW_CCU SG_ 1515 RDC_GST_Byte5 0;
BA_ "NetworkRequest" SG_ 1515 RDC_GST_Byte5 0;
BA_ "NetworkRequestHoldingTime" SG_ 1515 RDC_GST_Byte5 5000;
BA_ "Version" SG_ 1515 RDC_GST_Byte5 "21.02.04";
BA_ "Description" SG_ 1515 RDC_GST_Byte6 "TP Index : 159";
BA_ "UsrSigPurpose" SG_ 1515 RDC_GST_Byte6 4;
BA_ "UserSigValidity" SG_ 1515 RDC_GST_Byte6 0;
BA_REL_ "GenSigTimeoutTime" BU_SG_REL_ CGW_CCU SG_ 1515 RDC_GST_Byte6 0;
BA_ "NetworkRequest" SG_ 1515 RDC_GST_Byte6 0;
BA_ "NetworkRequestHoldingTime" SG_ 1515 RDC_GST_Byte6 5000;
BA_ "Version" SG_ 1515 RDC_GST_Byte6 "21.02.04";
BA_ "Description" SG_ 1515 RDC_GST_Byte7 "TP Index : 159";
BA_ "UsrSigPurpose" SG_ 1515 RDC_GST_Byte7 4;
BA_ "UserSigValidity" SG_ 1515 RDC_GST_Byte7 0;
BA_REL_ "GenSigTimeoutTime" BU_SG_REL_ CGW_CCU SG_ 1515 RDC_GST_Byte7 0;
BA_ "NetworkRequest" SG_ 1515 RDC_GST_Byte7 0;
BA_ "NetworkRequestHoldingTime" SG_ 1515 RDC_GST_Byte7 5000;
BA_ "Version" SG_ 1515 RDC_GST_Byte7 "21.02.04";
BA_ "Description" SG_ 1515 RDC_GST_Byte1 "TP Index : 159";
BA_ "UsrSigPurpose" SG_ 1515 RDC_GST_Byte1 4;
BA_ "UserSigValidity" SG_ 1515 RDC_GST_Byte1 0;
BA_REL_ "GenSigTimeoutTime" BU_SG_REL_ CGW_CCU SG_ 1515 RDC_GST_Byte1 0;
BA_ "NetworkRequest" SG_ 1515 RDC_GST_Byte1 0;
BA_ "NetworkRequestHoldingTime" SG_ 1515 RDC_GST_Byte1 5000;
BA_ "Version" SG_ 1515 RDC_GST_Byte1 "21.02.04";
BA_ "GenMsgSendType" BO_ 1003 0;
BA_ "Description" SG_ 1003 PSM_BzrOnRLReq "PSM buzzer on command";
BA_ "GenSigSendType" SG_ 1003 PSM_BzrOnRLReq 4;
BA_ "UserSigValidity" SG_ 1003 PSM_BzrOnRLReq 0;
BA_REL_ "GenSigTimeoutTime" BU_SG_REL_ ATS SG_ 1003 PSM_BzrOnRLReq 1500;
BA_REL_ "GenSigTimeoutTime" BU_SG_REL_ PSM SG_ 1003 PSM_BzrOnRLReq 1500;
BA_ "NetworkRequest" SG_ 1003 PSM_BzrOnRLReq 0;
BA_ "NetworkRequestHoldingTime" SG_ 1003 PSM_BzrOnRLReq 5000;
BA_ "Version" SG_ 1003 PSM_BzrOnRLReq "17.11.00";
BA_ "Description" SG_ 1003 RLPSM_RearModeState "Rear Seat State for One Touch Mode";
BA_ "GenSigSendType" SG_ 1003 RLPSM_RearModeState 4;
BA_ "UserSigValidity" SG_ 1003 RLPSM_RearModeState 0;
BA_REL_ "GenSigTimeoutTime" BU_SG_REL_ ATS SG_ 1003 RLPSM_RearModeState 1500;
BA_REL_ "GenSigTimeoutTime" BU_SG_REL_ PSM SG_ 1003 RLPSM_RearModeState 1500;
BA_REL_ "GenSigTimeoutTime" BU_SG_REL_ RDC SG_ 1003 RLPSM_RearModeState 1500;
BA_REL_ "GenSigTimeoutTime" BU_SG_REL_ CGW_CCU SG_ 1003 RLPSM_RearModeState 1500;
BA_ "NetworkRequest" SG_ 1003 RLPSM_RearModeState 0;
BA_ "NetworkRequestHoldingTime" SG_ 1003 RLPSM_RearModeState 5000;
BA_ "Version" SG_ 1003 RLPSM_RearModeState "21.07.05";
BA_ "GenSigSendType" SG_ 1003 RLPSM_RLStEsyAcsUSMSta 4;
BA_ "UserSigValidity" SG_ 1003 RLPSM_RLStEsyAcsUSMSta 0;
BA_REL_ "GenSigTimeoutTime" BU_SG_REL_ ATS SG_ 1003 RLPSM_RLStEsyAcsUSMSta 1500;
BA_REL_ "GenSigTimeoutTime" BU_SG_REL_ CGW_CCU SG_ 1003 RLPSM_RLStEsyAcsUSMSta 1500;
BA_ "Version" SG_ 1003 RLPSM_RLStEsyAcsUSMSta "19.10.07";
BA_ "Description" SG_ 1003 RLPSM_RLSlidePosition "Rear Left Seat Slide Position";
BA_ "GenSigSendType" SG_ 1003 RLPSM_RLSlidePosition 4;
BA_ "UserSigValidity" SG_ 1003 RLPSM_RLSlidePosition 0;
BA_REL_ "GenSigTimeoutTime" BU_SG_REL_ PSM SG_ 1003 RLPSM_RLSlidePosition 1500;
BA_ "NetworkRequest" SG_ 1003 RLPSM_RLSlidePosition 0;
BA_ "NetworkRequestHoldingTime" SG_ 1003 RLPSM_RLSlidePosition 5000;
BA_ "Version" SG_ 1003 RLPSM_RLSlidePosition "20.03.01";
BA_ "GenSigSendType" SG_ 1003 RLPSM_LimSetSta 4;
BA_ "UserSigValidity" SG_ 1003 RLPSM_LimSetSta 0;
BA_REL_ "GenSigTimeoutTime" BU_SG_REL_ ATS SG_ 1003 RLPSM_LimSetSta 1500;
BA_ "NetworkRequest" SG_ 1003 RLPSM_LimSetSta 0;
BA_ "NetworkRequestHoldingTime" SG_ 1003 RLPSM_LimSetSta 5000;
BA_ "Version" SG_ 1003 RLPSM_LimSetSta "21.04.01";
BA_ "GenMsgSendType" BO_ 2223056129 0;
BA_ "GenMsgCycleTime" BO_ 2223056129 50;
BA_ "GenMsgCycleTimeFast" BO_ 2223056129 0;
BA_ "GenMsgNrOfRepetition" BO_ 2223056129 0;
BA_ "VFrameFormat" BO_ 2223056129 1;
BA_ "Description" SG_ 2223056129 SAS_Crc1Val "The data area for CRC calculation is based on the data length (DLC) of the message DB.

The CRC shall be calculated over the entire data block (excluding the CRC bytes) including the user data, alive counter and Data ID

 

- CRC Polynomial (0x1021) , Initial Value : 0xFFFF, XOR value : 0x0000, Data ID : Message ID + 0xF800 

- The initial value is for CRC calculation and the message should be sent with the calculated result value. 

- The mathematical expression to 16 bit CRC polynomial is given here. G(x) = x16 + x12 + x5 + 1";
BA_ "GenSigStartValue" SG_ 2223056129 SAS_Crc1Val 65535;
BA_ "UserSigValidity" SG_ 2223056129 SAS_Crc1Val 3;
BA_ "RoutingFactor" SG_ 2223056129 SAS_Crc1Val 5;
BA_ "Version" SG_ 2223056129 SAS_Crc1Val "18.11.08";
BA_ "Description" SG_ 2223056129 SAS_AlvCnt1Val "For the first transmission request for a data element the counter shall be initialized with 0 and shall be incremented by 1 for every subsequent send request. 

When the counter reaches the maximum value(0xFF), then it shall restart with 0 for the next send request";
BA_ "UserSigValidity" SG_ 2223056129 SAS_AlvCnt1Val 3;
BA_ "RoutingFactor" SG_ 2223056129 SAS_AlvCnt1Val 5;
BA_ "Version" SG_ 2223056129 SAS_AlvCnt1Val "18.11.08";
BA_ "Description" SG_ 2223056129 SAS_AnglVal "Information regarding the steering wheel angle.  (PH) = (HEX) * 0.1 (0 <  HEX < 7FFFH) or (PH) = (HEX - 65536) * 0.1 (HEX > 7FFFH)";
BA_ "GenSigStartValue" SG_ 2223056129 SAS_AnglVal 32767;
BA_ "UserSigValidity" SG_ 2223056129 SAS_AnglVal 3;
BA_ "RoutingFactor" SG_ 2223056129 SAS_AnglVal 5;
BA_ "Version" SG_ 2223056129 SAS_AnglVal "18.12.08";
BA_ "Description" SG_ 2223056129 SAS_SpdVal "Information regarding the steering wheel rotation speed 

(PH) = (HEX) * 4 (0 ≤ HEX < 254)";
BA_ "GenSigStartValue" SG_ 2223056129 SAS_SpdVal 255;
BA_ "UserSigValidity" SG_ 2223056129 SAS_SpdVal 3;
BA_ "RoutingFactor" SG_ 2223056129 SAS_SpdVal 5;
BA_ "Version" SG_ 2223056129 SAS_SpdVal "18.12.08";
BA_ "Description" SG_ 2223056129 SAS_IntSta "Information regarding the steering angle sensor’s internal state. If SAS_AnglVal value is O.K., SAS_OK flag is set and otherwise SAS_OK flag is cleared. If steering angle sensor has been calibrated, SAS_CAL flag is set and otherwise cleared.

SF1 - SF5 : for internal use only



SAS_OK(=1), SAS_CAL(=1) : SAS_AnglVal(=value), SAS_SpdVal(=value)

SAS_OK(=1), SAS_CAL(=0) : SAS_AnglVal(=7FFFh), SAS_SpdVal(=value)

SAS_OK(=0), SAS_CAL(=1) : SAS_AnglVal(=7FFFh), SAS_SpdVal(=FFh)

SAS_OK(=0), SAS_CAL(=0) : SAS_AnglVal(=7FFFh), SAS_SpdVal(=FFh)



※ If SAS is trimmed, SAS_Trim flag = 1.

If SAS is not trimmed (in this case SAS_OK=0 and SAS_CAL=0), SAS_Trim flag=0.";
BA_ "GenSigStartValue" SG_ 2223056129 SAS_IntSta 14;
BA_ "UserSigValidity" SG_ 2223056129 SAS_IntSta 3;
BA_ "RoutingFactor" SG_ 2223056129 SAS_IntSta 5;
BA_ "Version" SG_ 2223056129 SAS_IntSta "20.08.07";
BA_ "GenMsgSendType" BO_ 2223056130 0;
BA_ "GenMsgCycleTime" BO_ 2223056130 50;
BA_ "GenMsgCycleTimeFast" BO_ 2223056130 0;
BA_ "GenMsgNrOfRepetition" BO_ 2223056130 0;
BA_ "VFrameFormat" BO_ 2223056130 1;
BA_ "GenMsgSendType" BO_ 905 0;
BA_ "Description" SG_ 905 SBCM_RR_Crc1Val "The data area for CRC calculation is based on the data length (DLC) of the message DB.

The CRC shall be calculated over the entire data block (excluding the CRC bytes) including the user data, alive counter and Data ID 

 

- CRC Polynomial (0x1D) , Initial Value : 0x00, XOR value : 0xFF, Data ID Mode : Both, Data ID : Message ID + 0xF800 

- The initial value is for CRC calculation and the message should be sent with the calculated result value. 

The mathematical expression to 8 bit CRC polynomial is given here. G(x) = x8 + x4 + x3 + x2 + 1";
BA_ "GenSigSendType" SG_ 905 SBCM_RR_Crc1Val 4;
BA_ "GenSigStartValue" SG_ 905 SBCM_RR_Crc1Val 255;
BA_ "UserSigValidity" SG_ 905 SBCM_RR_Crc1Val 0;
BA_ "Version" SG_ 905 SBCM_RR_Crc1Val "19.07.06";
BA_ "Description" SG_ 905 RR_CrashUnlockCmd "RearRightCrashUnlockCommand";
BA_ "GenSigSendType" SG_ 905 RR_CrashUnlockCmd 4;
BA_ "UserSigValidity" SG_ 905 RR_CrashUnlockCmd 0;
BA_ "NetworkRequest" SG_ 905 RR_CrashUnlockCmd 0;
BA_ "Version" SG_ 905 RR_CrashUnlockCmd "20.09.00";
BA_ "Description" SG_ 905 SBCM_RR_AlvCnt1Val "For the first transmission request for a data element the counter shall be initialized with 0 and shall be incremented by 1

for every subsequent send request. When the counter reaches the maximum value(0xE), then it shall restart with 0 for the next send request";
BA_ "GenSigSendType" SG_ 905 SBCM_RR_AlvCnt1Val 4;
BA_ "UserSigValidity" SG_ 905 SBCM_RR_AlvCnt1Val 0;
BA_ "Version" SG_ 905 SBCM_RR_AlvCnt1Val "19.07.06";
BA_ "Description" SG_ 905 Warn_RrRtDrSwSta_SBCM "Warning Rear Right Door Switch Status";
BA_ "GenSigSendType" SG_ 905 Warn_RrRtDrSwSta_SBCM 4;
BA_ "UserSigValidity" SG_ 905 Warn_RrRtDrSwSta_SBCM 0;
BA_REL_ "GenSigTimeoutTime" BU_SG_REL_ RWPC SG_ 905 Warn_RrRtDrSwSta_SBCM 1500;
BA_REL_ "GenSigTimeoutTime" BU_SG_REL_ RLPSM SG_ 905 Warn_RrRtDrSwSta_SBCM 1500;
BA_REL_ "GenSigTimeoutTime" BU_SG_REL_ RRPSM SG_ 905 Warn_RrRtDrSwSta_SBCM 1500;
BA_REL_ "GenSigTimeoutTime" BU_SG_REL_ AMP SG_ 905 Warn_RrRtDrSwSta_SBCM 1500;
BA_REL_ "GenSigTimeoutTime" BU_SG_REL_ ATS SG_ 905 Warn_RrRtDrSwSta_SBCM 1500;
BA_ "NetworkRequest" SG_ 905 Warn_RrRtDrSwSta_SBCM 0;
BA_ "Version" SG_ 905 Warn_RrRtDrSwSta_SBCM "19.07.06";
BA_ "Description" SG_ 905 DoorLock_RrRtDrUnLkSta_SBCM "Rear Right Door Unlock Status";
BA_ "GenSigSendType" SG_ 905 DoorLock_RrRtDrUnLkSta_SBCM 4;
BA_ "UserSigValidity" SG_ 905 DoorLock_RrRtDrUnLkSta_SBCM 0;
BA_REL_ "GenSigTimeoutTime" BU_SG_REL_ ATS SG_ 905 DoorLock_RrRtDrUnLkSta_SBCM 1500;
BA_ "NetworkRequest" SG_ 905 DoorLock_RrRtDrUnLkSta_SBCM 0;
BA_ "Version" SG_ 905 DoorLock_RrRtDrUnLkSta_SBCM "19.07.06";
BA_ "Description" SG_ 905 RR_SEAActivated "RearRightSEAActivated";
BA_ "GenSigSendType" SG_ 905 RR_SEAActivated 4;
BA_ "UserSigValidity" SG_ 905 RR_SEAActivated 0;
BA_ "NetworkRequest" SG_ 905 RR_SEAActivated 0;
BA_ "Version" SG_ 905 RR_SEAActivated "19.07.06";
BA_ "Description" SG_ 905 RR_SEAWarn "RearRighrSEAWarning";
BA_ "GenSigSendType" SG_ 905 RR_SEAWarn 4;
BA_ "UserSigValidity" SG_ 905 RR_SEAWarn 0;
BA_REL_ "GenSigTimeoutTime" BU_SG_REL_ AMP SG_ 905 RR_SEAWarn 1500;
BA_ "NetworkRequest" SG_ 905 RR_SEAWarn 0;
BA_ "Version" SG_ 905 RR_SEAWarn "19.07.06";
BA_ "GenSigSendType" SG_ 905 RR_SEWWarn 4;
BA_ "UserSigValidity" SG_ 905 RR_SEWWarn 0;
BA_REL_ "GenSigTimeoutTime" BU_SG_REL_ AMP SG_ 905 RR_SEWWarn 1500;
BA_ "NetworkRequest" SG_ 905 RR_SEWWarn 0;
BA_ "Version" SG_ 905 RR_SEWWarn "20.09.00";
BA_ "GenSigSendType" SG_ 905 RR_ReleaseWarn 4;
BA_ "UserSigValidity" SG_ 905 RR_ReleaseWarn 0;
BA_ "NetworkRequest" SG_ 905 RR_ReleaseWarn 0;
BA_ "NetworkRequestHoldingTime" SG_ 905 RR_ReleaseWarn 5000;
BA_ "Version" SG_ 905 RR_ReleaseWarn "20.09.00";
BA_ "GenSigSendType" SG_ 905 RR_SWFailAlarm 4;
BA_ "UserSigValidity" SG_ 905 RR_SWFailAlarm 0;
BA_ "NetworkRequest" SG_ 905 RR_SWFailAlarm 0;
BA_ "NetworkRequestHoldingTime" SG_ 905 RR_SWFailAlarm 5000;
BA_ "Version" SG_ 905 RR_SWFailAlarm "20.09.00";
BA_ "GenSigSendType" SG_ 905 RR_ChildLock_ActnFlSta 4;
BA_ "UserSigValidity" SG_ 905 RR_ChildLock_ActnFlSta 0;
BA_ "NetworkRequest" SG_ 905 RR_ChildLock_ActnFlSta 0;
BA_ "NetworkRequestHoldingTime" SG_ 905 RR_ChildLock_ActnFlSta 5000;
BA_ "Version" SG_ 905 RR_ChildLock_ActnFlSta "19.11.05";
BA_ "GenSigSendType" SG_ 905 RR_MRActivationAlarm 4;
BA_ "UserSigValidity" SG_ 905 RR_MRActivationAlarm 0;
BA_ "NetworkRequest" SG_ 905 RR_MRActivationAlarm 0;
BA_ "NetworkRequestHoldingTime" SG_ 905 RR_MRActivationAlarm 5000;
BA_ "Version" SG_ 905 RR_MRActivationAlarm "19.11.05";
BA_ "GenSigSendType" SG_ 905 RR_ChildLock_Status 4;
BA_ "UserSigValidity" SG_ 905 RR_ChildLock_Status 0;
BA_ "NetworkRequest" SG_ 905 RR_ChildLock_Status 0;
BA_ "NetworkRequestHoldingTime" SG_ 905 RR_ChildLock_Status 5000;
BA_ "Version" SG_ 905 RR_ChildLock_Status "21.03.01";
BA_ "GenSigSendType" SG_ 905 USM_RRGhostDoorSta 4;
BA_ "UserSigValidity" SG_ 905 USM_RRGhostDoorSta 0;
BA_ "NetworkRequest" SG_ 905 USM_RRGhostDoorSta 0;
BA_ "NetworkRequestHoldingTime" SG_ 905 USM_RRGhostDoorSta 5000;
BA_ "Version" SG_ 905 USM_RRGhostDoorSta "21.03.11";
BA_ "GenSigSendType" SG_ 905 DoorLock_PDSLkSwSta_RR 4;
BA_ "UserSigValidity" SG_ 905 DoorLock_PDSLkSwSta_RR 0;
BA_REL_ "GenSigTimeoutTime" BU_SG_REL_ AMP SG_ 905 DoorLock_PDSLkSwSta_RR 1500;
BA_ "NetworkRequest" SG_ 905 DoorLock_PDSLkSwSta_RR 0;
BA_ "Version" SG_ 905 DoorLock_PDSLkSwSta_RR "19.12.00";
BA_ "GenSigSendType" SG_ 905 PDS_TypeOption_RR 4;
BA_ "UserSigValidity" SG_ 905 PDS_TypeOption_RR 0;
BA_ "NetworkRequest" SG_ 905 PDS_TypeOption_RR 0;
BA_ "Version" SG_ 905 PDS_TypeOption_RR "19.12.00";
BA_ "GenSigSendType" SG_ 905 SBCM_RrRrClsSwSta 4;
BA_ "UserSigValidity" SG_ 905 SBCM_RrRrClsSwSta 0;
BA_ "NetworkRequest" SG_ 905 SBCM_RrRrClsSwSta 0;
BA_ "NetworkRequestHoldingTime" SG_ 905 SBCM_RrRrClsSwSta 5000;
BA_ "Version" SG_ 905 SBCM_RrRrClsSwSta "21.07.07";
BA_ "GenSigSendType" SG_ 905 RRDoorPushAlarm 4;
BA_ "UserSigValidity" SG_ 905 RRDoorPushAlarm 0;
BA_ "NetworkRequest" SG_ 905 RRDoorPushAlarm 0;
BA_ "NetworkRequestHoldingTime" SG_ 905 RRDoorPushAlarm 5000;
BA_ "Version" SG_ 905 RRDoorPushAlarm "20.09.00";
VAL_ 911 ATS_RearLock_Set 0 "Unlock" 1 "LockON" 2 "Reserved" 3 "Invalid" ;
VAL_ 911 ATS_RrCurtainBtn 0 "Default" 1 "Open ON" 2 "Close ON" 3 "Invaild" ;
VAL_ 911 ATS_RrDrCurtainBtn 0 "Default" 1 "Open ON" 2 "Close ON" 3 "Invalid" ;
VAL_ 911 ATS_RLDrCurtainBtn 0 "Default" 1 "Open ON" 2 "Close ON" 3 "Invaild" ;
VAL_ 911 ATS_RRSunBlind 0 "Default" 1 "Open ON" 2 "Close ON" 3 "Stop ON" 4 "Reserved" 5 "Reserved" 6 "Reserved" 7 "Reserved" 8 "Reserved" 9 "Reserved" 10 "Reserved" 11 "Reserved" 12 "Reserved" 13 "Reserved" 14 "Reserved" 15 "Invalid" ;
VAL_ 911 ATS_FCS_LockTrayIniPwSet 0 "Default (Initial Value)" 1 "Initial Pw Set" 2 "reserved" 3 "Invaild" ;
VAL_ 911 ATS_FCS_LockTrayKeyPadNo 0 "0" 1 "1" 2 "2" 3 "3" 4 "4" 5 "5" 6 "6" 7 "7" 8 "8" 9 "9" 10 "reserved" 11 "reserved" 12 "reserved" 13 "reserved" 14 "reserved" 15 "Invalid" ;
VAL_ 911 ATS_FCS_LockTrayNoDel 0 "Default (Initial Value)" 1 "Number Delete" 2 "reserved" 3 "Invaild" ;
VAL_ 911 ATS_FCS_LockTrayNoClr 0 "Default (Initial Value)" 1 "Number Clear" 2 "reserved" 3 "Invaild" ;
VAL_ 911 ATS_FCS_LockTrayPwChange 0 "Default (Initial Value)" 1 "Password Change" 2 "reserved" 3 "Invaild" ;
VAL_ 911 ATS_FCS_LockTrayPwReset 0 "Default (Initial Value)" 1 "Password Reset" 2 "reserved" 3 "Invaild" ;
VAL_ 911 ATS_FCS_LockTrayCancel 0 "Default (Initial Value)" 1 "Cancel" 2 "reserved" 3 "Invaild" ;
VAL_ 1007 ATS_LEDBgtnsUpDn 0 "Reserved" 1 "Brightness Up" 2 "Brightness Down" 3 "Invalid" ;
VAL_ 1007 ATS_FrMoodOn_Req 0 "Default" 1 "Off" 2 "On" 3 "Invalid" ;
VAL_ 1007 ATS_DoorOn_Req 0 "Default" 1 "Off" 2 "On" 3 "Invalid" ;
VAL_ 1007 ATS_RrMapLftOn_Req 0 "Default" 1 "Off" 2 "On" 3 "Invalid" ;
VAL_ 1007 ATS_RrMapRtOn_Req 0 "Default" 1 "Off" 2 "On" 3 "Invalid" ;
VAL_ 1007 ATS_RrRoomOn_Req 0 "Default" 1 "Off" 2 "On" 3 "Invalid" ;
VAL_ 1007 ATS_LEDClrUpDn 0 "Reserved" 1 "Color Up" 2 "Color Down" 3 "Invalid" ;
VAL_ 1007 ATS_RrMoodOn_Req 0 "Default" 1 "Off" 2 "On" 3 "Invalid" ;
VAL_ 1007 ATS_LEDClr_Set 0 "Color 1Step" 1 "Color 2Step" 2 "Color 3Step" 3 "Not Used" 4 "Not Used" 5 "Not Used" 6 "Invalid" 7 "System Fail" ;
VAL_ 1007 ATS_LEDBgtns_Set 0 "Brightness 1Step" 1 "Brightness 2Step" 2 "Brightness 3Step" 3 "Not Used" 4 "Not Used" 5 "Not Used" 6 "Invalid" 7 "System Fail" ;
VAL_ 1007 ATS_FrMapLftOn_Req 0 "Default" 1 "Off" 2 "On" 3 "Invalid" ;
VAL_ 1007 ATS_FrMapRtOn_Req 0 "Default" 1 "Off" 2 "On" 3 "Invalid" ;
VAL_ 1007 ATS_FrRoomOn_Req 0 "Default" 1 "Off" 2 "On" 3 "Invalid" ;
VAL_ 992 BAlarm_BglrAlrmCurrentSta 0 "Off" 1 "DisArm" 2 "Arm" 3 "PreArm" 4 "ArmWait" 5 "ArmHold(Trunk)" 6 "ReArm" 7 "AutoLockTimer1" 8 "AutoLockTimer2" 9 "Alarm" 10 "Default" 11 "AutoLockTimer3(Tailgate)" 12 "Reserved" 13 "Reserved" 14 "Not Used" 15 "Error Indicator" ;
VAL_ 992 BAlarm_BglrAlrmSta 0 "DIS-,PRE-,AUTOLOCKTIMER1,2,3(TG)" 1 "ARM,-WAIT,RE-,ALARM,-HD(Trunk)" 2 "Not Used" 3 "Error Indicator" ;
VAL_ 992 BAlarm_PncAlrmSta 0 "Off" 1 "On (Panic Alarm ON)" 2 "Not Used" 3 "Error Indicator" ;
VAL_ 992 BAlarm_BrglrHrnRlySta 0 "Off" 1 "On" 2 "Not Used" 3 "Error Indicator" ;
VAL_ 992 BAlarm_ROABglrAlrmSta 0 "DISARM,PREARM,AUTOLOCKTIMER1,AUTOLOCKTIMER2,AUTOLOCKTIMER3" 1 "ARMWAIT,ARMHOLD" 2 "ARM,REARM" 3 "ALARM" 4 "Reserved" 5 "Reserved" 6 "Reserved" 7 "Invalid" ;
VAL_ 992 BCM_KeyInSta 0 "Off (Key removed)" 1 "On (Key inserted)" 2 "Not Used" 3 "Error Indicator" ;
VAL_ 992 BCM_AccInSta 0 "Acc Off" 1 "Acc On" 2 "Not Used" 3 "Error Indicator" ;
VAL_ 992 BCM_Ign1InSta 0 "IGN1 Off" 1 "IGN1 On" 2 "Not Used" 3 "Error Indicator" ;
VAL_ 992 BCM_Ign2InSta 0 "IGN2 Off" 1 "IGN2 On" 2 "Not Used" 3 "Error Indicator" ;
VAL_ 992 BCM_IgnSwSta 0 "KeyOff" 1 "KeyIn" 2 "Acc" 3 "Ign" 4 "St" 5 "Reseved" 6 "Not Used" 7 "Error Indicator" ;
VAL_ 916 USM_IBU_AutoDrUnLkReq 0 "Default" 1 "Off" 2 "Key Out On (AllDoors)" 3 "Shift Lever On (AllDoors)" 4 "Override" 5 "Invalid" 6 "Key Out On (Driver Door)" 7 "Shift Lever On (Driver Door)" ;
VAL_ 916 IBU_TwoTrnUnLkOptTyp 0 "Off" 1 "On" 2 "Not Used" 3 "Error Indicator" ;
VAL_ 916 USM_IBU_TwoTrnUnLkCurrentSta 0 "Default" 1 "Ttunlock Off" 2 "Ttunlock On" 3 "Invalid" ;
VAL_ 916 DoorLock_ADrLOptInfo 0 "Non-SMK & AT" 1 "Non-SMK & MT" 2 "SMK & AT" 3 "SMK & MT" 4 "Not used" 5 "Not used" 6 "Not used" 7 "Invalid" ;
VAL_ 916 USM_IBU_RemoteWDWCurrentSta 0 "Default" 1 "Off(Disable)" 2 "On(Enable)" 3 "Invalid" ;
VAL_ 916 IBU_VitalityCurtainSta 0 "Default" 1 "Off" 2 "On" 3 "Invalid" ;
VAL_ 916 IBU_DelightCurtainSta 0 "Default" 1 "Off" 2 "On" 3 "Invalid" ;
VAL_ 916 IBU_CareCurtainSta 0 "Default" 1 "Off" 2 "On" 3 "Invalid" ;
VAL_ 916 IBU_ComfortCurtainSta 0 "Default" 1 "Off" 2 "On" 3 "Invalid" ;
VAL_ 916 USM_IBU_AutoDrLkReq2 0 "Default" 1 "Off" 2 "Vehicle Speed On(15km)" 3 "Vehicle Speed On (15km) and Shift Lever On" 4 "Invalid" ;
VAL_ 916 USM_1stRrStRmndSta 0 "Default" 1 "Off(Disable)" 2 "On(Enable)" 3 "Invalid" 4 "Reserved" 5 "Reseved" 6 "Not Used" 7 "Error Indicator" ;
VAL_ 2470763265 USM_AdasDSWSetReq 0 "Default" 1 "Disable" 2 "Enable" 3 "Invalid" ;
VAL_ 2382594817 DATC_SyncDis 0 "SYNC Off" 1 "SYNC On" 2 "Not used" 3 "Error Indicator" ;
VAL_ 2382594817 DATC_OpSta 0 "DATC Off (Power Down)" 1 "DATC Normal" 2 "DATC System Off (Blower Off)" 3 "DATC Self Diagnosis" 4 "Not used" 5 "Not used" 6 "Not used" 7 "Error Indicator" ;
VAL_ 2382594817 DATC_FrDfgSta 0 "Off" 1 "On" 2 "Not used" 3 "Error Indicator" ;
VAL_ 2382594817 DATC_SmrtVntDis 0 "Off" 1 "Smart Ventilation" 2 "Smart CO2" 3 "Error Indicator" ;
VAL_ 2382594817 DATC_AutoDfgBlnkDis 0 "AutoDefogBlink Non Request" 1 "AutoDefogBlink Request" 2 "Not used" 3 "Error Indicator" ;
VAL_ 2382594817 DATC_AutoDfgSysOffDis 0 "'ADS OFF' display Off" 1 "'ADS OFF' display On" 2 "Not Used(Non-ADS)" 3 "Error Indicator" ;
VAL_ 2382594817 DATC_ArClnIND 0 "Default" 1 "OFF" 2 "ON" 3 "Error Indicator" ;
VAL_ 907 FPM2AVN_H2PV 65535 "H2PV value to AVN" ;
VAL_ 2563126785 AMP_HFVolumeStep 0 "0x0x0~0xFD:HF Call Volume" 253 "0x0x0~0xFD:HF Call Volume" 254 "Request amp supported HF Set" 255 "Invalid" ;
VAL_ 2563126785 DVRS_BeepVolumeStep 0 "0x0x0~0xFE:DVRS Beep Volume" 254 "0x0x0~0xFE:DVRS Beep Volume" 255 "Invalid" ;
VAL_ 2563126785 DVRS_BeepFrequency 20 "0x0x14~0x4E20:Valid for Hz step" 20000 "0x0x14~0x4E20:Valid for Hz step" 65535 "Invalid" ;
VAL_ 2563126785 AMP_SiriVolumeStep 0 "0x0x0~0xFD:Siri Volume" 253 "0x0x0~0xFD:Siri Volume" 254 "Request AMP Supported Siri Set" 255 "Invalid" ;
VAL_ 2563126785 DVRS_Beep_OutputCh_Select 65535 "Invaild" ;
VAL_ 2323817729 C_RLBackSoftNValueSet_EC 0 "Default" 1 "Off" 2 "Low" 3 "Mid" 4 "High" 5 "Reserved" 6 "Reserved" 7 "Invalid" ;
VAL_ 2323817729 C_RRAirSptStrNValueSet_EC 0 "Default" 1 "Weak" 2 "Normal" 3 "Strong" 4 "Reserved" 5 "Reserved" 6 "Reserved" 7 "Invalid" ;
VAL_ 2323817729 C_RRAirSptTimeNValueSet_EC 0 "Default" 1 "Short" 2 "Normal" 3 "Long" 4 "Reserved" 5 "Reserved" 6 "Reserved" 7 "Invalid" ;
VAL_ 2323817729 C_RRBackSoftNValueSet_EC 0 "Default" 1 "Off" 2 "Low" 3 "Mid" 4 "High" 5 "Reserved" 6 "Reserved" 7 "Invalid" ;
VAL_ 2323817729 C_RROneTchNvalueSet_EC 0 "Default" 1 "Off" 2 "Return" 3 "Relax" 4 "AV" 5 "Read" 6 "Reserved" 7 "Invalid" ;
VAL_ 2323817729 C_RLOneTchNValueSet_EC 0 "Default" 1 "Off" 2 "Return" 3 "Relax" 4 "Reserved" 5 "Reserved" 6 "Reserved" 7 "Invalid" ;
VAL_ 2323817729 C_RRAirSptModeNValueSet_EC 0 "Default" 1 "Mode 1" 2 "Mode 2" 3 "Mode 3" 4 "Mode 4" 5 "Mode 5" 6 "Reserved" 7 "Invalid" ;
VAL_ 2449770241 C_AstRclBwdSw_HU 0 "Default" 1 "Off" 2 "On" 3 "Invalid" ;
VAL_ 2449770241 C_AstHeightUpSw_HU 0 "Default" 1 "Off" 2 "On" 3 "Invalid" ;
VAL_ 2449770241 C_AstTiltDnSw_HU 0 "Default" 1 "Off" 2 "On" 3 "Invalid" ;
VAL_ 2449770241 C_AstTiltUpSw_HU 0 "Default" 1 "Off" 2 "On" 3 "Invalid" ;
VAL_ 2449770241 C_AstLumbarDefSw_HU 0 "Default" 1 "Off" 2 "On" 3 "Invalid" ;
VAL_ 2449770241 C_AstLumbarLowSw_HU 0 "Default" 1 "Off" 2 "On" 3 "Invalid" ;
VAL_ 2449770241 C_AstRclFwdSw_HU 0 "Default" 1 "Off" 2 "On" 3 "Invalid" ;
VAL_ 2449770241 C_AstLumbarMidSw_HU 0 "Default" 1 "Off" 2 "On" 3 "Invalid" ;
VAL_ 2449770241 C_AstLumbarUpSw_HU 0 "Default" 1 "Off" 2 "On" 3 "Invalid" ;
VAL_ 2449770241 C_RRSlideFwdSw_HU 0 "Default" 1 "Off" 2 "On" 3 "Invalid" ;
VAL_ 2449770241 C_RRSlideBwdSw_HU 0 "Default" 1 "Off" 2 "On" 3 "Invalid" ;
VAL_ 2449770241 C_RLSlideFwdSw_HU 0 "Default" 1 "Off" 2 "On" 3 "Invalid" ;
VAL_ 2449770241 C_RLSlideBwdSw_HU 0 "Default" 1 "Off" 2 "On" 3 "Invalid" ;
VAL_ 2449770241 C_AstSlideBwdSw_HU 0 "Default" 1 "Off" 2 "On" 3 "Invalid" ;
VAL_ 2449770241 C_AstRlxNValueSet 0 "Default" 1 "Off" 2 "Return" 3 "Relax" 4 "Reserved" 5 "Reserved" 7 "Invalid" ;
VAL_ 2449770241 C_AstSlideFwdSw_HU 0 "Default" 1 "Off" 2 "On" 3 "Invalid" ;
VAL_ 2449770241 C_AstHeightDnSw_HU 0 "Default" 1 "Off" 2 "On" 3 "Invalid" ;
VAL_ 2479157505 HU_TeleVehicleStatusReq 0 "Do not Request" 1 "Request" 2 "reserved" 3 "Invalid" ;
VAL_ 2479157505 HU_Background 0 "Default" 1 "Day" 2 "Night" 3 "Reserved" 4 "Reserved" 5 "Reserved" 6 "Reserved" 7 "Invalid" ;
VAL_ 2479157505 ccIC_HUD_PbackSta 0 "Stop" 1 "Play 1" 2 "Play 2" 3 "Health Care IMS" 4 "Profile 1" 5 "Profile 2" 6 "Guest" 7 "Invalid" ;
VAL_ 2479157505 HU_BackgroundFadeInOut 0 "0x0x0~0x3E8:0.0~100.0%" 1000 "0x0x0~0x3E8:0.0~100.0%" 1001 "Reserved" 1002 "Reserved" 1003 "Reserved" 1004 "Reserved" 1005 "Reserved" 1006 "Reserved" 1007 "Reserved" 1008 "Reserved" 1009 "Reserved" 1010 "Reserved" 1011 "Reserved" 1012 "Reserved" 1013 "Reserved" 1014 "Reserved" 1015 "Reserved" 1016 "Reserved" 1017 "Reserved" 1018 "Reserved" 1019 "Reserved" 1020 "Reserved" 1021 "Reserved" 1022 "Default" 1023 "Invalid" ;
VAL_ 2479157505 HU_Background_Time_Info 0 "Default" 1 "Time_01" 2 "Time_02" 3 "Time_03" 4 "Time_04" 5 "Time_05" 6 "Time_06" 7 "Invalid" ;
VAL_ 2462366209 PROSHORT_V2_3_Offset 0 "0x0x0~0x1FFE:Distance" 8190 "0x0x0~0x1FFE:Distance" 8191 "Invalid" ;
VAL_ 2462366209 PROSHORT_V2_3_PathIndex 0 "Unknown" 1 "Reserved" 2 "Reserved" 3 "Reserved" 4 "Reserved" 5 "Reserved" 6 "Reserved" 7 "Reserved" 63 "Invalid" 8 "General Path Index" 9 "General Path Index" 10 "General Path Index" 11 "General Path Index" 12 "General Path Index" 13 "General Path Index" 14 "General Path Index" 15 "General Path Index" 16 "General Path Index" 17 "General Path Index" 18 "General Path Index" 19 "General Path Index" 20 "General Path Index" 21 "General Path Index" 22 "General Path Index" 23 "General Path Index" 24 "General Path Index" 25 "General Path Index" 26 "General Path Index" 27 "General Path Index" 28 "General Path Index" 29 "General Path Index" 30 "General Path Index" 31 "General Path Index" 32 "General Path Index" 33 "General Path Index" 34 "General Path Index" 35 "General Path Index" 36 "General Path Index" 37 "General Path Index" 38 "General Path Index" 39 "General Path Index" 40 "General Path Index" 41 "General Path Index" 42 "General Path Index" 43 "General Path Index" 44 "General Path Index" 45 "General Path Index" 46 "General Path Index" 47 "General Path Index" 48 "General Path Index" 49 "General Path Index" 50 "General Path Index" 51 "General Path Index" 52 "General Path Index" 53 "General Path Index" 54 "General Path Index" 55 "General Path Index" 56 "General Path Index" 57 "General Path Index" 58 "General Path Index" 59 "General Path Index" 60 "General Path Index" 61 "General Path Index" 62 "General Path Index" ;
VAL_ 2462366209 PROSHORT_V2_3_Distance 0 "0x0x0~0x3FE:Distance" 1022 "0x0x0~0x3FE:Distance" 1023 "Invalid" ;
VAL_ 2462366209 PROSHORT_V2_3_Value0 0 "0x0x0~0x3FE:Profile Vaue at Offset" 1022 "0x0x0~0x3FE:Profile Vaue at Offset" 1023 "Invalid" ;
VAL_ 2462366209 PROSHORT_V2_3_Value1 0 "0x0x0~0x3FE:Profile value at Offset+Distance1" 1022 "0x0x0~0x3FE:Profile value at Offset+Distance1" 1023 "Invalid" ;
VAL_ 2462366209 PROSHORT_V2_3_ProfileType 0 "Unknown" 1 "Curvature" 16 "Alert Information Section" 17 "Alert Information Section 2" 18 "Reserved for system specific types" 19 "Reserved for system specific types" 20 "Reserved for system specific types" 21 "Reserved for system specific types" 22 "Reserved for system specific types" 23 "Reserved for system specific types" 24 "Reserved for system specific types" 25 "Reserved for system specific types" 26 "Reserved for system specific types" 27 "Reserved for system specific types" 28 "Reserved for system specific types" 29 "Reserved for system specific types" 30 "Reserved for system specific types" 31 "Invalid" 2 "Route Number types" 3 "Slope(step)" 4 "Slope(Linear)" 5 "Road Accessibility" 6 "Road condition" 7 "Variable Speed Sign Position" 8 "Heading Change" 9 "Reserved for standard type" 10 "Reserved for standard type" 11 "Reserved for standard type" 12 "Reserved for standard type" 13 "Reserved for standard type" 14 "Reserved for standard type" 15 "Reserved for standard type" ;
VAL_ 2462366209 PROSHORT_V2_3_CyclicCounter 0 "Cyclic Counter" 1 "Cyclic Counter" 2 "Cyclic Counter" 3 "Cyclic Counter" 4 "Reserved" 5 "Reserved" 6 "Reserved" 7 "Invalid" ;
VAL_ 2462366209 PROSHORT_V2_3_Accuracy 0 "High Accuracy_1" 1 "High Accuracy_2" 2 "Middle Accuracy" 3 "Low Accuracy" 4 "Unknown" 5 "Unknown" 6 "Unknown" 7 "Invalid" ;
VAL_ 2458168065 CF_AVN_CluWelcomeSnd 0 "Default" 1 "Off" 2 "On" 3 "Invalid" ;
VAL_ 2458168065 CF_AVN_CluTransmissionDisp 0 "Default" 1 "Off" 2 "On" 3 "Invalid" ;
VAL_ 2458168065 CF_AVN_CluWiperLight 0 "Default" 1 "Off" 2 "On" 3 "Invalid" ;
VAL_ 2458168065 CF_AVN_CluRoadInfoGuide 0 "Default" 1 "Off" 2 "On" 3 "Invalid" ;
VAL_ 2458168065 CF_AVN_CluUserSettingPeriod 0 "0~99month" 1 "0~99month" 2 "0~99month" 3 "0~99month" 4 "0~99month" 5 "0~99month" 6 "0~99month" 7 "0~99month" 8 "0~99month" 9 "0~99month" 10 "0~99month" 11 "0~99month" 12 "0~99month" 13 "0~99month" 14 "0~99month" 15 "0~99month" 16 "0~99month" 17 "0~99month" 18 "0~99month" 19 "0~99month" 20 "0~99month" 21 "0~99month" 22 "0~99month" 23 "0~99month" 24 "0~99month" 25 "0~99month" 26 "0~99month" 27 "0~99month" 28 "0~99month" 29 "0~99month" 30 "0~99month" 31 "0~99month" 32 "0~99month" 33 "0~99month" 34 "0~99month" 35 "0~99month" 36 "0~99month" 37 "0~99month" 38 "0~99month" 39 "0~99month" 40 "0~99month" 41 "0~99month" 42 "0~99month" 43 "0~99month" 44 "0~99month" 45 "0~99month" 46 "0~99month" 47 "0~99month" 48 "0~99month" 49 "0~99month" 50 "0~99month" 51 "0~99month" 52 "0~99month" 53 "0~99month" 54 "0~99month" 55 "0~99month" 56 "0~99month" 57 "0~99month" 58 "0~99month" 59 "0~99month" 60 "0~99month" 61 "0~99month" 62 "0~99month" 63 "0~99month" 64 "0~99month" 65 "0~99month" 66 "0~99month" 67 "0~99month" 68 "0~99month" 69 "0~99month" 70 "0~99month" 71 "0~99month" 72 "0~99month" 73 "0~99month" 74 "0~99month" 75 "0~99month" 76 "0~99month" 77 "0~99month" 78 "0~99month" 79 "0~99month" 80 "0~99month" 81 "0~99month" 82 "0~99month" 83 "0~99month" 84 "0~99month" 85 "0~99month" 86 "0~99month" 87 "0~99month" 88 "0~99month" 89 "0~99month" 90 "0~99month" 91 "0~99month" 92 "0~99month" 93 "0~99month" 94 "0~99month" 95 "0~99month" 96 "0~99month" 97 "0~99month" 98 "0~99month" 99 "0~99month" 100 "Reserved" 101 "Reserved" 102 "Reserved" 103 "Reserved" 104 "Reserved" 105 "Reserved" 106 "Reserved" 107 "Reserved" 108 "Reserved" 109 "Reserved" 110 "Reserved" 111 "Reserved" 112 "Reserved" 113 "Reserved" 114 "Reserved" 115 "Reserved" 116 "Reserved" 117 "Reserved" 118 "Reserved" 119 "Reserved" 120 "Reserved" 121 "Reserved" 122 "Reserved" 123 "Reserved" 124 "Reserved" 125 "Reserved" 126 "Reserved" 127 "Invalid" ;
VAL_ 2458168065 CF_AVN_CluAutoInitFuelEconomy 0 "Default" 1 "Off" 2 "Driving" 3 "Refuel" 4 "Reserved" 5 "Reserved" 6 "Reserved" 7 "Invalid" ;
VAL_ 2458168065 CF_AVN_CluSubspeedOdometerDisp 0 "Default" 1 "Off" 2 "On" 3 "Invalid" ;
VAL_ 2458168065 CF_AVN_CluFuelEconUnit_mi 0 "Default" 1 "US gallon" 2 "UK gallon" 3 "Reserved" ;
VAL_ 2458168065 CF_AVN_CluFuelEconUnit_km 0 "Default" 1 "km_L" 2 "L_100km" 3 "Reserved" ;
VAL_ 2458168065 CF_AVN_CluUserSettingDistance 0 "0x0x0~0x1869F:0~9999km_mi" 99999 "0x0x0~0x1869F:0~9999km_mi" 131071 "Invalid" ;
VAL_ 2458168065 CF_AVN_CluRheostatLvl 0 "Reserved" 1 "Step 1" 2 "Step 2" 3 "Step 3" 4 "Step 4" 5 "Step 5" 6 "Step 6" 7 "Step 7" 8 "Step 8" 9 "Step 9" 10 "Step 10" 11 "Step 11" 12 "Step 12" 13 "Step 13" 14 "Step 14" 15 "Step 15" 16 "Step 16" 17 "Step 17" 18 "Step 18" 19 "Step 19" 20 "Step 20(Reset Value)" 21 "Step 21(Detent)" 22 "Reserved" 23 "Reserved" 24 "Reserved" 25 "Reserved" 26 "Reserved" 27 "Reserved" 28 "Reserved" 29 "Reserved" 30 "Reserved" 31 "Invalid" ;
VAL_ 2458168065 CF_AVN_CluVoiceVolume 0 "Default" 1 "Level0" 2 "Level1" 3 "Level2" 4 "Level3" 5 "Reserved" 6 "Reserved" 7 "Invalid" ;
VAL_ 2458168065 CF_AVN_EVReset 0 "Default" 1 "USM Reset" 2 "Reserved" 3 "Invalid" ;
VAL_ 2458168065 CF_AVN_UnitReset 0 "Default" 1 "Unit Reset" 2 "Reserved" 3 "Invalid" ;
VAL_ 2458168065 CF_AVN_IcyRoadWarn 0 "Default" 1 "Off" 2 "On" 3 "Invalid" ;
VAL_ 2458168065 CF_AVN_CluServiceReminderReset 0 "Default" 1 "Service Reminder Reset" 2 "Reserved" 3 "Invalid" ;
VAL_ 2458168065 CF_AVN_CluUSMReset 0 "Default" 1 "USM Reset" 2 "Reserved" 3 "Invalid" ;
VAL_ 2458168065 CF_AVN_CluServiceReminderSet 0 "Default" 1 "Off" 2 "On" 3 "Invalid" ;
VAL_ 2323817217 CF_AVN_HtBlcRLNValueSet 0 "Default" 1 "Normal" 2 "Back 1" 3 "Back 2" 4 "Back 3" 5 "Cush 1" 6 "Cush 2" 7 "Cush 3" 8 "Reserved" 9 "Reserved" 10 "Reserved" 11 "Reserved" 12 "Reserved" 13 "Reserved" 14 "Reserved" 15 "Invalid" ;
VAL_ 2323817217 CF_AVN_BRAKE_PedalfeelNValueSet2 0 "Default" 1 "Normal" 2 "Sport" 3 "Chauffeur" 4 "Reserved" 5 "Reserved" 6 "Reserved" 7 "Invalid" ;
VAL_ 2323817217 CF_AVN_HtBlcRRNValueSet 0 "Default" 1 "Normal" 2 "Back 1" 3 "Back 2" 4 "Back 3" 5 "Cush 1" 6 "Cush 2" 7 "Cush 3" 8 "Reserved" 9 "Reserved" 10 "Reserved" 11 "Reserved" 12 "Reserved" 13 "Reserved" 14 "Reserved" 15 "Invalid" ;
VAL_ 2323817217 CF_AVN_RemoteWDWNValueSet 0 "Default" 1 "Disable (Off)" 2 "Enable (On)" 3 "Invalid" ;
VAL_ 2323817217 CF_AVN_ADrLNValueSet2 0 "Default" 1 "Off" 2 "Vehicle Seed On(15km/h)" 3 "Vehicle Speed On and Shift Lever On" 4 "Invalid" 5 "Reserved" 6 "Reserved" 7 "Reserved" ;
VAL_ 2323817217 CF_AVN_PCA_RrEquipNvalueSet 0 "Default" 1 "Off" 2 "On" 3 "Invalid(Gray)" ;
VAL_ 902 PSM_DrvStEsyAcsUSMSta 0 "Default Value" 1 "Off (Disable)" 2 "50mmOn (Enable)" 3 "75mmOn (Enable)" 4 "Reserved" 5 "Reserved" 6 "Reserved" 7 "Invalid" ;
VAL_ 902 SmrtIMS_StatureRspVal 0 "Default" 1 "Less than 147.5cm" 2 "147.5~152.4cm" 3 "152.5~157.4cm" 4 "157.5~162.4cm" 5 "162.5~167.4cm" 6 "167.5~172.4cm" 7 "172.5~177.4cm" 8 "177.5~182.4cm" 9 "182.5~187.4cm" 10 "187.5~192.4cm" 11 "192.5~197.4cm" 12 "More than 197.5cm" 13 "Reserved" 14 "Reserved" 15 "Invalid" ;
VAL_ 902 SmrtIMS_SeatedHghtRspVal 0 "Default" 1 "Tall" 2 "Middle" 3 "Short" 4 "Reserved" 5 "Reserved" 6 "Reserved" 7 "Reserved" 8 "Reserved" 9 "Reserved" 10 "Reserved" 11 "Reserved" 12 "Reserved" 13 "Reserved" 14 "Reserved" 15 "Invalid" ;
VAL_ 902 SmrtIMS_WghtRspVal 0 "Default" 1 "Under 49.4kg" 2 "49.5~59.4kg" 3 "59.5~69.4kg" 4 "69.5~79.4kg" 5 "79.5~89.4kg" 6 "89.5~99.4kg" 7 "99.5~109.4kg" 8 "109.5~119.4kg" 9 "More than119.5kg" 10 "Reserved" 11 "Reserved" 12 "Reserved" 13 "Reserved" 14 "Reserved" 15 "Invalid" ;
VAL_ 902 SmartIMS_DisReq 0 "Stop" 1 "Moving(recommend position)" 2 "Moving(manual switch, IMS)" 3 "Current Position Analysis" 4 "Move to setting page" 5 "Reserved" 6 "Reserved" 7 "Invalid" ;
VAL_ 902 SmrtIMS_ExitSta 0 "normal" 1 "not IGN" 2 "not P or over 3km/h" 3 "cranking" 4 "seat moving" 5 "PSM is not initialized" 6 "low voltage" 7 "reserved" ;
VAL_ 902 PSM_IMSOptTyp 0 "Default" 1 "IMS Option" 2 "IMS&Smart IMS Option" 3 "Error Indicator" ;
VAL_ 903 PSM_DrvStSldFwdDis 0 "default" 1 "off" 2 "on" 3 "invalid" ;
VAL_ 903 PSM_DrvStTiltDnDis 0 "default" 1 "off" 2 "on" 3 "invalid" ;
VAL_ 903 PSM_DrvStHghtUpDis 0 "default" 1 "off" 2 "on" 3 "invalid" ;
VAL_ 903 PSM_DrvStHghtDnDis 0 "default" 1 "off" 2 "on" 3 "invalid" ;
VAL_ 903 PSM_DrvStCushExtBckwdDis 0 "default" 1 "off" 2 "on" 3 "invalid" ;
VAL_ 903 PSM_DrvStCushExtFwdDis 0 "default" 1 "off" 2 "on" 3 "invalid" ;
VAL_ 903 PSM_DrvStSldBckwdDis 0 "default" 1 "off" 2 "on" 3 "invalid" ;
VAL_ 903 PSM_DrvStHdRstUpDis 0 "default" 1 "off" 2 "on" 3 "invalid" ;
VAL_ 903 PSM_DrvStHdRstDnDis 0 "default" 1 "off" 2 "on" 3 "invalid" ;
VAL_ 903 PSM_DrvStHdRstFwdDis 0 "default" 1 "off" 2 "on" 3 "invalid" ;
VAL_ 903 PSM_DrvStHdRstBckwdDis 0 "default" 1 "off" 2 "on" 3 "invalid" ;
VAL_ 903 PSM_DrvStLmbrDefDis 0 "default" 1 "off" 2 "on" 3 "invalid" ;
VAL_ 903 PSM_DrvStLmbrLoDis 0 "default" 1 "off" 2 "on" 3 "invalid" ;
VAL_ 903 PSM_DrvStLmbrMdlDis 0 "default" 1 "off" 2 "on" 3 "invalid" ;
VAL_ 903 PSM_DrvStLmbrUpDis 0 "default" 1 "off" 2 "on" 3 "invalid" ;
VAL_ 903 PSM_DrvStReclneFwdDis 0 "default" 1 "off" 2 "on" 3 "invalid" ;
VAL_ 903 PSM_LmbrSigSrcTyp 0 "not PSM" 1 "PSM" 2 "reserved" 3 "invalid" ;
VAL_ 903 PSM_DrvStReclneBckwdDis 0 "default" 1 "off" 2 "on" 3 "invalid" ;
VAL_ 903 PSM_DrvStTiltUpDis 0 "default" 1 "off" 2 "on" 3 "invalid" ;
VAL_ 904 PSM_DrvReclinePosition 0 "0x0x00~0xFE:POSITION" 254 "0x0x00~0xFE:POSITION" 255 "invalid" ;
VAL_ 904 PSM_EsyAcsGetOffSta 0 "off" 1 "on" 2 "Not Used" 3 "Error Indicator" ;
VAL_ 904 PSM_EsyAcsStpSta 0 "off" 1 "on" 2 "Not Used" 3 "Error Indicator" ;
VAL_ 904 PSM_LegRestCloseSta 0 "Default" 1 "Off" 2 "On(Close)" 3 "Invalid" ;
VAL_ 904 PSM_SWVerMajor1 0 "0x0x0~0x7F:ASCII Code Value (HEX)" 127 "0x0x0~0x7F:ASCII Code Value (HEX)" ;
VAL_ 904 PSM_SWVerMinor1 0 "0x0x0~0x7F:ASCII Code Value (HEX)" 127 "0x0x0~0x7F:ASCII Code Value (HEX)" ;
VAL_ 904 PSM_SWVerMinor2 0 "0x0x0~0x7F:ASCII Code Value (HEX)" 127 "0x0x0~0x7F:ASCII Code Value (HEX)" ;
VAL_ 904 PSM_DrvHeightPosition 0 "0x0x00~0xFE:POSITION" 254 "0x0x00~0xFE:POSITION" 255 "invalid" ;
VAL_ 904 PSM_DrvSlidePosition 0 "0x0x00~0xFE:POSITION" 254 "0x0x00~0xFE:POSITION" 255 "invalid" ;
VAL_ 904 PSM_EsyAcsGetOnSta 0 "off" 1 "on" 2 "Not Used" 3 "Error Indicator" ;
VAL_ 1003 PSM_BzrOnRLReq 0 "off" 1 "on" 2 "Not Used" 3 "Error Indicator" ;
VAL_ 1003 RLPSM_RearModeState 0 "Default" 1 "Off" 2 "Relax Mode" 3 "Return Mode" 4 "RESERVED" 5 "RESERVED" 6 "RESERVED" 7 "Invalid" ;
VAL_ 1003 RLPSM_RLStEsyAcsUSMSta 0 "Default" 1 "Off" 2 "On" 3 "Invalid" ;
VAL_ 1003 RLPSM_RLSlidePosition 0 "0x0x00~0xFE:POSITION" 254 "0x0x00~0xFE:POSITION" 255 "invalid" ;
VAL_ 1003 RLPSM_LimSetSta 0 "Default" 1 "Initialized" 2 "Not Initialized" 3 "Reserved" ;
VAL_ 2223056129 SAS_AnglVal 32767 "Error Indicator" ;
VAL_ 2223056129 SAS_SpdVal 255 "Error Indicator" ;
VAL_ 905 RR_CrashUnlockCmd 0 "Off" 1 "Unlock (Crash)" ;
VAL_ 905 Warn_RrRtDrSwSta_SBCM 0 "Close" 1 "Open" 2 "Not Used" 3 "Error Indicator" ;
VAL_ 905 DoorLock_RrRtDrUnLkSta_SBCM 0 "Lock" 1 "Unlock" 2 "Not Used" 3 "Error Indicator" ;
VAL_ 905 RR_SEAActivated 0 "InActivated" 1 "Activated" 2 "Not Used" 3 "Error Indicator" ;
VAL_ 905 RR_SEAWarn 0 "SEA Right Warning OFF" 1 "SEA Right Warning ON" 2 "Reserved" 3 "Invalid" ;
VAL_ 905 RR_SEWWarn 0 "SEW Right Warning OFF" 1 "SEW Right Warning ON" 2 "Reserved" 3 "Invalid" ;
VAL_ 905 RR_ReleaseWarn 0 "Release Warning OFF" 1 "Release Warning ON" 2 "Reserved" 3 "Invalid" ;
VAL_ 905 RR_SWFailAlarm 0 "Off" 1 "On" 2 "Not Used" 3 "Error Indicator" ;
VAL_ 905 RR_ChildLock_ActnFlSta 0 "OK" 1 "Failed" 2 "Not Used" 3 "Error Indicator" ;
VAL_ 905 RR_MRActivationAlarm 0 "Off" 1 "On" 2 "Not Used" 3 "Error Indicator" ;
VAL_ 905 RR_ChildLock_Status 0 "ChildLock On" 1 "ChildLock Off" 2 "Reserved" 3 "Not Used" ;
VAL_ 905 USM_RRGhostDoorSta 0 "Default" 1 "Off" 2 "On" 3 "Invalid" ;
VAL_ 905 DoorLock_PDSLkSwSta_RR 0 "Lock" 1 "Unlock" 2 "Not Used" 3 "Error Indicator" ;
VAL_ 905 PDS_TypeOption_RR 0 "Off" 1 "On" 2 "Not Used" 3 "Error Indicator" ;
VAL_ 905 SBCM_RrRrClsSwSta 0 "Default" 1 "On" 2 "Off" 3 "Error Indicator" ;
VAL_ 905 RRDoorPushAlarm 0 "Off" 1 "On" 2 "Not Used" 3 "Error Indicator" ;
